[part 11 of 23: package /Cluster]
AUTOSAR XML (schema 4-3-0)
package /Cluster  (continued)
  7 x lin cluster, all with baudrate=19200, protocol-name=LIN, protocol-version=2.0:  (continued)
    Klima_LIN3
      lin physical channel CHNL: comm-connectors=CN_Klima_LIN3
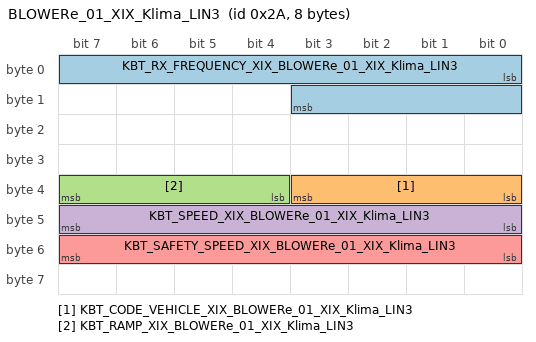
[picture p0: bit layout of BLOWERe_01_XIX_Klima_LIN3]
        frame BLOWERe_01_XIX_Klima_LIN3: id 0x2A, from Klima, frame-length=8, lin-checksum=ENHANCED
          pdu BLOWERe_01_XIX_Klima_LIN3: length=8, unused-bit-pattern=0
            signal KBT_RX_FREQUENCY_XIX_BLOWERe_01_XIX_Klima_LIN3: start 0, 12 bit, little-endian, data-type-policy=OVERRIDE, i-signal-type=PRIMITIVE, base-type=BT_KBT_RX_FREQUENCY, compu {phys=raw+150 for raw 0..1896, 4095=Cxfff_ungueltig (CM_KBT_RX_FREQUENCY_Cxfff_ungueltig); unit Unit_KiloHertz}, range phys 150..2046 Unit_KiloHertz, raw 0..4095, unit=Unit_KiloHertz, transfer-property=PENDING  # Radio Empfangsfrequenz bei AM_Empfang
            signal KBT_CODE_VEHICLE_XIX_BLOWERe_01_XIX_Klima_LIN3: start 32, 4 bit, little-endian, data-type-policy=OVERRIDE, i-signal-type=PRIMITIVE, init-value=0, base-type=BT_KBT_CODE_VEHICLE, compu {0=Cx0_Init (CM_KBT_CODE_VEHICLE_Cx0_Init), 1=Cx1_Q7_NF (CM_KBT_CODE_VEHICLE_Cx1_Q7_NF), 2=Cx2_B9 (CM_KBT_CODE_VEHICLE_Cx2_B9), 3=Cx3_D5 (CM_KBT_CODE_VEHICLE_Cx3_D5), 4=Cx4_C8 (CM_KBT_CODE_VEHICLE_Cx4_C8), 5=Cx5_Q5_NF (CM_KBT_CODE_VEHICLE_Cx5_Q5_NF), 6=Cx6_MSS (CM_KBT_CODE_VEHICLE_Cx6_MSS), 7=Cx7_Konzern_Fahrzeug (CM_KBT_CODE_VEHICLE_Cx7_Konzern_Fahrzeug)}, range raw 0..7, transfer-property=PENDING  # Vorgabe des Betriebszustandes für das Frischluftgebläse BLDC
            signal KBT_RAMP_XIX_BLOWERe_01_XIX_Klima_LIN3: start 36, 4 bit, little-endian, data-type-policy=OVERRIDE, i-signal-type=PRIMITIVE, base-type=BT_KBT_RAMP, compu {phys=raw*100+100 for raw 0..15; unit Unit_MinutInver}, range phys 100..1600 Unit_MinutInver, raw 0..15, unit=Unit_MinutInver, transfer-property=PENDING  # Vorgabe Rampenzeitkonstante für das Frischluftgebläse BLDC
            signal KBT_SPEED_XIX_BLOWERe_01_XIX_Klima_LIN3: start 40, 8 bit, little-endian, data-type-policy=OVERRIDE, i-signal-type=PRIMITIVE, init-value=1, base-type=BT_KBT_SPEED, invalid-value=Invalid_KBT_SPEED_XIX_BLOWERe_01_XIX_Klima_LIN3:255, compu {0=Cx0_Sofort_Abschaltung_ohne_Rampe (CM_KBT_SPEED_Cx0_Sofort_Abschaltung_ohne_Rampe), 1=Cx1_Abschaltung_mit_Rampe (CM_KBT_SPEED_Cx1_Abschaltung_mit_Rampe), phys=raw*20 for raw 20..253, 254=Cxfe_reserviert (CM_KBT_SPEED_Cxfe_reserviert), 255=Cxff_Fehler (CM_KBT_SPEED_Cxff_Fehler); unit Unit_MinutInver}, range phys 400..5060 Unit_MinutInver, raw 0..255, unit=Unit_MinutInver, transfer-property=PENDING  # Vorgabe Sollwert Motordrehzahl für das Frischluftgebläse BLDC
            signal KBT_SAFETY_SPEED_XIX_BLOWERe_01_XIX_Klima_LIN3: start 48, 8 bit, little-endian, data-type-policy=OVERRIDE, i-signal-type=PRIMITIVE, init-value=200, base-type=BT_KBT_SAFETY_SPEED, invalid-value=Invalid_KBT_SAFETY_SPEED_XIX_BLOWERe_01_XIX_Klima_LIN3:255, compu {phys=raw*20 for raw 0..253, 254=Cxfe_reserviert (CM_KBT_SAFETY_SPEED_Cxfe_reserviert), 255=Cxff_Fehler (CM_KBT_SAFETY_SPEED_Cxff_Fehler); unit Unit_MinutInver}, range phys 0..5060 Unit_MinutInver, raw 0..255, unit=Unit_MinutInver, transfer-property=PENDING  # Vorgabe Sollwert Notlaufmotordrehzahl für das Frischluftgebläse BLDC
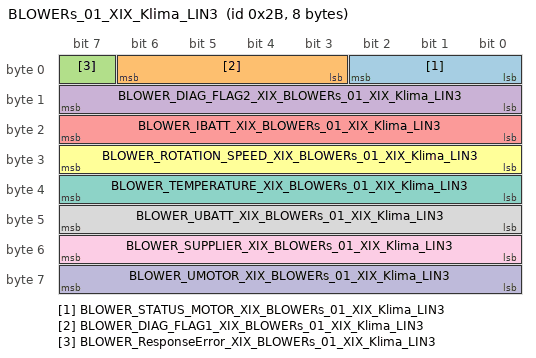
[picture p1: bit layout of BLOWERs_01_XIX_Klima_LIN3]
        frame BLOWERs_01_XIX_Klima_LIN3: id 0x2B, to Klima, frame-length=8, lin-checksum=ENHANCED
          pdu BLOWERs_01_XIX_Klima_LIN3: length=8, unused-bit-pattern=0
            signal BLOWER_STATUS_MOTOR_XIX_BLOWERs_01_XIX_Klima_LIN3: start 0, 3 bit, little-endian, data-type-policy=OVERRIDE, i-signal-type=PRIMITIVE, init-value=0, base-type=BT_BLOWER_STATUS_MOTOR, compu {0=Cx0_Init (CM_BLOWER_STATUS_MOTOR_Cx0_Init), 1=Cx1_Strombegrenzung_aktiv (CM_BLOWER_STATUS_MOTOR_Cx1_Strombegrenzung_aktiv), 2=Cx2_Sollwert_erreicht (CM_BLOWER_STATUS_MOTOR_Cx2_Sollwert_erreicht), 4=Cx4_Notlauf_aktiviert (CM_BLOWER_STATUS_MOTOR_Cx4_Notlauf_aktiviert)}, range raw 0..4, transfer-property=PENDING, to Klima(timeout 3.5 s)  # Status Motor des Frischlufgebläse BLDC
            signal BLOWER_DIAG_FLAG1_XIX_BLOWERs_01_XIX_Klima_LIN3: start 3, 4 bit, little-endian, data-type-policy=OVERRIDE, i-signal-type=PRIMITIVE, base-type=BT_BLOWER_DIAG_FLAG1, compu {0=Cx0_Init (CM_BLOWER_DIAG_FLAG1_Cx0_Init), 1=Cx1_Kurzschluss (CM_BLOWER_DIAG_FLAG1_Cx1_Kurzschluss), 2=Cx2_Fehler_Temperatur_Sensor (CM_BLOWER_DIAG_FLAG1_Cx2_Fehler_Temperatur_Sensor), 4=Cx4_Fehler_Brueckentreiber (CM_BLOWER_DIAG_FLAG1_Cx4_Fehler_Brueckentreiber), 8=Cx8_Brueckentreiber_Uebertemperatur (CM_BLOWER_DIAG_FLAG1_Cx8_Brueckentreiber_Uebertemperatur)}, range raw 0..8, transfer-property=PENDING, to Klima(timeout 3.5 s)  # Status Diagnose 1 des Frischluftgbläse BLDC
            signal BLOWER_ResponseError_XIX_BLOWERs_01_XIX_Klima_LIN3: start 7, 1 bit, little-endian, data-type-policy=OVERRIDE, i-signal-type=PRIMITIVE, init-value=0, base-type=BT_BLOWER_ResponseError, invalid-value=Invalid_BLOWER_ResponseError_XIX_BLOWERs_01_XIX_Klima_LIN3:1, compu {0=Cx0_kein_Fehler (CM_BLOWER_ResponseError_Cx0_kein_Fehler), 1=Cx1_Fehler (CM_BLOWER_ResponseError_Cx1_Fehler)}, range raw 0..1, transfer-property=PENDING, to Klima(timeout 3.5 s)  # siehe LIN2.0-Specification (Darf nicht über ein Fehlergueltigkeitsbit abgesichtert werden!)
            signal BLOWER_DIAG_FLAG2_XIX_BLOWERs_01_XIX_Klima_LIN3: start 8, 8 bit, little-endian, data-type-policy=OVERRIDE, i-signal-type=PRIMITIVE, base-type=BT_BLOWER_DIAG_FLAG2, compu {0=Cx0_Init (CM_BLOWER_DIAG_FLAG2_Cx0_Init), 1=Cx1_interner_Fehler_detektiert_Notabschaltung (CM_BLOWER_DIAG_FLAG2_Cx1_interner_Fehler_detektiert_Notabschaltung), 2=Cx2_Blockade_Motor (CM_BLOWER_DIAG_FLAG2_Cx2_Blockade_Motor), 4=Cx4_Uebertemperatur (CM_BLOWER_DIAG_FLAG2_Cx4_Uebertemperatur), 8=Cx8_Ueberstrom_Motor (CM_BLOWER_DIAG_FLAG2_Cx8_Ueberstrom_Motor), 16=Cx10_Ueberstrom_Batterie (CM_BLOWER_DIAG_FLAG2_Cx10_Ueberstrom_Batterie), 32=Cx20_Strom_Offset_Fehler (CM_BLOWER_DIAG_FLAG2_Cx20_Strom_Offset_Fehler), 64=Cx40_Ueberspannung_Abschaltung (CM_BLOWER_DIAG_FLAG2_Cx40_Ueberspannung_Abschaltung), 128=Cx80_Unterspannung_Abschaltung (CM_BLOWER_DIAG_FLAG2_Cx80_Unterspannung_Abschaltung)}, range raw 0..128, transfer-property=PENDING, to Klima(timeout 3.5 s)  # Status Diagnose 2 des Frischluftgbläse BLDC
            signal BLOWER_IBATT_XIX_BLOWERs_01_XIX_Klima_LIN3: start 16, 8 bit, little-endian, data-type-policy=OVERRIDE, i-signal-type=PRIMITIVE, base-type=BT_BLOWER_IBATT, compu {phys=raw*0.15 for raw 0..253, 254=Cxfe_kein_Messwert_verfuegbar (CM_BLOWER_IBATT_Cxfe_kein_Messwert_verfuegbar), 255=Cxff_Fehler_Strommesseinrichtung (CM_BLOWER_IBATT_Cxff_Fehler_Strommesseinrichtung); unit Unit_Amper}, range phys 0..37.95 Unit_Amper, raw 0..255, unit=Unit_Amper, transfer-property=PENDING, to Klima(timeout 3.5 s)  # Stromaufnahme des Frischluftgbläse BLDC
            signal BLOWER_ROTATION_SPEED_XIX_BLOWERs_01_XIX_Klima_LIN3: start 24, 8 bit, little-endian, data-type-policy=OVERRIDE, i-signal-type=PRIMITIVE, base-type=BT_BLOWER_ROTATION_SPEED, compu {phys=raw*20 for raw 0..253, 254=Cxfe_kein_Messwert_verfuegbar (CM_BLOWER_ROTATION_SPEED_Cxfe_kein_Messwert_verfuegbar), 255=Cxff_Fehler_Drehzahlmesseinrichtung (CM_BLOWER_ROTATION_SPEED_Cxff_Fehler_Drehzahlmesseinrichtung); unit Unit_MinutInver}, range phys 0..5060 Unit_MinutInver, raw 0..255, unit=Unit_MinutInver, transfer-property=PENDING, to Klima(timeout 3.5 s)  # Drehzahl des Frischluftgebläse BLDC
            signal BLOWER_TEMPERATURE_XIX_BLOWERs_01_XIX_Klima_LIN3: start 32, 8 bit, little-endian, data-type-policy=OVERRIDE, i-signal-type=PRIMITIVE, init-value=0, base-type=BT_BLOWER_TEMPERATURE, invalid-value=Invalid_BLOWER_TEMPERATURE_XIX_BLOWERs_01_XIX_Klima_LIN3:255, compu {phys=raw-40 for raw 0..190, 254=Cxfe_kein_Messwert_verfuegbar (CM_BLOWER_TEMPERATURE_Cxfe_kein_Messwert_verfuegbar), 255=Cxff_Fehler (CM_BLOWER_TEMPERATURE_Cxff_Fehler); unit Unit_DegreCelsi}, range phys -40..150 Unit_DegreCelsi, raw 0..255, unit=Unit_DegreCelsi, transfer-property=PENDING, to Klima(timeout 3.5 s)  # Temperatur des Frischluftgebläse BLDC
            signal BLOWER_UBATT_XIX_BLOWERs_01_XIX_Klima_LIN3: start 40, 8 bit, little-endian, data-type-policy=OVERRIDE, i-signal-type=PRIMITIVE, base-type=BT_BLOWER_UBATT, compu {phys=raw*0.1 for raw 0..253, 254=Cxfe_kein_Messwert_verfuegbar (CM_BLOWER_UBATT_Cxfe_kein_Messwert_verfuegbar), 255=Cxff_Fehler_Spannungsmesseinrichtung (CM_BLOWER_UBATT_Cxff_Fehler_Spannungsmesseinrichtung); unit Unit_Volt}, range phys 0..25.3 Unit_Volt, raw 0..255, unit=Unit_Volt, transfer-property=PENDING, to Klima(timeout 3.5 s)  # Spannung am Frischluftgebläse BLDC Ubatt (Klemme)
            signal BLOWER_SUPPLIER_XIX_BLOWERs_01_XIX_Klima_LIN3: start 48, 8 bit, little-endian, data-type-policy=OVERRIDE, i-signal-type=PRIMITIVE, init-value=0, base-type=BT_BLOWER_SUPPLIER, compu {0=Cx0_Init (CM_BLOWER_SUPPLIER_Cx0_Init), 31=Cx1f_BROSE (CM_BLOWER_SUPPLIER_Cx1f_BROSE), 37=Cx25_ASMO (CM_BLOWER_SUPPLIER_Cx25_ASMO), 64=Cx40_BOSCH (CM_BLOWER_SUPPLIER_Cx40_BOSCH)}, range raw 0..64, transfer-property=PENDING, to Klima(timeout 3.5 s)  # Hersteller-Nummer des Frischluftgebläse BLDC
            signal BLOWER_UMOTOR_XIX_BLOWERs_01_XIX_Klima_LIN3: start 56, 8 bit, little-endian, data-type-policy=OVERRIDE, i-signal-type=PRIMITIVE, base-type=BT_BLOWER_UMOTOR, compu {phys=raw*0.1 for raw 0..253, 254=Cxfe_kein_Messwert_verfuegbar (CM_BLOWER_UMOTOR_Cxfe_kein_Messwert_verfuegbar), 255=Cxff_Fehler_Spannungsmesseinrichtung (CM_BLOWER_UMOTOR_Cxff_Fehler_Spannungsmesseinrichtung); unit Unit_Volt}, range phys 0..25.3 Unit_Volt, raw 0..255, unit=Unit_Volt, transfer-property=PENDING, to Klima(timeout 3.5 s)  # Phasenspannung Motor des Frischluftgebläse BLDC
        frame BLOWERs_02_XIX_Klima_LIN3: id 0x2E, to Klima, frame-length=8, lin-checksum=ENHANCED
          pdu BLOWERs_02_XIX_Klima_LIN3: length=8, unused-bit-pattern=0
            signal BLOWER_TORQUE_XIX_BLOWERs_02_XIX_Klima_LIN3: start 0, 10 bit, little-endian, data-type-policy=OVERRIDE, i-signal-type=PRIMITIVE, init-value=1022, base-type=BT_BLOWER_TORQUE, invalid-value=Invalid_BLOWER_TORQUE_XIX_BLOWERs_02_XIX_Klima_LIN3:1023, compu {phys=raw*0.001 for raw 0..1021, 1022=Cx3fe_Init (CM_BLOWER_TORQUE_Cx3fe_Init), 1023=Cx3ff_Fehler (CM_BLOWER_TORQUE_Cx3ff_Fehler); unit Unit_NewtoMeter}, range phys 0..1.021 Unit_NewtoMeter, raw 0..1023, unit=Unit_NewtoMeter, transfer-property=PENDING, to Klima(timeout 3.5 s)  # Drehmoment des Frischluftgebläse BLDC
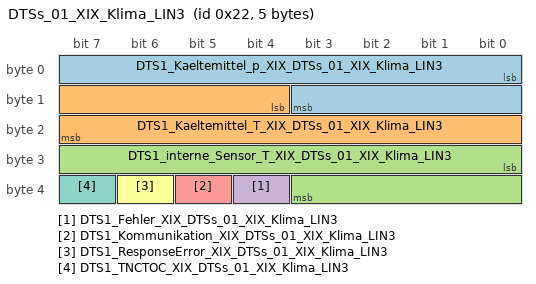
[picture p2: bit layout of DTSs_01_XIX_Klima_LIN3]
        frame DTSs_01_XIX_Klima_LIN3: id 0x22, to Klima, frame-length=5, lin-checksum=ENHANCED
          pdu DTSs_01_XIX_Klima_LIN3: length=5, unused-bit-pattern=0
            signal DTS1_Kaeltemittel_p_XIX_DTSs_01_XIX_Klima_LIN3: start 0, 12 bit, little-endian, data-type-policy=OVERRIDE, i-signal-type=PRIMITIVE, init-value=4094, base-type=BT_DTS1_Kaeltemittel_p, invalid-value=Invalid_DTS1_Kaeltemittel_p_XIX_DTSs_01_XIX_Klima_LIN3:4095, compu {phys=raw*0.0088 for raw 0..4093, 4094=Cxffe_Init (CM_DTS1_Kaeltemittel_p_Cxffe_Init), 4095=Cxfff_Fehler (CM_DTS1_Kaeltemittel_p_Cxfff_Fehler); unit Unit_Bar}, range phys 0..36.0184 Unit_Bar, raw 0..4095, unit=Unit_Bar, transfer-property=PENDING, to Klima(timeout 3.5 s)  # Kaetemitteldruck absolut
            signal DTS1_Kaeltemittel_T_XIX_DTSs_01_XIX_Klima_LIN3: start 12, 12 bit, little-endian, data-type-policy=OVERRIDE, i-signal-type=PRIMITIVE, init-value=4094, base-type=BT_DTS1_Kaeltemittel_T, invalid-value=Invalid_DTS1_Kaeltemittel_T_XIX_DTSs_01_XIX_Klima_LIN3:4095, compu {phys=raw*0.1-40 for raw 0..1900, 4094=Cxffe_Init (CM_DTS1_Kaeltemittel_T_Cxffe_Init), 4095=Cxfff_Fehler (CM_DTS1_Kaeltemittel_T_Cxfff_Fehler); unit Unit_DegreCelsi}, range phys -40..150 Unit_DegreCelsi, raw 0..4095, unit=Unit_DegreCelsi, transfer-property=PENDING, to Klima(timeout 3.5 s)  # Kältemitteltemperatur
            signal DTS1_interne_Sensor_T_XIX_DTSs_01_XIX_Klima_LIN3: start 24, 12 bit, little-endian, data-type-policy=OVERRIDE, i-signal-type=PRIMITIVE, init-value=4094, base-type=BT_DTS1_interne_Sensor_T, invalid-value=Invalid_DTS1_interne_Sensor_T_XIX_DTSs_01_XIX_Klima_LIN3:4095, compu {phys=raw*0.1-40 for raw 0..1800, 4094=Cxffe_Init (CM_DTS1_interne_Sensor_T_Cxffe_Init), 4095=Cxfff_Fehler (CM_DTS1_interne_Sensor_T_Cxfff_Fehler); unit Unit_DegreCelsi}, range phys -40..140 Unit_DegreCelsi, raw 0..4095, unit=Unit_DegreCelsi, transfer-property=PENDING, to Klima(timeout 3.5 s)  # interne Sensor-Temperatur
            signal DTS1_Fehler_XIX_DTSs_01_XIX_Klima_LIN3: start 36, 1 bit, little-endian, data-type-policy=OVERRIDE, i-signal-type=PRIMITIVE, init-value=0, base-type=BT_DTS1_Fehler, invalid-value=Invalid_DTS1_Fehler_XIX_DTSs_01_XIX_Klima_LIN3:1, compu {0=Cx0_kein_Fehler (CM_DTS1_Fehler_Cx0_kein_Fehler), 1=Cx1_Fehler (CM_DTS1_Fehler_Cx1_Fehler)}, range raw 0..1, transfer-property=PENDING, to Klima(timeout 3.5 s)  # Interner Sensorfehler
            signal DTS1_Kommunikation_XIX_DTSs_01_XIX_Klima_LIN3: start 37, 1 bit, little-endian, data-type-policy=OVERRIDE, i-signal-type=PRIMITIVE, init-value=0, base-type=BT_DTS1_Kommunikation, invalid-value=Invalid_DTS1_Kommunikation_XIX_DTSs_01_XIX_Klima_LIN3:1, compu {0=Cx0_kein_Fehler (CM_DTS1_Kommunikation_Cx0_kein_Fehler), 1=Cx1_Fehler (CM_DTS1_Kommunikation_Cx1_Fehler)}, range raw 0..1, transfer-property=PENDING, to Klima(timeout 3.5 s)  # Checksummenfehler
            signal DTS1_ResponseError_XIX_DTSs_01_XIX_Klima_LIN3: start 38, 1 bit, little-endian, data-type-policy=OVERRIDE, i-signal-type=PRIMITIVE, init-value=0, base-type=BT_DTS1_ResponseError, invalid-value=Invalid_DTS1_ResponseError_XIX_DTSs_01_XIX_Klima_LIN3:1, compu {0=Cx0_kein_Fehler (CM_DTS1_ResponseError_Cx0_kein_Fehler), 1=Cx1_Fehler (CM_DTS1_ResponseError_Cx1_Fehler)}, range raw 0..1, transfer-property=PENDING, to Klima(timeout 3.5 s)  # Response Error
            signal DTS1_TNCTOC_XIX_DTSs_01_XIX_Klima_LIN3: start 39, 1 bit, little-endian, data-type-policy=OVERRIDE, i-signal-type=PRIMITIVE, init-value=1, base-type=BT_DTS1_TNCTOC, compu {0=Cx0_DTC_test_completed_this_operation_cylce (CM_DTS1_TNCTOC_Cx0_DTC_test_completed_this_operation_cylce), 1=Cx1_DTC_test_not_completed_this_operation_cylce (CM_DTS1_TNCTOC_Cx1_DTC_test_not_completed_this_operation_cylce)}, range raw 0..1, transfer-property=PENDING, to Klima(timeout 3.5 s)  # testNotCompletedThisOperationCycle (TNCTOC)
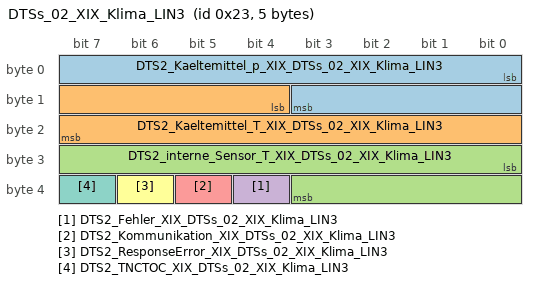
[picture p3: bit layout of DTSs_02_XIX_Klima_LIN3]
        frame DTSs_02_XIX_Klima_LIN3: id 0x23, to Klima, frame-length=5, lin-checksum=ENHANCED
          pdu DTSs_02_XIX_Klima_LIN3: length=5, unused-bit-pattern=0
            signal DTS2_Kaeltemittel_p_XIX_DTSs_02_XIX_Klima_LIN3: start 0, 12 bit, little-endian, data-type-policy=OVERRIDE, i-signal-type=PRIMITIVE, init-value=4094, base-type=BT_DTS2_Kaeltemittel_p, invalid-value=Invalid_DTS2_Kaeltemittel_p_XIX_DTSs_02_XIX_Klima_LIN3:4095, compu {phys=raw*0.0088 for raw 0..4093, 4094=Cxffe_Init (CM_DTS2_Kaeltemittel_p_Cxffe_Init), 4095=Cxfff_Fehler (CM_DTS2_Kaeltemittel_p_Cxfff_Fehler); unit Unit_Bar}, range phys 0..36.0184 Unit_Bar, raw 0..4095, unit=Unit_Bar, transfer-property=PENDING, to Klima(timeout 3.5 s)  # Kaetemitteldruck absolut
            signal DTS2_Kaeltemittel_T_XIX_DTSs_02_XIX_Klima_LIN3: start 12, 12 bit, little-endian, data-type-policy=OVERRIDE, i-signal-type=PRIMITIVE, init-value=4094, base-type=BT_DTS2_Kaeltemittel_T, invalid-value=Invalid_DTS2_Kaeltemittel_T_XIX_DTSs_02_XIX_Klima_LIN3:4095, compu {phys=raw*0.1-40 for raw 0..1900, 4094=Cxffe_Init (CM_DTS2_Kaeltemittel_T_Cxffe_Init), 4095=Cxfff_Fehler (CM_DTS2_Kaeltemittel_T_Cxfff_Fehler); unit Unit_DegreCelsi}, range phys -40..150 Unit_DegreCelsi, raw 0..4095, unit=Unit_DegreCelsi, transfer-property=PENDING, to Klima(timeout 3.5 s)  # Kältemitteltemperatur
            signal DTS2_interne_Sensor_T_XIX_DTSs_02_XIX_Klima_LIN3: start 24, 12 bit, little-endian, data-type-policy=OVERRIDE, i-signal-type=PRIMITIVE, init-value=4094, base-type=BT_DTS2_interne_Sensor_T, invalid-value=Invalid_DTS2_interne_Sensor_T_XIX_DTSs_02_XIX_Klima_LIN3:4095, compu {phys=raw*0.1-40 for raw 0..1800, 4094=Cxffe_Init (CM_DTS2_interne_Sensor_T_Cxffe_Init), 4095=Cxfff_Fehler (CM_DTS2_interne_Sensor_T_Cxfff_Fehler); unit Unit_DegreCelsi}, range phys -40..140 Unit_DegreCelsi, raw 0..4095, unit=Unit_DegreCelsi, transfer-property=PENDING, to Klima(timeout 3.5 s)  # interne Sensor-Temperatur
            signal DTS2_Fehler_XIX_DTSs_02_XIX_Klima_LIN3: start 36, 1 bit, little-endian, data-type-policy=OVERRIDE, i-signal-type=PRIMITIVE, init-value=0, base-type=BT_DTS2_Fehler, invalid-value=Invalid_DTS2_Fehler_XIX_DTSs_02_XIX_Klima_LIN3:1, compu {0=Cx0_kein_Fehler (CM_DTS2_Fehler_Cx0_kein_Fehler), 1=Cx1_Fehler (CM_DTS2_Fehler_Cx1_Fehler)}, range raw 0..1, transfer-property=PENDING, to Klima(timeout 3.5 s)  # Interner Sensorfehler
            signal DTS2_Kommunikation_XIX_DTSs_02_XIX_Klima_LIN3: start 37, 1 bit, little-endian, data-type-policy=OVERRIDE, i-signal-type=PRIMITIVE, init-value=0, base-type=BT_DTS2_Kommunikation, invalid-value=Invalid_DTS2_Kommunikation_XIX_DTSs_02_XIX_Klima_LIN3:1, compu {0=Cx0_kein_Fehler (CM_DTS2_Kommunikation_Cx0_kein_Fehler), 1=Cx1_Fehler (CM_DTS2_Kommunikation_Cx1_Fehler)}, range raw 0..1, transfer-property=PENDING, to Klima(timeout 3.5 s)  # Checksummenfehler
            signal DTS2_ResponseError_XIX_DTSs_02_XIX_Klima_LIN3: start 38, 1 bit, little-endian, data-type-policy=OVERRIDE, i-signal-type=PRIMITIVE, init-value=0, base-type=BT_DTS2_ResponseError, invalid-value=Invalid_DTS2_ResponseError_XIX_DTSs_02_XIX_Klima_LIN3:1, compu {0=Cx0_normal (CM_DTS2_ResponseError_Cx0_normal), 1=Cx1_Fehler (CM_DTS2_ResponseError_Cx1_Fehler)}, range raw 0..1, transfer-property=PENDING, to Klima(timeout 3.5 s)  # siehe LIN2.0-Specification (Darf nicht über ein Fehlergueltigkeitsbit abgesichtert werden!)
            signal DTS2_TNCTOC_XIX_DTSs_02_XIX_Klima_LIN3: start 39, 1 bit, little-endian, data-type-policy=OVERRIDE, i-signal-type=PRIMITIVE, init-value=1, base-type=BT_DTS2_TNCTOC, compu {0=Cx0_DTC_test_completed_this_operation_cylce (CM_DTS2_TNCTOC_Cx0_DTC_test_completed_this_operation_cylce), 1=Cx1_DTC_test_not_completed_this_operation_cylce (CM_DTS2_TNCTOC_Cx1_DTC_test_not_completed_this_operation_cylce)}, range raw 0..1, transfer-property=PENDING, to Klima(timeout 3.5 s)  # testNotCompletedThisOperationCycle (TNCTOC)
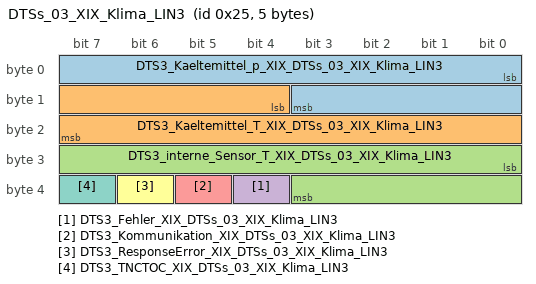
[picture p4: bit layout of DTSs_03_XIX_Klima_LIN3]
        frame DTSs_03_XIX_Klima_LIN3: id 0x25, to Klima, frame-length=5, lin-checksum=ENHANCED
          pdu DTSs_03_XIX_Klima_LIN3: length=5, unused-bit-pattern=0
            signal DTS3_Kaeltemittel_p_XIX_DTSs_03_XIX_Klima_LIN3: start 0, 12 bit, little-endian, data-type-policy=OVERRIDE, i-signal-type=PRIMITIVE, init-value=4094, base-type=BT_DTS3_Kaeltemittel_p, invalid-value=Invalid_DTS3_Kaeltemittel_p_XIX_DTSs_03_XIX_Klima_LIN3:4095, compu {phys=raw*0.0088 for raw 0..4093, 4094=Cxffe_Init (CM_DTS3_Kaeltemittel_p_Cxffe_Init), 4095=Cxfff_Fehler (CM_DTS3_Kaeltemittel_p_Cxfff_Fehler); unit Unit_Bar}, range phys 0..36.0184 Unit_Bar, raw 0..4095, unit=Unit_Bar, transfer-property=PENDING, to Klima(timeout 3.5 s)  # Kaetemitteldruck absolut
            signal DTS3_Kaeltemittel_T_XIX_DTSs_03_XIX_Klima_LIN3: start 12, 12 bit, little-endian, data-type-policy=OVERRIDE, i-signal-type=PRIMITIVE, init-value=4094, base-type=BT_DTS3_Kaeltemittel_T, invalid-value=Invalid_DTS3_Kaeltemittel_T_XIX_DTSs_03_XIX_Klima_LIN3:4095, compu {phys=raw*0.1-40 for raw 0..1900, 4094=Cxffe_Init (CM_DTS3_Kaeltemittel_T_Cxffe_Init), 4095=Cxfff_Fehler (CM_DTS3_Kaeltemittel_T_Cxfff_Fehler); unit Unit_DegreCelsi}, range phys -40..150 Unit_DegreCelsi, raw 0..4095, unit=Unit_DegreCelsi, transfer-property=PENDING, to Klima(timeout 3.5 s)  # Kältemitteltemperatur
            signal DTS3_interne_Sensor_T_XIX_DTSs_03_XIX_Klima_LIN3: start 24, 12 bit, little-endian, data-type-policy=OVERRIDE, i-signal-type=PRIMITIVE, init-value=4094, base-type=BT_DTS3_interne_Sensor_T, invalid-value=Invalid_DTS3_interne_Sensor_T_XIX_DTSs_03_XIX_Klima_LIN3:4095, compu {phys=raw*0.1-40 for raw 0..1800, 4094=Cxffe_Init (CM_DTS3_interne_Sensor_T_Cxffe_Init), 4095=Cxfff_Fehler (CM_DTS3_interne_Sensor_T_Cxfff_Fehler); unit Unit_DegreCelsi}, range phys -40..140 Unit_DegreCelsi, raw 0..4095, unit=Unit_DegreCelsi, transfer-property=PENDING, to Klima(timeout 3.5 s)  # interne Sensor-Temperatur
            signal DTS3_Fehler_XIX_DTSs_03_XIX_Klima_LIN3: start 36, 1 bit, little-endian, data-type-policy=OVERRIDE, i-signal-type=PRIMITIVE, init-value=0, base-type=BT_DTS3_Fehler, invalid-value=Invalid_DTS3_Fehler_XIX_DTSs_03_XIX_Klima_LIN3:1, compu {0=Cx0_kein_Fehler (CM_DTS3_Fehler_Cx0_kein_Fehler), 1=Cx1_Fehler (CM_DTS3_Fehler_Cx1_Fehler)}, range raw 0..1, transfer-property=PENDING, to Klima(timeout 3.5 s)  # Interner Sensorfehler
            signal DTS3_Kommunikation_XIX_DTSs_03_XIX_Klima_LIN3: start 37, 1 bit, little-endian, data-type-policy=OVERRIDE, i-signal-type=PRIMITIVE, init-value=0, base-type=BT_DTS3_Kommunikation, invalid-value=Invalid_DTS3_Kommunikation_XIX_DTSs_03_XIX_Klima_LIN3:1, compu {0=Cx0_kein_Fehler (CM_DTS3_Kommunikation_Cx0_kein_Fehler), 1=Cx1_Fehler (CM_DTS3_Kommunikation_Cx1_Fehler)}, range raw 0..1, transfer-property=PENDING, to Klima(timeout 3.5 s)  # Checksummenfehler
            signal DTS3_ResponseError_XIX_DTSs_03_XIX_Klima_LIN3: start 38, 1 bit, little-endian, data-type-policy=OVERRIDE, i-signal-type=PRIMITIVE, init-value=0, base-type=BT_DTS3_ResponseError, invalid-value=Invalid_DTS3_ResponseError_XIX_DTSs_03_XIX_Klima_LIN3:1, compu {0=Cx0_normal (CM_DTS3_ResponseError_Cx0_normal), 1=Cx1_Fehler (CM_DTS3_ResponseError_Cx1_Fehler)}, range raw 0..1, transfer-property=PENDING, to Klima(timeout 3.5 s)  # siehe LIN2.0-Specification (Darf nicht über ein Fehlergueltigkeitsbit abgesichtert werden!)
            signal DTS3_TNCTOC_XIX_DTSs_03_XIX_Klima_LIN3: start 39, 1 bit, little-endian, data-type-policy=OVERRIDE, i-signal-type=PRIMITIVE, init-value=1, base-type=BT_DTS3_TNCTOC, compu {0=Cx0_DTC_test_completed_this_operation_cylce (CM_DTS3_TNCTOC_Cx0_DTC_test_completed_this_operation_cylce), 1=Cx1_DTC_test_not_completed_this_operation_cylce (CM_DTS3_TNCTOC_Cx1_DTC_test_not_completed_this_operation_cylce)}, range raw 0..1, transfer-property=PENDING, to Klima(timeout 3.5 s)  # testNotCompletedThisOperationCycle (TNCTOC)
        frame EKK4s_01_XIX_Klima_LIN3: id 0xB, to Klima, frame-length=8, lin-checksum=ENHANCED
          pdu EKK4s_01_XIX_Klima_LIN3: length=8, unused-bit-pattern=0
            signal EKK4_MUX_Err_Ind_XIX_EKK4s_01_XIX_Klima_LIN3: start 0, 2 bit, little-endian, data-type-policy=OVERRIDE, i-signal-type=PRIMITIVE, init-value=0, base-type=BT_EKK4_MUX_Err_Ind, compu {0=Cx0_Kennnummer_1_7_von_Err_Ind_Err (CM_EKK4_MUX_Err_Ind_Cx0_Kennnummer_1_7_von_Err_Ind_Err), 1=Cx1_Kennnummer_8_14_von_Err_Ind_Err (CM_EKK4_MUX_Err_Ind_Cx1_Kennnummer_8_14_von_Err_Ind_Err), 2=Cx2_Kennnummer_15_21_von_Err_Ind_Err (CM_EKK4_MUX_Err_Ind_Cx2_Kennnummer_15_21_von_Err_Ind_Err), 3=Cx3_Kennnummer_22_28_von_Err_Ind_Err (CM_EKK4_MUX_Err_Ind_Cx3_Kennnummer_22_28_von_Err_Ind_Err)}, range raw 0..3, transfer-property=PENDING, to Klima(timeout 3.5 s)  # Das Signal MUX_Err_Ind ist der Multiplexer für die gemultiplexten Signale Err_Ind_Nr_n_n+7_n+14_n+21.
            signal EKK4_Err_Ind_Nr_1_8_15_22_XIX_EKK4s_01_XIX_Klima_LIN3: start 2, 2 bit, little-endian, data-type-policy=OVERRIDE, i-signal-type=PRIMITIVE, init-value=0, base-type=BT_EKK4_Err_Ind_Nr_1_8_15_22, compu {0=Cx0_TNCTOC (CM_EKK4_Err_Ind_Nr_1_8_15_22_Cx0_TNCTOC), 1=Cx1_TP_TC (CM_EKK4_Err_Ind_Nr_1_8_15_22_Cx1_TP_TC), 2=Cx2_not_supported (CM_EKK4_Err_Ind_Nr_1_8_15_22_Cx2_not_supported), 3=Cx3_TF_TC (CM_EKK4_Err_Ind_Nr_1_8_15_22_Cx3_TF_TC)}, range raw 0..3, transfer-property=PENDING, to Klima(timeout 3.5 s)  # Über die gemultiplexten Signale Err_Ind_Nr_n_n+7_n+14_n+21 werden die Fehlerzustände der einzelnen Fehlerorte ausgegeben. Das zugehörige Multiplexsignal lautet MUX_Err_Ind.
            signal EKK4_Err_Ind_Nr_2_9_16_23_XIX_EKK4s_01_XIX_Klima_LIN3: start 4, 2 bit, little-endian, data-type-policy=OVERRIDE, i-signal-type=PRIMITIVE, init-value=0, base-type=BT_EKK4_Err_Ind_Nr_2_9_16_23, compu {0=Cx0_TNCTOC (CM_EKK4_Err_Ind_Nr_2_9_16_23_Cx0_TNCTOC), 1=Cx1_TP_TC (CM_EKK4_Err_Ind_Nr_2_9_16_23_Cx1_TP_TC), 2=Cx2_not_supported (CM_EKK4_Err_Ind_Nr_2_9_16_23_Cx2_not_supported), 3=Cx3_TF_TC (CM_EKK4_Err_Ind_Nr_2_9_16_23_Cx3_TF_TC)}, range raw 0..3, transfer-property=PENDING, to Klima(timeout 3.5 s)  # Über die gemultiplexten Signale Err_Ind_Nr_n_n+7_n+14_n+21 werden die Fehlerzustände der einzelnen Fehlerorte ausgegeben. Das zugehörige Multiplexsignal lautet MUX_Err_Ind.
            signal EKK4_Err_Ind_Nr_3_10_17_24_XIX_EKK4s_01_XIX_Klima_LIN3: start 6, 2 bit, little-endian, data-type-policy=OVERRIDE, i-signal-type=PRIMITIVE, init-value=0, base-type=BT_EKK4_Err_Ind_Nr_3_10_17_24, compu {0=Cx0_TNCTOC (CM_EKK4_Err_Ind_Nr_3_10_17_24_Cx0_TNCTOC), 1=Cx1_TP_TC (CM_EKK4_Err_Ind_Nr_3_10_17_24_Cx1_TP_TC), 2=Cx2_not_supported (CM_EKK4_Err_Ind_Nr_3_10_17_24_Cx2_not_supported), 3=Cx3_TF_TC (CM_EKK4_Err_Ind_Nr_3_10_17_24_Cx3_TF_TC)}, range raw 0..3, transfer-property=PENDING, to Klima(timeout 3.5 s)  # Über die gemultiplexten Signale Err_Ind_Nr_n_n+7_n+14_n+21 werden die Fehlerzustände der einzelnen Fehlerorte ausgegeben. Das zugehörige Multiplexsignal lautet MUX_Err_Ind.
            signal EKK4_Err_Ind_Nr_4_11_18_25_XIX_EKK4s_01_XIX_Klima_LIN3: start 8, 2 bit, little-endian, data-type-policy=OVERRIDE, i-signal-type=PRIMITIVE, init-value=0, base-type=BT_EKK4_Err_Ind_Nr_4_11_18_25, compu {0=Cx0_TNCTOC (CM_EKK4_Err_Ind_Nr_4_11_18_25_Cx0_TNCTOC), 1=Cx1_TP_TC (CM_EKK4_Err_Ind_Nr_4_11_18_25_Cx1_TP_TC), 2=Cx2_not_supported (CM_EKK4_Err_Ind_Nr_4_11_18_25_Cx2_not_supported), 3=Cx3_TF_TC (CM_EKK4_Err_Ind_Nr_4_11_18_25_Cx3_TF_TC)}, range raw 0..3, transfer-property=PENDING, to Klima(timeout 3.5 s)  # Über die gemultiplexten Signale Err_Ind_Nr_n_n+7_n+14_n+21 werden die Fehlerzustände der einzelnen Fehlerorte ausgegeben. Das zugehörige Multiplexsignal lautet MUX_Err_Ind.
            signal EKK4_Err_Ind_Nr_5_12_19_26_XIX_EKK4s_01_XIX_Klima_LIN3: start 10, 2 bit, little-endian, data-type-policy=OVERRIDE, i-signal-type=PRIMITIVE, init-value=0, base-type=BT_EKK4_Err_Ind_Nr_5_12_19_26, compu {0=Cx0_TNCTOC (CM_EKK4_Err_Ind_Nr_5_12_19_26_Cx0_TNCTOC), 1=Cx1_TP_TC (CM_EKK4_Err_Ind_Nr_5_12_19_26_Cx1_TP_TC), 2=Cx2_not_supported (CM_EKK4_Err_Ind_Nr_5_12_19_26_Cx2_not_supported), 3=Cx3_TF_TC (CM_EKK4_Err_Ind_Nr_5_12_19_26_Cx3_TF_TC)}, range raw 0..3, transfer-property=PENDING, to Klima(timeout 3.5 s)  # Über die gemultiplexten Signale Err_Ind_Nr_n_n+7_n+14_n+21 werden die Fehlerzustände der einzelnen Fehlerorte ausgegeben. Das zugehörige Multiplexsignal lautet MUX_Err_Ind.
            signal EKK4_Err_Ind_Nr_6_13_20_27_XIX_EKK4s_01_XIX_Klima_LIN3: start 12, 2 bit, little-endian, data-type-policy=OVERRIDE, i-signal-type=PRIMITIVE, init-value=0, base-type=BT_EKK4_Err_Ind_Nr_6_13_20_27, compu {0=Cx0_TNCTOC (CM_EKK4_Err_Ind_Nr_6_13_20_27_Cx0_TNCTOC), 1=Cx1_TP_TC (CM_EKK4_Err_Ind_Nr_6_13_20_27_Cx1_TP_TC), 2=Cx2_not_supported (CM_EKK4_Err_Ind_Nr_6_13_20_27_Cx2_not_supported), 3=Cx3_TF_TC (CM_EKK4_Err_Ind_Nr_6_13_20_27_Cx3_TF_TC)}, range raw 0..3, transfer-property=PENDING, to Klima(timeout 3.5 s)  # Über die gemultiplexten Signale Err_Ind_Nr_n_n+7_n+14_n+21 werden die Fehlerzustände der einzelnen Fehlerorte ausgegeben. Das zugehörige Multiplexsignal lautet MUX_Err_Ind.
            signal EKK4_Err_Ind_Nr_7_14_21_28_XIX_EKK4s_01_XIX_Klima_LIN3: start 14, 2 bit, little-endian, data-type-policy=OVERRIDE, i-signal-type=PRIMITIVE, init-value=0, base-type=BT_EKK4_Err_Ind_Nr_7_14_21_28, compu {0=Cx0_TNCTOC (CM_EKK4_Err_Ind_Nr_7_14_21_28_Cx0_TNCTOC), 1=Cx1_TP_TC (CM_EKK4_Err_Ind_Nr_7_14_21_28_Cx1_TP_TC), 2=Cx2_not_supported (CM_EKK4_Err_Ind_Nr_7_14_21_28_Cx2_not_supported), 3=Cx3_TF_TC (CM_EKK4_Err_Ind_Nr_7_14_21_28_Cx3_TF_TC)}, range raw 0..3, transfer-property=PENDING, to Klima(timeout 3.5 s)  # Über die gemultiplexten Signale Err_Ind_Nr_n_n+7_n+14_n+21 werden die Fehlerzustände der einzelnen Fehlerorte ausgegeben. Das zugehörige Multiplexsignal lautet MUX_Err_Ind.
            signal EKK4_INV_TEMP_XIX_EKK4s_01_XIX_Klima_LIN3: start 16, 8 bit, little-endian, data-type-policy=OVERRIDE, i-signal-type=PRIMITIVE, init-value=254, base-type=BT_EKK4_INV_TEMP, invalid-value=Invalid_EKK4_INV_TEMP_XIX_EKK4s_01_XIX_Klima_LIN3:255, compu {phys=raw-60 for raw 0..253, 254=Cxfe_Init (CM_EKK4_INV_TEMP_Cxfe_Init), 255=Cxff_Fehler (CM_EKK4_INV_TEMP_Cxff_Fehler); unit Unit_DegreCelsi}, range phys -60..193 Unit_DegreCelsi, raw 0..255, unit=Unit_DegreCelsi, transfer-property=PENDING, to Klima(timeout 3.5 s)  # Inverter temperature. The range of inverter temperature which can be guaranteed is -126 to 127 degrees
            signal EKK4_INPUT_CURRENT_XIX_EKK4s_01_XIX_Klima_LIN3: start 24, 8 bit, little-endian, data-type-policy=OVERRIDE, i-signal-type=PRIMITIVE, init-value=254, base-type=BT_EKK4_INPUT_CURRENT, invalid-value=Invalid_EKK4_INPUT_CURRENT_XIX_EKK4s_01_XIX_Klima_LIN3:255, compu {phys=raw*0.25 for raw 0..253, 254=Cxfe_Init (CM_EKK4_INPUT_CURRENT_Cxfe_Init), 255=Cxff_Fehler (CM_EKK4_INPUT_CURRENT_Cxff_Fehler); unit Unit_Amper}, range phys 0..63.25 Unit_Amper, raw 0..255, unit=Unit_Amper, transfer-property=PENDING, to Klima(timeout 3.5 s)  # Compressor input current
            signal EKK4_HIGH_VOLTAGE_XIX_EKK4s_01_XIX_Klima_LIN3: start 32, 9 bit, little-endian, data-type-policy=OVERRIDE, i-signal-type=PRIMITIVE, init-value=510, base-type=BT_EKK4_HIGH_VOLTAGE, invalid-value=Invalid_EKK4_HIGH_VOLTAGE_XIX_EKK4s_01_XIX_Klima_LIN3:511, compu {phys=raw*2 for raw 0..509, 510=Cx1fe_Init (CM_EKK4_HIGH_VOLTAGE_Cx1fe_Init), 511=Cx1ff_Fehler (CM_EKK4_HIGH_VOLTAGE_Cx1ff_Fehler); unit Unit_Volt}, range phys 0..1018 Unit_Volt, raw 0..511, unit=Unit_Volt, transfer-property=PENDING, to Klima(timeout 3.5 s)  # Supplied High Voltage
            signal EKK4_Q_High_Voltage_XIX_EKK4s_01_XIX_Klima_LIN3: start 41, 1 bit, little-endian, data-type-policy=OVERRIDE, i-signal-type=PRIMITIVE, init-value=0, base-type=BT_EKK4_Q_High_Voltage, compu {0=Cx0_invalid (CM_EKK4_Q_High_Voltage_Cx0_invalid), 1=Cx1_valid (CM_EKK4_Q_High_Voltage_Cx1_valid)}, range raw 0..1, transfer-property=PENDING, to Klima(timeout 3.5 s)  # Kennzeichung einer durch eine abgeschlossene Diagnose der HV-Spannungssensoren verifizierten Wertigkeit des Signals <EKK4s_01>High_Voltage
            signal EKK4_Fehler_AE_XIX_EKK4s_01_XIX_Klima_LIN3: start 42, 2 bit, little-endian, data-type-policy=OVERRIDE, i-signal-type=PRIMITIVE, init-value=2, base-type=BT_EKK4_Fehler_AE, compu {0=Cx0_kein_Fehler_AE (CM_EKK4_Fehler_AE_Cx0_kein_Fehler_AE), 1=Cx1_Fehler_AE (CM_EKK4_Fehler_AE_Cx1_Fehler_AE), 2=Cx2_Init (CM_EKK4_Fehler_AE_Cx2_Init), 3=Cx3_keine_AE_angefordert (CM_EKK4_Fehler_AE_Cx3_keine_AE_angefordert)}, range raw 0..3, transfer-property=PENDING, to Klima(timeout 3.5 s)  # Fehlerstatus der aktiven Entladung des Klimakompressors
            signal EKK4_Match_XIX_EKK4s_01_XIX_Klima_LIN3: start 44, 2 bit, little-endian, data-type-policy=OVERRIDE, i-signal-type=PRIMITIVE, init-value=3, base-type=BT_EKK4_Match, compu {0=Cx0_reserved (CM_EKK4_Match_Cx0_reserved), 1=Cx1_match (CM_EKK4_Match_Cx1_match), 2=Cx2_mismatch (CM_EKK4_Match_Cx2_mismatch), 3=Cx3_Init (CM_EKK4_Match_Cx3_Init)}, range raw 0..3, transfer-property=PENDING, to Klima(timeout 3.5 s)  # Über das Signal Match wird die Kompatibilität der vom Master-SG gesendeten Error_Mask_Nr quittiert.
            signal EKK4_TF_Change_XIX_EKK4s_01_XIX_Klima_LIN3: start 46, 1 bit, little-endian, data-type-policy=OVERRIDE, i-signal-type=PRIMITIVE, init-value=0, base-type=BT_EKK4_TF_Change, compu {phys=raw for raw 0..1}, range phys 0..1, raw 0..1, transfer-property=PENDING, to Klima(timeout 3.5 s)  # Über das Statusbit TF_Change wird die Änderung einer bestehenden globalen Fehlerindikation eines Fehlerortes zur Anzeige gebracht. Das Master-SG vergleicht dabei den aktellen Signalwert mit dem zuletzt empfangenen Wert und reagiert jeweils bei Änderung.
            signal EKK4_ResponseError_XIX_EKK4s_01_XIX_Klima_LIN3: start 47, 1 bit, little-endian, data-type-policy=OVERRIDE, i-signal-type=PRIMITIVE, init-value=0, base-type=BT_EKK4_ResponseError, invalid-value=Invalid_EKK4_ResponseError_XIX_EKK4s_01_XIX_Klima_LIN3:1, compu {0=Cx0_normal (CM_EKK4_ResponseError_Cx0_normal), 1=Cx1_Fehler (CM_EKK4_ResponseError_Cx1_Fehler)}, range raw 0..1, transfer-property=PENDING, to Klima(timeout 3.5 s)  # siehe LIN2.0-Specification (Darf nicht über ein Fehlergueltigkeitsbit abgesichtert werden!)
            signal EKK4_COMP_SPEED_XIX_EKK4s_01_XIX_Klima_LIN3: start 48, 10 bit, little-endian, data-type-policy=OVERRIDE, i-signal-type=PRIMITIVE, init-value=0, base-type=BT_EKK4_COMP_SPEED, invalid-value=Invalid_EKK4_COMP_SPEED_XIX_EKK4s_01_XIX_Klima_LIN3:1023, compu {phys=raw*15 for raw 0..1022, 1023=Cx3ff_Fehler (CM_EKK4_COMP_SPEED_Cx3ff_Fehler); unit Unit_MinutInver}, range phys 0..15330 Unit_MinutInver, raw 0..1023, unit=Unit_MinutInver, transfer-property=PENDING, to Klima(timeout 3.5 s)  # Drehzahlrange : 0 - 15330 Auflösung: 15rpm Init = 0 error = 1023
            signal EKK4_ErrMem_State_XIX_EKK4s_01_XIX_Klima_LIN3: start 58, 2 bit, little-endian, data-type-policy=OVERRIDE, i-signal-type=PRIMITIVE, init-value=2, base-type=BT_EKK4_ErrMem_State, compu {0=Cx0_NA_reserved (CM_EKK4_ErrMem_State_Cx0_NA_reserved), 1=Cx1_ErrMem_Active (CM_EKK4_ErrMem_State_Cx1_ErrMem_Active), 2=Cx2_ErrMem_Init_Progress (CM_EKK4_ErrMem_State_Cx2_ErrMem_Init_Progress), 3=Cx3_ErrMem_Init_Done (CM_EKK4_ErrMem_State_Cx3_ErrMem_Init_Done)}, range raw 0..3, transfer-property=PENDING, to Klima(timeout 3.5 s)  # Die SecondaryOBDECU/SecondaryOBDComponent muss eine Statusinformation Err-Mem_State für die Gültigkeit, der auf der Bus-Schnittstelle übertragenen Diagnoseinformati-onen, zur Verfügung stellen.
            signal EKK4_ParameterChange_XIX_EKK4s_01_XIX_Klima_LIN3: start 60, 1 bit, little-endian, data-type-policy=OVERRIDE, i-signal-type=PRIMITIVE, init-value=0, base-type=BT_EKK4_ParameterChange, compu {0=Cx0_no_parameter_change (CM_EKK4_ParameterChange_Cx0_no_parameter_change), 1=Cx1_parameter_change (CM_EKK4_ParameterChange_Cx1_parameter_change)}, range raw 0..1, transfer-property=PENDING, to Klima(timeout 3.5 s)  # Parameter-Änderungen (ParameterChange), die zur Änderung der CALID/CVN führen, sind bei Änderung über ein Applikationsbit anzuzeigen.
            signal EKK4_COMP_ST_XIX_EKK4s_01_XIX_Klima_LIN3: start 61, 3 bit, little-endian, data-type-policy=OVERRIDE, i-signal-type=PRIMITIVE, init-value=7, base-type=BT_EKK4_COMP_ST, compu {0=Cx0_Comp_Stop (CM_EKK4_COMP_ST_Cx0_Comp_Stop), 1=Cx1_Comp_ON (CM_EKK4_COMP_ST_Cx1_Comp_ON), 2=Cx2_Comp_Speed_Limited_Operation (CM_EKK4_COMP_ST_Cx2_Comp_Speed_Limited_Operation), 3=Cx3_Comp_Stop_For_Protection_TF (CM_EKK4_COMP_ST_Cx3_Comp_Stop_For_Protection_TF), 4=Cx4_Comp_Stop_For_Self_Protection (CM_EKK4_COMP_ST_Cx4_Comp_Stop_For_Self_Protection), 5=Cx5_Comp_Stop_For_INV_Heating (CM_EKK4_COMP_ST_Cx5_Comp_Stop_For_INV_Heating), 6=Cx6_NC (CM_EKK4_COMP_ST_Cx6_NC), 7=Cx7_Init (CM_EKK4_COMP_ST_Cx7_Init)}, range raw 0..7, transfer-property=PENDING, to Klima(timeout 3.5 s)  # Compressor operation status
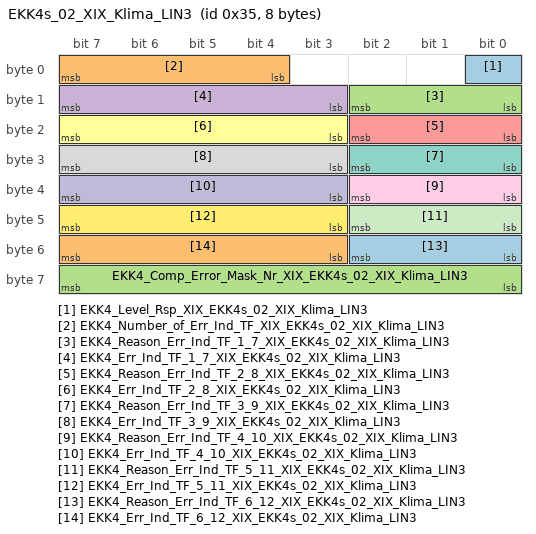
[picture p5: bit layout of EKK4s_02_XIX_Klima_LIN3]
        frame EKK4s_02_XIX_Klima_LIN3: id 0x35, to Klima, frame-length=8, lin-checksum=ENHANCED
          pdu EKK4s_02_XIX_Klima_LIN3: length=8, unused-bit-pattern=0
            signal EKK4_Level_Rsp_XIX_EKK4s_02_XIX_Klima_LIN3: start 0, 1 bit, little-endian, data-type-policy=OVERRIDE, i-signal-type=PRIMITIVE, base-type=BT_EKK4_Level_Rsp, compu {0=Cx0_Ausgabe_Ebene_0 (CM_EKK4_Level_Rsp_Cx0_Ausgabe_Ebene_0), 1=Cx1_Ausgabe_Ebene_1 (CM_EKK4_Level_Rsp_Cx1_Ausgabe_Ebene_1)}, range raw 0..1, transfer-property=PENDING, to Klima(timeout 3.5 s)  # Mit diesem Signal wird dem Master-SG dargestellt, welche Ausgabe-Ebene aktuell angezeigt wird.
            signal EKK4_Number_of_Err_Ind_TF_XIX_EKK4s_02_XIX_Klima_LIN3: start 4, 4 bit, little-endian, data-type-policy=OVERRIDE, i-signal-type=PRIMITIVE, base-type=BT_EKK4_Number_of_Err_Ind_TF, compu {0=Cx0_keine_Fehlerindikation (CM_EKK4_Number_of_Err_Ind_TF_Cx0_keine_Fehlerindikation), phys=raw for raw 1..12, 13=Cxd_reserved (CM_EKK4_Number_of_Err_Ind_TF_Cxd_reserved), 14=Cxe_reserved (CM_EKK4_Number_of_Err_Ind_TF_Cxe_reserved), 15=Cxf_reserved (CM_EKK4_Number_of_Err_Ind_TF_Cxf_reserved)}, range phys 1..12, raw 0..15, transfer-property=PENDING, to Klima(timeout 3.5 s)  # Über das Signal Number_of_Err_Ind_TF wird dem Master-SG die Anzahl der globalen Fehlerindikationen, für welche aktuell das Ergebnis (TF_TC) im Kompressor vorliegt angezeigt. 0 = keine Fehlerindikation 1-12 = Anzahl gleichzeitig vorliegender Fehlerindikationen 13-15 = reserved [darf nicht gesendet werden]
            signal EKK4_Reason_Err_Ind_TF_1_7_XIX_EKK4s_02_XIX_Klima_LIN3: start 8, 3 bit, little-endian, data-type-policy=OVERRIDE, i-signal-type=PRIMITIVE, base-type=BT_EKK4_Reason_Err_Ind_TF_1_7, compu {0=Cx0_kein_Fehlersymptom (CM_EKK4_Reason_Err_Ind_TF_1_7_Cx0_kein_Fehlersymptom), phys=raw for raw 1..7}, range phys 1..7, raw 0..7, transfer-property=PENDING, to Klima(timeout 3.5 s)  # In diesen Signalen werden für übermittelte Kennnummern mit anliegender Fehlerindikation die spezifischen Fehlersymptome ausgegeben. 0 = Platzhalter (keine Fehlersymptom) 1-7 = Fehlersymptom
            signal EKK4_Err_Ind_TF_1_7_XIX_EKK4s_02_XIX_Klima_LIN3: start 11, 5 bit, little-endian, data-type-policy=OVERRIDE, i-signal-type=PRIMITIVE, base-type=BT_EKK4_Err_Ind_TF_1_7, compu {0=Cx0_keine_Fehlerindikation (CM_EKK4_Err_Ind_TF_1_7_Cx0_keine_Fehlerindikation), phys=raw for raw 1..28, 29=Cx1d_reserved (CM_EKK4_Err_Ind_TF_1_7_Cx1d_reserved), 30=Cx1e_reserved (CM_EKK4_Err_Ind_TF_1_7_Cx1e_reserved), 31=Cx1f_reserved (CM_EKK4_Err_Ind_TF_1_7_Cx1f_reserved)}, range phys 1..28, raw 0..31, transfer-property=PENDING, to Klima(timeout 3.5 s)  # In den Signalen Err_Ind_TF_n_n+6 werden Kennnummern projiziert, für welche aktuell eine globale Fehlerindikation des Kompressors vorliegt. 0 = keine Fehlerindikation 1-28 =Kennnummer 29-31 = reserved
            signal EKK4_Reason_Err_Ind_TF_2_8_XIX_EKK4s_02_XIX_Klima_LIN3: start 16, 3 bit, little-endian, data-type-policy=OVERRIDE, i-signal-type=PRIMITIVE, base-type=BT_EKK4_Reason_Err_Ind_TF_2_8, compu {0=Cx0_kein_Fehlersymptom (CM_EKK4_Reason_Err_Ind_TF_2_8_Cx0_kein_Fehlersymptom), phys=raw for raw 1..7}, range phys 1..7, raw 0..7, transfer-property=PENDING, to Klima(timeout 3.5 s)  # In diesen Signalen werden für übermittelte Kennnummern mit anliegender Fehlerindikation die spezifischen Fehlersymptome ausgegeben. 0 = Platzhalter (keine Fehlersymptom) 1-7 = Fehlersymptom
            signal EKK4_Err_Ind_TF_2_8_XIX_EKK4s_02_XIX_Klima_LIN3: start 19, 5 bit, little-endian, data-type-policy=OVERRIDE, i-signal-type=PRIMITIVE, base-type=BT_EKK4_Err_Ind_TF_2_8, compu {0=Cx0_keine_Fehlerindikation (CM_EKK4_Err_Ind_TF_2_8_Cx0_keine_Fehlerindikation), phys=raw for raw 1..28, 29=Cx1d_reserved (CM_EKK4_Err_Ind_TF_2_8_Cx1d_reserved), 30=Cx1e_reserved (CM_EKK4_Err_Ind_TF_2_8_Cx1e_reserved), 31=Cx1f_reserved (CM_EKK4_Err_Ind_TF_2_8_Cx1f_reserved)}, range phys 1..28, raw 0..31, transfer-property=PENDING, to Klima(timeout 3.5 s)  # In den Signalen Err_Ind_TF_n_n+6 werden Kennnummern projiziert, für welche aktuell eine globale Fehlerindikation des Kompressors vorliegt. 0 = keine Fehlerindikation 1-28 =Kennnummer 29-31 = reserved
            signal EKK4_Reason_Err_Ind_TF_3_9_XIX_EKK4s_02_XIX_Klima_LIN3: start 24, 3 bit, little-endian, data-type-policy=OVERRIDE, i-signal-type=PRIMITIVE, base-type=BT_EKK4_Reason_Err_Ind_TF_3_9, compu {0=Cx0_kein_Fehlersymptom (CM_EKK4_Reason_Err_Ind_TF_3_9_Cx0_kein_Fehlersymptom), phys=raw for raw 1..7}, range phys 1..7, raw 0..7, transfer-property=PENDING, to Klima(timeout 3.5 s)  # In diesen Signalen werden für übermittelte Kennnummern mit anliegender Fehlerindikation die spezifischen Fehlersymptome ausgegeben. 0 = Platzhalter (keine Fehlersymptom) 1-7 = Fehlersymptom
            signal EKK4_Err_Ind_TF_3_9_XIX_EKK4s_02_XIX_Klima_LIN3: start 27, 5 bit, little-endian, data-type-policy=OVERRIDE, i-signal-type=PRIMITIVE, base-type=BT_EKK4_Err_Ind_TF_3_9, compu {0=Cx0_keine_Fehlerindikation (CM_EKK4_Err_Ind_TF_3_9_Cx0_keine_Fehlerindikation), phys=raw for raw 1..28, 29=Cx1d_reserved (CM_EKK4_Err_Ind_TF_3_9_Cx1d_reserved), 30=Cx1e_reserved (CM_EKK4_Err_Ind_TF_3_9_Cx1e_reserved), 31=Cx1f_reserved (CM_EKK4_Err_Ind_TF_3_9_Cx1f_reserved)}, range phys 1..28, raw 0..31, transfer-property=PENDING, to Klima(timeout 3.5 s)  # In den Signalen Err_Ind_TF_n_n+6 werden Kennnummern projiziert, für welche aktuell eine globale Fehlerindikation des Kompressors vorliegt. 0 = keine Fehlerindikation 1-28 =Kennnummer 29-31 = reserved
            signal EKK4_Reason_Err_Ind_TF_4_10_XIX_EKK4s_02_XIX_Klima_LIN3: start 32, 3 bit, little-endian, data-type-policy=OVERRIDE, i-signal-type=PRIMITIVE, base-type=BT_EKK4_Reason_Err_Ind_TF_4_10, compu {0=Cx0_kein_Fehlersymptom (CM_EKK4_Reason_Err_Ind_TF_4_10_Cx0_kein_Fehlersymptom), phys=raw for raw 1..7}, range phys 1..7, raw 0..7, transfer-property=PENDING, to Klima(timeout 3.5 s)  # In diesen Signalen werden für übermittelte Kennnummern mit anliegender Fehlerindikation die spezifischen Fehlersymptome ausgegeben. 0 = Platzhalter (keine Fehlersymptom) 1-7 = Fehlersymptom
            signal EKK4_Err_Ind_TF_4_10_XIX_EKK4s_02_XIX_Klima_LIN3: start 35, 5 bit, little-endian, data-type-policy=OVERRIDE, i-signal-type=PRIMITIVE, base-type=BT_EKK4_Err_Ind_TF_4_10, compu {0=Cx0_keine_Fehlerindikation (CM_EKK4_Err_Ind_TF_4_10_Cx0_keine_Fehlerindikation), phys=raw for raw 1..28, 29=Cx1d_reserved (CM_EKK4_Err_Ind_TF_4_10_Cx1d_reserved), 30=Cx1e_reserved (CM_EKK4_Err_Ind_TF_4_10_Cx1e_reserved), 31=Cx1f_reserved (CM_EKK4_Err_Ind_TF_4_10_Cx1f_reserved)}, range phys 1..28, raw 0..31, transfer-property=PENDING, to Klima(timeout 3.5 s)  # In den Signalen Err_Ind_TF_n_n+6 werden Kennnummern projiziert, für welche aktuell eine globale Fehlerindikation des Kompressors vorliegt. 0 = keine Fehlerindikation 1-28 =Kennnummer 29-31 = reserved
            signal EKK4_Reason_Err_Ind_TF_5_11_XIX_EKK4s_02_XIX_Klima_LIN3: start 40, 3 bit, little-endian, data-type-policy=OVERRIDE, i-signal-type=PRIMITIVE, base-type=BT_EKK4_Reason_Err_Ind_TF_5_11, compu {0=Cx0_kein_Fehlersymptom (CM_EKK4_Reason_Err_Ind_TF_5_11_Cx0_kein_Fehlersymptom), phys=raw for raw 1..7}, range phys 1..7, raw 0..7, transfer-property=PENDING, to Klima(timeout 3.5 s)  # In diesen Signalen werden für übermittelte Kennnummern mit anliegender Fehlerindikation die spezifischen Fehlersymptome ausgegeben. 0 = Platzhalter (keine Fehlersymptom) 1-7 = Fehlersymptom
            signal EKK4_Err_Ind_TF_5_11_XIX_EKK4s_02_XIX_Klima_LIN3: start 43, 5 bit, little-endian, data-type-policy=OVERRIDE, i-signal-type=PRIMITIVE, base-type=BT_EKK4_Err_Ind_TF_5_11, compu {0=Cx0_keine_Fehlerindikation (CM_EKK4_Err_Ind_TF_5_11_Cx0_keine_Fehlerindikation), phys=raw for raw 1..28, 29=Cx1d_reserved (CM_EKK4_Err_Ind_TF_5_11_Cx1d_reserved), 30=Cx1e_reserved (CM_EKK4_Err_Ind_TF_5_11_Cx1e_reserved), 31=Cx1f_reserved (CM_EKK4_Err_Ind_TF_5_11_Cx1f_reserved)}, range phys 1..28, raw 0..31, transfer-property=PENDING, to Klima(timeout 3.5 s)  # In den Signalen Err_Ind_TF_n_n+6 werden Kennnummern projiziert, für welche aktuell eine globale Fehlerindikation des Kompressors vorliegt. 0 = keine Fehlerindikation 1-28 =Kennnummer 29-31 = reserved
            signal EKK4_Reason_Err_Ind_TF_6_12_XIX_EKK4s_02_XIX_Klima_LIN3: start 48, 3 bit, little-endian, data-type-policy=OVERRIDE, i-signal-type=PRIMITIVE, base-type=BT_EKK4_Reason_Err_Ind_TF_6_12, compu {0=Cx0_kein_Fehlersymptom (CM_EKK4_Reason_Err_Ind_TF_6_12_Cx0_kein_Fehlersymptom), phys=raw for raw 1..7}, range phys 1..7, raw 0..7, transfer-property=PENDING, to Klima(timeout 3.5 s)  # In diesen Signalen werden für übermittelte Kennnummern mit anliegender Fehlerindikation die spezifischen Fehlersymptome ausgegeben. 0 = Platzhalter (keine Fehlersymptom) 1-7 = Fehlersymptom
            signal EKK4_Err_Ind_TF_6_12_XIX_EKK4s_02_XIX_Klima_LIN3: start 51, 5 bit, little-endian, data-type-policy=OVERRIDE, i-signal-type=PRIMITIVE, base-type=BT_EKK4_Err_Ind_TF_6_12, compu {0=Cx0_keine_Fehlerindikation (CM_EKK4_Err_Ind_TF_6_12_Cx0_keine_Fehlerindikation), phys=raw for raw 1..28, 29=Cx1d_reserved (CM_EKK4_Err_Ind_TF_6_12_Cx1d_reserved), 30=Cx1e_reserved (CM_EKK4_Err_Ind_TF_6_12_Cx1e_reserved), 31=Cx1f_reserved (CM_EKK4_Err_Ind_TF_6_12_Cx1f_reserved)}, range phys 1..28, raw 0..31, transfer-property=PENDING, to Klima(timeout 3.5 s)  # In den Signalen Err_Ind_TF_n_n+6 werden Kennnummern projiziert, für welche aktuell eine globale Fehlerindikation des Kompressors vorliegt. 0 = keine Fehlerindikation 1-28 =Kennnummer 29-31 = reserved
            signal EKK4_Comp_Error_Mask_Nr_XIX_EKK4s_02_XIX_Klima_LIN3: start 56, 8 bit, little-endian, data-type-policy=OVERRIDE, i-signal-type=PRIMITIVE, base-type=BT_EKK4_Comp_Error_Mask_Nr, compu {0=Cx0_reserved (CM_EKK4_Comp_Error_Mask_Nr_Cx0_reserved), phys=raw for raw 1..254, 255=Cxff_reserved (CM_EKK4_Comp_Error_Mask_Nr_Cxff_reserved)}, range phys 1..254, raw 0..255, transfer-property=PENDING, to Klima(timeout 3.5 s)  # Im Signal Comp_Error_Mask_Nr wird vom EKK seine implementierte Error_Mask_Nr ausgegeben. 0 = reserved 1-254 = Error_Mask_Nr des EKK 255 = reserved
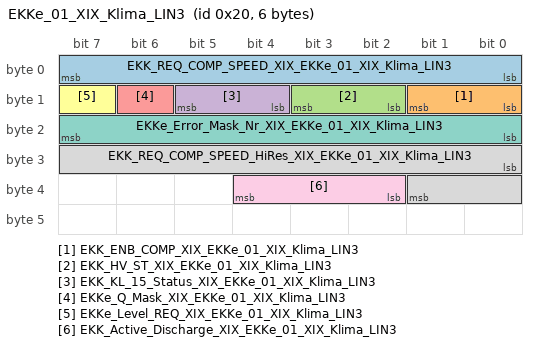
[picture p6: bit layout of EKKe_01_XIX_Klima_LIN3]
        frame EKKe_01_XIX_Klima_LIN3: id 0x20, from Klima, frame-length=6, lin-checksum=ENHANCED
          pdu EKKe_01_XIX_Klima_LIN3: length=6, unused-bit-pattern=0
            signal EKK_REQ_COMP_SPEED_XIX_EKKe_01_XIX_Klima_LIN3: start 0, 8 bit, little-endian, data-type-policy=OVERRIDE, i-signal-type=PRIMITIVE, init-value=0, base-type=BT_EKK_REQ_COMP_SPEED, invalid-value=Invalid_EKK_REQ_COMP_SPEED_XIX_EKKe_01_XIX_Klima_LIN3:255, compu {phys=raw*50 for raw 0..254, 255=Cxff_Fehler (CM_EKK_REQ_COMP_SPEED_Cxff_Fehler); unit Unit_MinutInver}, range phys 0..12700 Unit_MinutInver, raw 0..255, unit=Unit_MinutInver, transfer-property=PENDING  # Requested compressor speed: 0....9000 rpm
            signal EKK_ENB_COMP_XIX_EKKe_01_XIX_Klima_LIN3: start 8, 2 bit, little-endian, data-type-policy=OVERRIDE, i-signal-type=PRIMITIVE, init-value=0, base-type=BT_EKK_ENB_COMP, compu {0=Cx0_Comp_OFF (CM_EKK_ENB_COMP_Cx0_Comp_OFF), 1=Cx1_Comp_ON (CM_EKK_ENB_COMP_Cx1_Comp_ON), 2=Cx2_Reserved (CM_EKK_ENB_COMP_Cx2_Reserved), 3=Cx3_Signal_invalid (CM_EKK_ENB_COMP_Cx3_Signal_invalid)}, range raw 0..3, transfer-property=PENDING  # Enable to start for compressor
            signal EKK_HV_ST_XIX_EKKe_01_XIX_Klima_LIN3: start 10, 2 bit, little-endian, data-type-policy=OVERRIDE, i-signal-type=PRIMITIVE, init-value=0, base-type=BT_EKK_HV_ST, compu {0=Cx0_HV_OFF_not_supplied (CM_EKK_HV_ST_Cx0_HV_OFF_not_supplied), 1=Cx1_HV_ON_supplied (CM_EKK_HV_ST_Cx1_HV_ON_supplied), 2=Cx2_Reserved (CM_EKK_HV_ST_Cx2_Reserved), 3=Cx3_Signal_invalid (CM_EKK_HV_ST_Cx3_Signal_invalid)}, range raw 0..3, transfer-property=PENDING  # Compressor High-Voltage Status
            signal EKK_KL_15_Status_XIX_EKKe_01_XIX_Klima_LIN3: start 12, 2 bit, little-endian, data-type-policy=OVERRIDE, i-signal-type=PRIMITIVE, init-value=0, base-type=BT_EKK_KL_15_Status, compu {0=Cx0_KL_15_Aus (CM_EKK_KL_15_Status_Cx0_KL_15_Aus), 1=Cx1_KL_15_Ein (CM_EKK_KL_15_Status_Cx1_KL_15_Ein), 2=Cx2_N_A (CM_EKK_KL_15_Status_Cx2_N_A), 3=Cx3_Invalid (CM_EKK_KL_15_Status_Cx3_Invalid)}, range raw 0..3, transfer-property=PENDING  # Über dieses Signal wird dem EKK der Status der KL 15 mitgeteilt. Dieses ist für die OBD Diagnosen nötig.
            signal EKKe_Q_Mask_XIX_EKKe_01_XIX_Klima_LIN3: start 14, 1 bit, little-endian, data-type-policy=OVERRIDE, i-signal-type=PRIMITIVE, base-type=BT_EKKe_Q_Mask, compu {0=Cx0_nicht_qualifiziert (CM_EKKe_Q_Mask_Cx0_nicht_qualifiziert), 1=Cx1_qualifiziert (CM_EKKe_Q_Mask_Cx1_qualifiziert)}, range raw 0..1, transfer-property=PENDING  # Über das Qualifizierungsbit Q_Mask wird die Freigabeinformation für das Signal Error_Mask_Nr erteilt.
            signal EKKe_Level_REQ_XIX_EKKe_01_XIX_Klima_LIN3: start 15, 1 bit, little-endian, data-type-policy=OVERRIDE, i-signal-type=PRIMITIVE, init-value=0, base-type=BT_EKKe_Level_REQ, compu {0=Cx0_Ausgabe_Ebene_0 (CM_EKKe_Level_REQ_Cx0_Ausgabe_Ebene_0), 1=Cx1_Ausgabe_Ebene_1 (CM_EKKe_Level_REQ_Cx1_Ausgabe_Ebene_1)}, range raw 0..1, transfer-property=PENDING  # Das Signal EKKe_LEVEL_REQ signalisiert dem EKK, welche Ebene (Level) bei Aufruf des Subscribed Frame EKK4s_02 ausgegeben werden soll.
            signal EKKe_Error_Mask_Nr_XIX_EKKe_01_XIX_Klima_LIN3: start 16, 8 bit, little-endian, data-type-policy=OVERRIDE, i-signal-type=PRIMITIVE, base-type=BT_EKKe_Error_Mask_Nr, invalid-value=Invalid_EKKe_Error_Mask_Nr_XIX_EKKe_01_XIX_Klima_LIN3:255, compu {phys=raw for raw 0..254, 255=Cxff_Fehler (CM_EKKe_Error_Mask_Nr_Cxff_Fehler)}, range phys 0..254, raw 0..255, transfer-property=PENDING  # Über das Signal Error_Mask_Nr wird die aktuell im Master-SG aktivierte Error_Mask an den EKK übermittelt. Wertebereich: 0 = busy (nur während Anlernroutine) , 1-254 = Masken-Nr (dez.), 255 = Error
            signal EKK_REQ_COMP_SPEED_HiRes_XIX_EKKe_01_XIX_Klima_LIN3: start 24, 10 bit, little-endian, data-type-policy=OVERRIDE, i-signal-type=PRIMITIVE, init-value=0, base-type=BT_EKK_REQ_COMP_SPEED_HiRes, invalid-value=Invalid_EKK_REQ_COMP_SPEED_HiRes_XIX_EKKe_01_XIX_Klima_LIN3:1023, compu {phys=raw*15 for raw 0..1022, 1023=Cx3ff_Fehler (CM_EKK_REQ_COMP_SPEED_HiRes_Cx3ff_Fehler); unit Unit_MinutInver}, range phys 0..15330 Unit_MinutInver, raw 0..1023, unit=Unit_MinutInver, transfer-property=PENDING  # Requested compressor speed: Drehzahlrange : 0 - 15330 Auflösung: 15rpm Init = 0 error = 1023
            signal EKK_Active_Discharge_XIX_EKKe_01_XIX_Klima_LIN3: start 34, 3 bit, little-endian, data-type-policy=OVERRIDE, i-signal-type=PRIMITIVE, init-value=0, base-type=BT_EKK_Active_Discharge, invalid-value=Invalid_EKK_Active_Discharge_XIX_EKKe_01_XIX_Klima_LIN3:7, compu {0=Cx0_keine_Deaktivierung (CM_EKK_Active_Discharge_Cx0_keine_Deaktivierung), 1=Cx1_Deaktivierung_1 (CM_EKK_Active_Discharge_Cx1_Deaktivierung_1), 2=Cx2_Deaktivierung_2 (CM_EKK_Active_Discharge_Cx2_Deaktivierung_2), 3=Cx3_Deaktivierung_3 (CM_EKK_Active_Discharge_Cx3_Deaktivierung_3), 4=Cx4_Deaktivierung_4 (CM_EKK_Active_Discharge_Cx4_Deaktivierung_4), 5=Cx5_Deaktivierung_5 (CM_EKK_Active_Discharge_Cx5_Deaktivierung_5), 6=Cx6_Deaktivierung_6 (CM_EKK_Active_Discharge_Cx6_Deaktivierung_6), 7=Cx7_Fehler (CM_EKK_Active_Discharge_Cx7_Fehler)}, range raw 0..7, transfer-property=PENDING  # Deaktivierung HV Klimakompressor
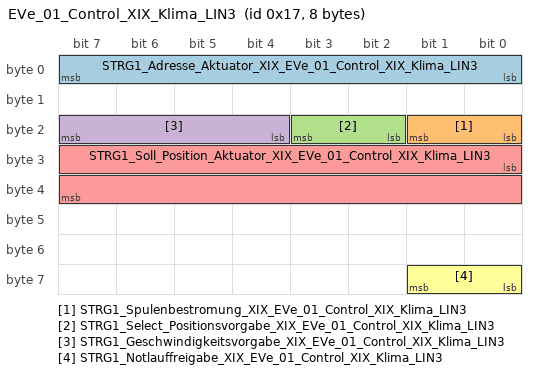
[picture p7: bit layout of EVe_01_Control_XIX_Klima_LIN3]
        frame EVe_01_Control_XIX_Klima_LIN3: id 0x17, from Klima, frame-length=8, lin-checksum=ENHANCED
          pdu EVe_01_Control_XIX_Klima_LIN3: length=8, unused-bit-pattern=0
            signal STRG1_Adresse_Aktuator_XIX_EVe_01_Control_XIX_Klima_LIN3: start 0, 8 bit, little-endian, data-type-policy=OVERRIDE, i-signal-type=PRIMITIVE, base-type=BT_STRG1_Adresse_Aktuator, invalid-value=Invalid_STRG1_Adresse_Aktuator_XIX_EVe_01_Control_XIX_Klima_LIN3:255, compu {phys=raw for raw 0..254, 127=Cx7f_Broadcast (CM_STRG1_Adresse_Aktuator_Cx7f_Broadcast), 255=Cxff_Fehler (CM_STRG1_Adresse_Aktuator_Cxff_Fehler); unit Unit_None}, range phys 0..254 Unit_None, raw 0..255, unit=Unit_None, transfer-property=PENDING  # Zielempfängerauswahl, Steuerungsbotschaft für Aktuatoren
            signal STRG1_Spulenbestromung_XIX_EVe_01_Control_XIX_Klima_LIN3: start 16, 2 bit, little-endian, data-type-policy=OVERRIDE, i-signal-type=PRIMITIVE, base-type=BT_STRG1_Spulenbestromung, invalid-value=Invalid_STRG1_Spulenbestromung_XIX_EVe_01_Control_XIX_Klima_LIN3:3, compu {0=Cx0_Motorspulen_unbestromt (CM_STRG1_Spulenbestromung_Cx0_Motorspulen_unbestromt), 1=Cx1_Motorspulen_bestromt (CM_STRG1_Spulenbestromung_Cx1_Motorspulen_bestromt), 2=Cx2_reserviert (CM_STRG1_Spulenbestromung_Cx2_reserviert), 3=Cx3_Fehler (CM_STRG1_Spulenbestromung_Cx3_Fehler)}, range raw 0..3, transfer-property=PENDING  # Spulenbestromungszustandsvorgabe, Steuerungsbotschaft für Aktuatoren
            signal STRG1_Select_Positionsvorgabe_XIX_EVe_01_Control_XIX_Klima_LIN3: start 18, 2 bit, little-endian, data-type-policy=OVERRIDE, i-signal-type=PRIMITIVE, init-value=2, base-type=BT_STRG1_Select_Positionsvorgabe, invalid-value=Invalid_STRG1_Select_Positionsvorgabe_XIX_EVe_01_Control_XIX_Klima_LIN3:3, compu {0=Cx0_Soll_Position_gueltig (CM_STRG1_Select_Positionsvorgabe_Cx0_Soll_Position_gueltig), 1=Cx1_Start_Position_gueltig (CM_STRG1_Select_Positionsvorgabe_Cx1_Start_Position_gueltig), 2=Cx2_keine_Positionsvorgabe_gueltig (CM_STRG1_Select_Positionsvorgabe_Cx2_keine_Positionsvorgabe_gueltig), 3=Cx3_Fehler (CM_STRG1_Select_Positionsvorgabe_Cx3_Fehler)}, range raw 0..3, transfer-property=PENDING  # Vorgabe der Gültigkeit der Positionsvorgaben, Steuerungsbotschaft für Aktuatoren
            signal STRG1_Geschwindigkeitsvorgabe_XIX_EVe_01_Control_XIX_Klima_LIN3: start 20, 4 bit, little-endian, data-type-policy=OVERRIDE, i-signal-type=PRIMITIVE, base-type=BT_STRG1_Geschwindigkeitsvorgabe, invalid-value=Invalid_STRG1_Geschwindigkeitsvorgabe_XIX_EVe_01_Control_XIX_Klima_LIN3:15, compu {0=Cx0_reserviert (CM_STRG1_Geschwindigkeitsvorgabe_Cx0_reserviert), 1=Cx1_Geschwindigkeitsstufe_1 (CM_STRG1_Geschwindigkeitsvorgabe_Cx1_Geschwindigkeitsstufe_1), 2=Cx2_Geschwindigkeitsstufe_2 (CM_STRG1_Geschwindigkeitsvorgabe_Cx2_Geschwindigkeitsstufe_2), 3=Cx3_Geschwindigkeitsstufe_3 (CM_STRG1_Geschwindigkeitsvorgabe_Cx3_Geschwindigkeitsstufe_3), 4=Cx4_Geschwindigkeitsstufe_4 (CM_STRG1_Geschwindigkeitsvorgabe_Cx4_Geschwindigkeitsstufe_4), 5=Cx5_Autospeed (CM_STRG1_Geschwindigkeitsvorgabe_Cx5_Autospeed), 15=Cxf_Fehler (CM_STRG1_Geschwindigkeitsvorgabe_Cxf_Fehler)}, range raw 0..15, transfer-property=PENDING  # Vorgabe der Geschwindigkeit, Steuerungsbotschaft für Aktuatoren
            signal STRG1_Soll_Position_Aktuator_XIX_EVe_01_Control_XIX_Klima_LIN3: start 24, 16 bit, little-endian, data-type-policy=OVERRIDE, i-signal-type=PRIMITIVE, base-type=BT_STRG1_Soll_Position_Aktuator, invalid-value=Invalid_STRG1_Soll_Position_Aktuator_XIX_EVe_01_Control_XIX_Klima_LIN3:65535, compu {phys=raw for raw 0..65534, 65535=Cxffff_Fehler (CM_STRG1_Soll_Position_Aktuator_Cxffff_Fehler); unit Unit_None}, range phys 0..65534 Unit_None, raw 0..65535, unit=Unit_None, transfer-property=PENDING  # Vorgabe der Sollposition, Steuerungsbotschaft für die Aktuatoren
            signal STRG1_Notlauffreigabe_XIX_EVe_01_Control_XIX_Klima_LIN3: start 56, 2 bit, little-endian, data-type-policy=OVERRIDE, i-signal-type=PRIMITIVE, base-type=BT_STRG1_Notlauffreigabe, invalid-value=Invalid_STRG1_Notlauffreigabe_XIX_EVe_01_Control_XIX_Klima_LIN3:3, compu {0=Cx0_Notlauf_aus (CM_STRG1_Notlauffreigabe_Cx0_Notlauf_aus), 1=Cx1_Notlauf_ein (CM_STRG1_Notlauffreigabe_Cx1_Notlauf_ein), 2=Cx2_reserviert (CM_STRG1_Notlauffreigabe_Cx2_reserviert), 3=Cx3_Fehler (CM_STRG1_Notlauffreigabe_Cx3_Fehler)}, range raw 0..3, transfer-property=PENDING  # Freigabe der Notlaufeigenschaft, Steuerungsbotschaft für Aktuatoren
        frame EXV1s_01_XIX_Klima_LIN3: id 0x18, to Klima, frame-length=8, lin-checksum=ENHANCED
          pdu EXV1s_01_XIX_Klima_LIN3: length=8, unused-bit-pattern=0
            signal EXV1_Ist_Position_Aktuator_XIX_EXV1s_01_XIX_Klima_LIN3: start 0, 16 bit, little-endian, data-type-policy=OVERRIDE, i-signal-type=PRIMITIVE, init-value=65534, base-type=BT_EXV1_Ist_Position_Aktuator, invalid-value=Invalid_EXV1_Ist_Position_Aktuator_XIX_EXV1s_01_XIX_Klima_LIN3:65535, compu {phys=raw for raw 0..65533, 65534=Cxfffe_Init (CM_EXV1_Ist_Position_Aktuator_Cxfffe_Init), 65535=Cxffff_Fehler (CM_EXV1_Ist_Position_Aktuator_Cxffff_Fehler); unit Unit_None}, range phys 0..65533 Unit_None, raw 0..65535, unit=Unit_None, transfer-property=PENDING, to Klima(timeout 3.5 s)  # Statusbotschaft für die elektrischen Kältemittelexpansionsventile
            signal EXV1_Geschwindigkeitsstatus_XIX_EXV1s_01_XIX_Klima_LIN3: start 16, 4 bit, little-endian, data-type-policy=OVERRIDE, i-signal-type=PRIMITIVE, base-type=BT_EXV1_Geschwindigkeitsstatus, invalid-value=Invalid_EXV1_Geschwindigkeitsstatus_XIX_EXV1s_01_XIX_Klima_LIN3:15, compu {0=Cx0_Motor_steht (CM_EXV1_Geschwindigkeitsstatus_Cx0_Motor_steht), 1=Cx1_Geschwindigkeitsstufe_1 (CM_EXV1_Geschwindigkeitsstatus_Cx1_Geschwindigkeitsstufe_1), 2=Cx2_Geschwindigkeitsstufe_2 (CM_EXV1_Geschwindigkeitsstatus_Cx2_Geschwindigkeitsstufe_2), 3=Cx3_Geschwindigkeitsstufe_3 (CM_EXV1_Geschwindigkeitsstatus_Cx3_Geschwindigkeitsstufe_3), 4=Cx4_Geschwindigkeitsstufe_4 (CM_EXV1_Geschwindigkeitsstatus_Cx4_Geschwindigkeitsstufe_4), 5=Cx5_Autospeed (CM_EXV1_Geschwindigkeitsstatus_Cx5_Autospeed), 15=Cxf_Fehler (CM_EXV1_Geschwindigkeitsstatus_Cxf_Fehler)}, range raw 0..15, transfer-property=PENDING, to Klima(timeout 3.5 s)  # Statusbotschaft für die elektrischen Kältemittelexpansionsventile
            signal EXV1_Temp_Warning_XIX_EXV1s_01_XIX_Klima_LIN3: start 20, 1 bit, little-endian, data-type-policy=OVERRIDE, i-signal-type=PRIMITIVE, base-type=BT_EXV1_Temp_Warning, compu {0=Cx0_keine_Warnschwelle (CM_EXV1_Temp_Warning_Cx0_keine_Warnschwelle), 1=Cx1_Warnschwelle_erreicht (CM_EXV1_Temp_Warning_Cx1_Warnschwelle_erreicht)}, range raw 0..1, transfer-property=PENDING, to Klima(timeout 3.5 s)  # Statusbotschaft für die elektrischen Kältemittelexpansionsventile
            signal EXV1_Temp_XIX_EXV1s_01_XIX_Klima_LIN3: start 24, 8 bit, little-endian, data-type-policy=OVERRIDE, i-signal-type=PRIMITIVE, init-value=254, base-type=BT_EXV1_Temp, invalid-value=Invalid_EXV1_Temp_XIX_EXV1s_01_XIX_Klima_LIN3:255, compu {phys=raw-50 for raw 0..253, 254=Cxfe_Init (CM_EXV1_Temp_Cxfe_Init), 255=Cxff_Fehler (CM_EXV1_Temp_Cxff_Fehler); unit Unit_DegreCelsi}, range phys -50..203 Unit_DegreCelsi, raw 0..255, unit=Unit_DegreCelsi, transfer-property=PENDING, to Klima(timeout 3.5 s)  # Platinentemperatur, Statusbotschaft für die elektrischen Kältemittelexpansionsventile
            signal EXV1_Spulenbestromung_XIX_EXV1s_01_XIX_Klima_LIN3: start 32, 2 bit, little-endian, data-type-policy=OVERRIDE, i-signal-type=PRIMITIVE, base-type=BT_EXV1_Spulenbestromung, invalid-value=Invalid_EXV1_Spulenbestromung_XIX_EXV1s_01_XIX_Klima_LIN3:3, compu {0=Cx0_Motorspulen_unbestromt (CM_EXV1_Spulenbestromung_Cx0_Motorspulen_unbestromt), 1=Cx1_Motorspulen_bestromt (CM_EXV1_Spulenbestromung_Cx1_Motorspulen_bestromt), 2=Cx2_reserviert (CM_EXV1_Spulenbestromung_Cx2_reserviert), 3=Cx3_Fehler (CM_EXV1_Spulenbestromung_Cx3_Fehler)}, range raw 0..3, transfer-property=PENDING, to Klima(timeout 3.5 s)  # Statusbotschaft für die elektrischen Kältemittelexpansionsventile
            signal EXV1_ErrMem_State_XIX_EXV1s_01_XIX_Klima_LIN3: start 38, 2 bit, little-endian, data-type-policy=OVERRIDE, i-signal-type=PRIMITIVE, init-value=2, base-type=BT_EXV1_ErrMem_State, compu {0=Cx0_Init_Default (CM_EXV1_ErrMem_State_Cx0_Init_Default), 1=Cx1_ErrMem_Active_State (CM_EXV1_ErrMem_State_Cx1_ErrMem_Active_State), 2=Cx2_ErrMem_InitProgress (CM_EXV1_ErrMem_State_Cx2_ErrMem_InitProgress), 3=Cx3_ErrMem_Init_done (CM_EXV1_ErrMem_State_Cx3_ErrMem_Init_done)}, range raw 0..3, transfer-property=PENDING, to Klima(timeout 3.5 s)  # OBD Signal, Statusbotschaft für die elektrischen Kältemittelexpansionsventile
            signal EXV1_ResponseError_XIX_EXV1s_01_XIX_Klima_LIN3: start 40, 1 bit, little-endian, data-type-policy=OVERRIDE, i-signal-type=PRIMITIVE, init-value=0, base-type=BT_EXV1_ResponseError, invalid-value=Invalid_EXV1_ResponseError_XIX_EXV1s_01_XIX_Klima_LIN3:1, compu {0=Cx0_normal (CM_EXV1_ResponseError_Cx0_normal), 1=Cx1_Fehler (CM_EXV1_ResponseError_Cx1_Fehler)}, range raw 0..1, transfer-property=PENDING, to Klima(timeout 3.5 s)  # siehe LIN2.0-Specification (Darf nicht über ein Fehlergueltigkeitsbit abgesichtert werden!)
            signal EXV1_ResponseError_TNCTOC_XIX_EXV1s_01_XIX_Klima_LIN3: start 41, 1 bit, little-endian, data-type-policy=OVERRIDE, i-signal-type=PRIMITIVE, init-value=1, base-type=BT_EXV1_ResponseError_TNCTOC, compu {0=Cx0_DTC_test_completed_this_operation_cylce (CM_EXV1_ResponseError_TNCTOC_Cx0_DTC_test_completed_this_operation_cylce), 1=Cx1_DTC_test_not_completed_this_operation_cylce (CM_EXV1_ResponseError_TNCTOC_Cx1_DTC_test_not_completed_this_operation_cylce)}, range raw 0..1, transfer-property=PENDING, to Klima(timeout 3.5 s)  # OBD TestFailed Flag, Statusbotschaft für die elektrischen Kältemittelexpansionsventile
            signal EXV1_Err_EDefekt_MoKomp_TF_XIX_EXV1s_01_XIX_Klima_LIN3: start 42, 1 bit, little-endian, data-type-policy=OVERRIDE, i-signal-type=PRIMITIVE, base-type=BT_EXV1_Err_EDefekt_MoKomp_TF, compu {0=Cx0_passive (CM_EXV1_Err_EDefekt_MoKomp_TF_Cx0_passive), 1=Cx1_active (CM_EXV1_Err_EDefekt_MoKomp_TF_Cx1_active)}, range raw 0..1, transfer-property=PENDING, to Klima(timeout 3.5 s)  # OBD TestFailed Flag, Statusbotschaft für die elektrischen Kältemittelexpansionsventile
            signal EXV1_Err_EDefekt_MoKomp_TNCTOC_XIX_EXV1s_01_XIX_Klima_LIN3: start 43, 1 bit, little-endian, data-type-policy=OVERRIDE, i-signal-type=PRIMITIVE, init-value=1, base-type=BT_EXV1_Err_EDefekt_MoKomp_TNCTOC, compu {0=Cx0_DTC_test_completed_this_operation_cylce (CM_EXV1_Err_EDefekt_MoKomp_TNCTOC_Cx0_DTC_test_completed_this_operation_cylce), 1=Cx1_DTC_test_not_completed_this_operation_cylce (CM_EXV1_Err_EDefekt_MoKomp_TNCTOC_Cx1_DTC_test_not_completed_this_operation_cylce)}, range raw 0..1, transfer-property=PENDING, to Klima(timeout 3.5 s)  # OBD TestFailed Flag, Statusbotschaft für die elektrischen Kältemittelexpansionsventile
            signal EXV1_Err_EDefekt_TSens_TF_XIX_EXV1s_01_XIX_Klima_LIN3: start 44, 1 bit, little-endian, data-type-policy=OVERRIDE, i-signal-type=PRIMITIVE, base-type=BT_EXV1_Err_EDefekt_TSens_TF, compu {0=Cx0_passive (CM_EXV1_Err_EDefekt_TSens_TF_Cx0_passive), 1=Cx1_active (CM_EXV1_Err_EDefekt_TSens_TF_Cx1_active)}, range raw 0..1, transfer-property=PENDING, to Klima(timeout 3.5 s)  # OBD TestFailed Flag, Statusbotschaft für die elektrischen Kältemittelexpansionsventile Fehlermeldung für Temperatursensor
            signal EXV1_Err_EDefekt_TSens_TNCTOC_XIX_EXV1s_01_XIX_Klima_LIN3: start 45, 1 bit, little-endian, data-type-policy=OVERRIDE, i-signal-type=PRIMITIVE, init-value=1, base-type=BT_EXV1_Err_EDefekt_TSens_TNCTOC, compu {0=Cx0_DTC_test_completed_this_operation_cylce (CM_EXV1_Err_EDefekt_TSens_TNCTOC_Cx0_DTC_test_completed_this_operation_cylce), 1=Cx1_DTC_test_not_completed_this_operation_cylce (CM_EXV1_Err_EDefekt_TSens_TNCTOC_Cx1_DTC_test_not_completed_this_operation_cylce)}, range raw 0..1, transfer-property=PENDING, to Klima(timeout 3.5 s)  # OBD TestFailed Flag, Statusbotschaft für die elektrischen Kältemittelexpansionsventile
            signal EXV1_Err_Uebertemperatur_TF_XIX_EXV1s_01_XIX_Klima_LIN3: start 46, 1 bit, little-endian, data-type-policy=OVERRIDE, i-signal-type=PRIMITIVE, base-type=BT_EXV1_Err_Uebertemperatur_TF, compu {0=Cx0_passive (CM_EXV1_Err_Uebertemperatur_TF_Cx0_passive), 1=Cx1_active (CM_EXV1_Err_Uebertemperatur_TF_Cx1_active)}, range raw 0..1, transfer-property=PENDING, to Klima(timeout 3.5 s)  # OBD TestFailed Flag, Statusbotschaft für die elektrischen Kältemittelexpansionsventile
            signal EXV1_Err_Uebertemperatur_TNCTOC_XIX_EXV1s_01_XIX_Klima_LIN3: start 47, 1 bit, little-endian, data-type-policy=OVERRIDE, i-signal-type=PRIMITIVE, init-value=1, base-type=BT_EXV1_Err_Uebertemperatur_TNCTOC, compu {0=Cx0_DTC_test_completed_this_operation_cylce (CM_EXV1_Err_Uebertemperatur_TNCTOC_Cx0_DTC_test_completed_this_operation_cylce), 1=Cx1_DTC_test_not_completed_this_operation_cylce (CM_EXV1_Err_Uebertemperatur_TNCTOC_Cx1_DTC_test_not_completed_this_operation_cylce)}, range raw 0..1, transfer-property=PENDING, to Klima(timeout 3.5 s)  # OBD TestFailed Flag, Statusbotschaft für die elektrischen Kältemittelexpansionsventile
            signal EXV1_Err_Ueberspannung_TF_XIX_EXV1s_01_XIX_Klima_LIN3: start 48, 1 bit, little-endian, data-type-policy=OVERRIDE, i-signal-type=PRIMITIVE, base-type=BT_EXV1_Err_Ueberspannung_TF, compu {0=Cx0_passive (CM_EXV1_Err_Ueberspannung_TF_Cx0_passive), 1=Cx1_active (CM_EXV1_Err_Ueberspannung_TF_Cx1_active)}, range raw 0..1, transfer-property=PENDING, to Klima(timeout 3.5 s)  # OBD TestFailed Flag, Statusbotschaft für die elektrischen Kältemittelexpansionsventile Fehlermeldung für Ueberspannung
            signal EXV1_Err_Ueberspannung_TNCTOC_XIX_EXV1s_01_XIX_Klima_LIN3: start 49, 1 bit, little-endian, data-type-policy=OVERRIDE, i-signal-type=PRIMITIVE, init-value=1, base-type=BT_EXV1_Err_Ueberspannung_TNCTOC, compu {0=Cx0_DTC_test_completed_this_operation_cylce (CM_EXV1_Err_Ueberspannung_TNCTOC_Cx0_DTC_test_completed_this_operation_cylce), 1=Cx1_DTC_test_not_completed_this_operation_cylce (CM_EXV1_Err_Ueberspannung_TNCTOC_Cx1_DTC_test_not_completed_this_operation_cylce)}, range raw 0..1, transfer-property=PENDING, to Klima(timeout 3.5 s)  # OBD TestFailed Flag, Statusbotschaft für die elektrischen Kältemittelexpansionsventile
            signal EXV1_Err_Unterspannung_TF_XIX_EXV1s_01_XIX_Klima_LIN3: start 50, 1 bit, little-endian, data-type-policy=OVERRIDE, i-signal-type=PRIMITIVE, base-type=BT_EXV1_Err_Unterspannung_TF, compu {0=Cx0_passive (CM_EXV1_Err_Unterspannung_TF_Cx0_passive), 1=Cx1_active (CM_EXV1_Err_Unterspannung_TF_Cx1_active)}, range raw 0..1, transfer-property=PENDING, to Klima(timeout 3.5 s)  # OBD TestFailed Flag, Statusbotschaft für die elektrischen Kältemittelexpansionsventile Fehlermeldung für Unterspannung
            signal EXV1_Err_Unterspannung_TNCTOC_XIX_EXV1s_01_XIX_Klima_LIN3: start 51, 1 bit, little-endian, data-type-policy=OVERRIDE, i-signal-type=PRIMITIVE, init-value=1, base-type=BT_EXV1_Err_Unterspannung_TNCTOC, compu {0=Cx0_DTC_test_completed_this_operation_cylce (CM_EXV1_Err_Unterspannung_TNCTOC_Cx0_DTC_test_completed_this_operation_cylce), 1=Cx1_DTC_test_not_completed_this_operation_cylce (CM_EXV1_Err_Unterspannung_TNCTOC_Cx1_DTC_test_not_completed_this_operation_cylce)}, range raw 0..1, transfer-property=PENDING, to Klima(timeout 3.5 s)  # OBD TestFailed Flag, Statusbotschaft für die elektrischen Kältemittelexpansionsventile
            signal EXV1_Err_Blockierung_TF_XIX_EXV1s_01_XIX_Klima_LIN3: start 52, 1 bit, little-endian, data-type-policy=OVERRIDE, i-signal-type=PRIMITIVE, base-type=BT_EXV1_Err_Blockierung_TF, compu {0=Cx0_passive (CM_EXV1_Err_Blockierung_TF_Cx0_passive), 1=Cx1_active (CM_EXV1_Err_Blockierung_TF_Cx1_active)}, range raw 0..1, transfer-property=PENDING, to Klima(timeout 3.5 s)  # OBD TestFailed Flag, Statusbotschaft für die elektrischen Kältemittelexpansionsventile
            signal EXV1_Err_Blockierung_TNCTOC_XIX_EXV1s_01_XIX_Klima_LIN3: start 53, 1 bit, little-endian, data-type-policy=OVERRIDE, i-signal-type=PRIMITIVE, init-value=1, base-type=BT_EXV1_Err_Blockierung_TNCTOC, compu {0=Cx0_DTC_test_completed_this_operation_cylce (CM_EXV1_Err_Blockierung_TNCTOC_Cx0_DTC_test_completed_this_operation_cylce), 1=Cx1_DTC_test_not_completed_this_operation_cylce (CM_EXV1_Err_Blockierung_TNCTOC_Cx1_DTC_test_not_completed_this_operation_cylce)}, range raw 0..1, transfer-property=PENDING, to Klima(timeout 3.5 s)  # OBD TestFailed Flag, Statusbotschaft für die elektrischen Kältemittelexpansionsventile
            signal EXV1_Err_RAMROMNADChange_TF_XIX_EXV1s_01_XIX_Klima_LIN3: start 54, 1 bit, little-endian, data-type-policy=OVERRIDE, i-signal-type=PRIMITIVE, base-type=BT_EXV1_Err_RAMROMNADChange_TF, compu {0=Cx0_passive (CM_EXV1_Err_RAMROMNADChange_TF_Cx0_passive), 1=Cx1_active (CM_EXV1_Err_RAMROMNADChange_TF_Cx1_active)}, range raw 0..1, transfer-property=PENDING, to Klima(timeout 3.5 s)  # OBD TestFailed Flag, Statusbotschaft für die elektrischen Kältemittelexpansionsventile
            signal EXV1_Err_RAMROMNADChange_TNCTOC_XIX_EXV1s_01_XIX_Klima_LIN3: start 55, 1 bit, little-endian, data-type-policy=OVERRIDE, i-signal-type=PRIMITIVE, init-value=1, base-type=BT_EXV1_Err_RAMROMNADChange_TNCTOC, compu {0=Cx0_DTC_test_completed_this_operation_cylce (CM_EXV1_Err_RAMROMNADChange_TNCTOC_Cx0_DTC_test_completed_this_operation_cylce), 1=Cx1_DTC_test_not_completed_this_operation_cylce (CM_EXV1_Err_RAMROMNADChange_TNCTOC_Cx1_DTC_test_not_completed_this_operation_cylce)}, range raw 0..1, transfer-property=PENDING, to Klima(timeout 3.5 s)  # OBD TestFailed Flag, Statusbotschaft für die elektrischen Kältemittelexpansionsventile
            signal EXV1_Err_Notlaufpos_TF_XIX_EXV1s_01_XIX_Klima_LIN3: start 56, 1 bit, little-endian, data-type-policy=OVERRIDE, i-signal-type=PRIMITIVE, base-type=BT_EXV1_Err_Notlaufpos_TF, compu {0=Cx0_passive (CM_EXV1_Err_Notlaufpos_TF_Cx0_passive), 1=Cx1_active (CM_EXV1_Err_Notlaufpos_TF_Cx1_active)}, range raw 0..1, transfer-property=PENDING, to Klima(timeout 3.5 s)  # OBD TestFailed Flag, Statusbotschaft für die elektrischen Kältemittelexpansionsventile
            signal EXV1_Err_Notlaufpos_TNCTOC_XIX_EXV1s_01_XIX_Klima_LIN3: start 57, 1 bit, little-endian, data-type-policy=OVERRIDE, i-signal-type=PRIMITIVE, init-value=1, base-type=BT_EXV1_Err_Notlaufpos_TNCTOC, compu {0=Cx0_DTC_test_completed_this_operation_cylce (CM_EXV1_Err_Notlaufpos_TNCTOC_Cx0_DTC_test_completed_this_operation_cylce), 1=Cx1_DTC_test_not_completed_this_operation_cylce (CM_EXV1_Err_Notlaufpos_TNCTOC_Cx1_DTC_test_not_completed_this_operation_cylce)}, range raw 0..1, transfer-property=PENDING, to Klima(timeout 3.5 s)  # OBD TestFailed Flag, Statusbotschaft für die elektrischen Kältemittelexpansionsventile
        frame HV_H2s_01_XIX_Klima_LIN3: id 0xF, to Klima, frame-length=8, lin-checksum=ENHANCED
          pdu HV_H2s_01_XIX_Klima_LIN3: length=8, unused-bit-pattern=0
            signal HVH2_I_ist_XIX_HV_H2s_01_XIX_Klima_LIN3: start 0, 8 bit, little-endian, data-type-policy=OVERRIDE, i-signal-type=PRIMITIVE, init-value=254, base-type=BT_HVH2_I_ist, invalid-value=Invalid_HVH2_I_ist_XIX_HV_H2s_01_XIX_Klima_LIN3:255, compu {phys=raw*0.25 for raw 0..253, 254=Cxfe_Init (CM_HVH2_I_ist_Cxfe_Init), 255=Cxff_Fehler (CM_HVH2_I_ist_Cxff_Fehler); unit Unit_Amper}, range phys 0..63.25 Unit_Amper, raw 0..255, unit=Unit_Amper, transfer-property=PENDING, to Klima(timeout 3.5 s)  # PTC Stromverbrauch (max. 63,25A)
            signal HVH2_High_Voltage_XIX_HV_H2s_01_XIX_Klima_LIN3: start 8, 8 bit, little-endian, data-type-policy=OVERRIDE, i-signal-type=PRIMITIVE, init-value=254, base-type=BT_HVH2_High_Voltage, invalid-value=Invalid_HVH2_High_Voltage_XIX_HV_H2s_01_XIX_Klima_LIN3:255, compu {phys=raw*2 for raw 0..253, 254=Cxfe_Init (CM_HVH2_High_Voltage_Cxfe_Init), 255=Cxff_Fehler (CM_HVH2_High_Voltage_Cxff_Fehler); unit Unit_Volt}, range phys 0..506 Unit_Volt, raw 0..255, unit=Unit_Volt, transfer-property=PENDING, to Klima(timeout 3.5 s)  # Supplied High Voltage
            signal HVH2_Status_HVH_XIX_HV_H2s_01_XIX_Klima_LIN3: start 16, 3 bit, little-endian, data-type-policy=OVERRIDE, i-signal-type=PRIMITIVE, init-value=7, base-type=BT_HVH2_Status_HVH, compu {0=Cx0_PTC_OK (CM_HVH2_Status_HVH_Cx0_PTC_OK), 1=Cx1_PTC_defekt (CM_HVH2_Status_HVH_Cx1_PTC_defekt), 2=Cx2_PTC_error (CM_HVH2_Status_HVH_Cx2_PTC_error), 3=Cx3_PTC_degraded_by_HW (CM_HVH2_Status_HVH_Cx3_PTC_degraded_by_HW), 4=Cx4_PTC_degraded_by_SW (CM_HVH2_Status_HVH_Cx4_PTC_degraded_by_SW), 5=Cx5_PTC_overheat_protection (CM_HVH2_Status_HVH_Cx5_PTC_overheat_protection), 6=Cx6_not_defined (CM_HVH2_Status_HVH_Cx6_not_defined), 7=Cx7_Init (CM_HVH2_Status_HVH_Cx7_Init)}, range raw 0..7, transfer-property=PENDING, to Klima(timeout 3.5 s)  # Status der HV-PTC Heizeinheit
            signal HVH2_Status_UBatt_XIX_HV_H2s_01_XIX_Klima_LIN3: start 19, 2 bit, little-endian, data-type-policy=OVERRIDE, i-signal-type=PRIMITIVE, init-value=3, base-type=BT_HVH2_Status_UBatt, compu {0=Cx0_Batterie_OK (CM_HVH2_Status_UBatt_Cx0_Batterie_OK), 1=Cx1_Unterspannung (CM_HVH2_Status_UBatt_Cx1_Unterspannung), 2=Cx2_Ueberspannung (CM_HVH2_Status_UBatt_Cx2_Ueberspannung), 3=Cx3_Init (CM_HVH2_Status_UBatt_Cx3_Init)}, range raw 0..3, transfer-property=PENDING, to Klima(timeout 3.5 s)  # Status der Batteriespannung
            signal HVH2_ResponseError_XIX_HV_H2s_01_XIX_Klima_LIN3: start 21, 1 bit, little-endian, data-type-policy=OVERRIDE, i-signal-type=PRIMITIVE, init-value=0, base-type=BT_HVH2_ResponseError, invalid-value=Invalid_HVH2_ResponseError_XIX_HV_H2s_01_XIX_Klima_LIN3:1, compu {0=Cx0_normal (CM_HVH2_ResponseError_Cx0_normal), 1=Cx1_Fehler (CM_HVH2_ResponseError_Cx1_Fehler)}, range raw 0..1, transfer-property=PENDING, to Klima(timeout 3.5 s)  # siehe LIN2.0-Specification (Darf nicht über ein Fehlergueltigkeitsbit abgesichtert werden!)
            signal HVH2_HV_ERR_XIX_HV_H2s_01_XIX_Klima_LIN3: start 22, 2 bit, little-endian, data-type-policy=OVERRIDE, i-signal-type=PRIMITIVE, init-value=0, base-type=BT_HVH2_HV_ERR, compu {0=Cx0_No_Error (CM_HVH2_HV_ERR_Cx0_No_Error), 1=Cx1_High_Voltage_too_low (CM_HVH2_HV_ERR_Cx1_High_Voltage_too_low), 2=Cx2_High_Voltage_too_high (CM_HVH2_HV_ERR_Cx2_High_Voltage_too_high)}, range raw 0..2, transfer-property=PENDING, to Klima(timeout 3.5 s)  # Kurzschluss erkannt
            signal HVH2_Err_Heizkreis_1_XIX_HV_H2s_01_XIX_Klima_LIN3: start 24, 1 bit, little-endian, data-type-policy=OVERRIDE, i-signal-type=PRIMITIVE, init-value=0, base-type=BT_HVH2_Err_Heizkreis_1, invalid-value=Invalid_HVH2_Err_Heizkreis_1_XIX_HV_H2s_01_XIX_Klima_LIN3:1, compu {0=Cx0_normal (CM_HVH2_Err_Heizkreis_1_Cx0_normal), 1=Cx1_Fehler (CM_HVH2_Err_Heizkreis_1_Cx1_Fehler)}, range raw 0..1, transfer-property=PENDING, to Klima(timeout 3.5 s)  # Bit wird gesetzt wenn Fehler in Heizkreis 1
            signal HVH2_Err_Heizkreis_2_XIX_HV_H2s_01_XIX_Klima_LIN3: start 25, 1 bit, little-endian, data-type-policy=OVERRIDE, i-signal-type=PRIMITIVE, init-value=0, base-type=BT_HVH2_Err_Heizkreis_2, invalid-value=Invalid_HVH2_Err_Heizkreis_2_XIX_HV_H2s_01_XIX_Klima_LIN3:1, compu {0=Cx0_normal (CM_HVH2_Err_Heizkreis_2_Cx0_normal), 1=Cx1_Fehler (CM_HVH2_Err_Heizkreis_2_Cx1_Fehler)}, range raw 0..1, transfer-property=PENDING, to Klima(timeout 3.5 s)  # Bit wird gesetzt wenn Fehler in Heizkreis 2
            signal HVH2_Err_Heizkreis_3_XIX_HV_H2s_01_XIX_Klima_LIN3: start 26, 1 bit, little-endian, data-type-policy=OVERRIDE, i-signal-type=PRIMITIVE, init-value=0, base-type=BT_HVH2_Err_Heizkreis_3, invalid-value=Invalid_HVH2_Err_Heizkreis_3_XIX_HV_H2s_01_XIX_Klima_LIN3:1, compu {0=Cx0_normal (CM_HVH2_Err_Heizkreis_3_Cx0_normal), 1=Cx1_Fehler (CM_HVH2_Err_Heizkreis_3_Cx1_Fehler)}, range raw 0..1, transfer-property=PENDING, to Klima(timeout 3.5 s)  # Bit wird gesetzt wenn Fehler in Heizkreis 3
            signal HVH2_Err_Leckagestrom_XIX_HV_H2s_01_XIX_Klima_LIN3: start 27, 1 bit, little-endian, data-type-policy=OVERRIDE, i-signal-type=PRIMITIVE, init-value=0, base-type=BT_HVH2_Err_Leckagestrom, invalid-value=Invalid_HVH2_Err_Leckagestrom_XIX_HV_H2s_01_XIX_Klima_LIN3:1, compu {0=Cx0_normal (CM_HVH2_Err_Leckagestrom_Cx0_normal), 1=Cx1_Fehler (CM_HVH2_Err_Leckagestrom_Cx1_Fehler)}, range raw 0..1, transfer-property=PENDING, to Klima(timeout 3.5 s)  # Bit wird gesetzt, wenn Strom fließt obwohl kein Heizkreis angesteuert wird ( IGBT Fehler)
            signal HVH2_Err_Ueberstromabschaltung_XIX_HV_H2s_01_XIX_Klima_LIN3: start 28, 1 bit, little-endian, data-type-policy=OVERRIDE, i-signal-type=PRIMITIVE, init-value=0, base-type=BT_HVH2_Err_Ueberstromabschaltung, compu {0=Cx0_inaktiv (CM_HVH2_Err_Ueberstromabschaltung_Cx0_inaktiv), 1=Cx1_aktiv (CM_HVH2_Err_Ueberstromabschaltung_Cx1_aktiv)}, range raw 0..1, transfer-property=PENDING, to Klima(timeout 3.5 s)  # Bit wird gesetzt, wenn über längeren Zeitraum ein zu hoher Gesamtstrom fließt (I Heizkreise > definierte Gesamtstromaufnahme)
            signal HVH2_Err_Temperaturschutz_XIX_HV_H2s_01_XIX_Klima_LIN3: start 29, 1 bit, little-endian, data-type-policy=OVERRIDE, i-signal-type=PRIMITIVE, init-value=0, base-type=BT_HVH2_Err_Temperaturschutz, compu {0=Cx0_inaktiv (CM_HVH2_Err_Temperaturschutz_Cx0_inaktiv), 1=Cx1_aktiv (CM_HVH2_Err_Temperaturschutz_Cx1_aktiv)}, range raw 0..1, transfer-property=PENDING, to Klima(timeout 3.5 s)  # Bit wird gesetzt wenn die PlatinenTemperatur ihren Abschaltwert erreicht, Rücknahme bei erreichen der Einschalttemperaturschwelle
            signal HVH2_Err_intern_XIX_HV_H2s_01_XIX_Klima_LIN3: start 30, 1 bit, little-endian, data-type-policy=OVERRIDE, i-signal-type=PRIMITIVE, init-value=0, base-type=BT_HVH2_Err_intern, invalid-value=Invalid_HVH2_Err_intern_XIX_HV_H2s_01_XIX_Klima_LIN3:1, compu {0=Cx0_normal (CM_HVH2_Err_intern_Cx0_normal), 1=Cx1_Fehler (CM_HVH2_Err_intern_Cx1_Fehler)}, range raw 0..1, transfer-property=PENDING, to Klima(timeout 3.5 s)  # Biit soll gesetzt werden, bei allen anderen internen Fehlern, welche denkbar sind (z.B CPU- oder EEPROM Error; AD_Wandler defekt etc)
            signal HVH2_Timeout_Fehler_XIX_HV_H2s_01_XIX_Klima_LIN3: start 31, 1 bit, little-endian, data-type-policy=OVERRIDE, i-signal-type=PRIMITIVE, init-value=0, base-type=BT_HVH2_Timeout_Fehler, compu {0=Cx0_no_timeout (CM_HVH2_Timeout_Fehler_Cx0_no_timeout), 1=Cx1_timeout_detected (CM_HVH2_Timeout_Fehler_Cx1_timeout_detected)}, range raw 0..1, transfer-property=PENDING, to Klima(timeout 3.5 s)  # TPC hat zu lange keine Empfangsframes mehr erhalten (Dieser Fehler muss nicht über einen Fehlergueltigkeitsbit abgesichert werden).
            signal HVH2_UBatt_XIX_HV_H2s_01_XIX_Klima_LIN3: start 32, 8 bit, little-endian, data-type-policy=OVERRIDE, i-signal-type=PRIMITIVE, init-value=254, base-type=BT_HVH2_UBatt, invalid-value=Invalid_HVH2_UBatt_XIX_HV_H2s_01_XIX_Klima_LIN3:255, compu {phys=raw*0.1 for raw 0..253, 254=Cxfe_Init (CM_HVH2_UBatt_Cxfe_Init), 255=Cxff_Fehler (CM_HVH2_UBatt_Cxff_Fehler); unit Unit_Volt}, range phys 0..25.3 Unit_Volt, raw 0..255, unit=Unit_Volt, transfer-property=PENDING, to Klima(timeout 3.5 s)  # Gemessene Batteriespannung
            signal HVH2_Temp_PCB_XIX_HV_H2s_01_XIX_Klima_LIN3: start 40, 8 bit, little-endian, data-type-policy=OVERRIDE, i-signal-type=PRIMITIVE, init-value=254, base-type=BT_HVH2_Temp_PCB, invalid-value=Invalid_HVH2_Temp_PCB_XIX_HV_H2s_01_XIX_Klima_LIN3:255, compu {phys=raw-50 for raw 0..200, 254=Cxfe_Init (CM_HVH2_Temp_PCB_Cxfe_Init), 255=Cxff_Fehler (CM_HVH2_Temp_PCB_Cxff_Fehler); unit Unit_DegreCelsi}, range phys -50..150 Unit_DegreCelsi, raw 0..255, unit=Unit_DegreCelsi, transfer-property=PENDING, to Klima(timeout 3.5 s)  # Temperatur der PTC Ekektronik und der Platine (PCB)
            signal HVH2_Heizmedium_Sensor_1_XIX_HV_H2s_01_XIX_Klima_LIN3: start 48, 8 bit, little-endian, data-type-policy=OVERRIDE, i-signal-type=PRIMITIVE, init-value=254, base-type=BT_HVH2_Heizmedium_Sensor_1, invalid-value=Invalid_HVH2_Heizmedium_Sensor_1_XIX_HV_H2s_01_XIX_Klima_LIN3:255, compu {phys=raw-50 for raw 0..220, 254=Cxfe_Init (CM_HVH2_Heizmedium_Sensor_1_Cxfe_Init), 255=Cxff_Fehler (CM_HVH2_Heizmedium_Sensor_1_Cxff_Fehler); unit Unit_DegreCelsi}, range phys -50..170 Unit_DegreCelsi, raw 0..255, unit=Unit_DegreCelsi, transfer-property=PENDING, to Klima(timeout 3.5 s)  # Gemessene Wassereinlasstemperatur
            signal HVH2_Heizmedium_Sensor_2_XIX_HV_H2s_01_XIX_Klima_LIN3: start 56, 8 bit, little-endian, data-type-policy=OVERRIDE, i-signal-type=PRIMITIVE, init-value=254, base-type=BT_HVH2_Heizmedium_Sensor_2, invalid-value=Invalid_HVH2_Heizmedium_Sensor_2_XIX_HV_H2s_01_XIX_Klima_LIN3:255, compu {phys=raw-50 for raw 0..220, 254=Cxfe_Init (CM_HVH2_Heizmedium_Sensor_2_Cxfe_Init), 255=Cxff_Fehler (CM_HVH2_Heizmedium_Sensor_2_Cxff_Fehler); unit Unit_DegreCelsi}, range phys -50..170 Unit_DegreCelsi, raw 0..255, unit=Unit_DegreCelsi, transfer-property=PENDING, to Klima(timeout 3.5 s)  # Gemessene Wasserauslasstemperatur
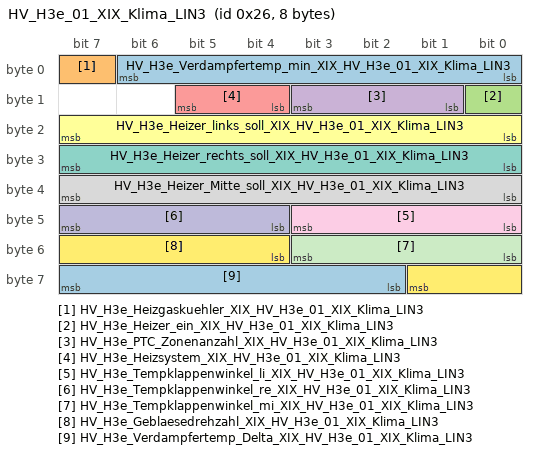
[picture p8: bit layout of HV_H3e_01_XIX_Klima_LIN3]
        frame HV_H3e_01_XIX_Klima_LIN3: id 0x26, from Klima, frame-length=8, lin-checksum=ENHANCED
          pdu HV_H3e_01_XIX_Klima_LIN3: length=8, unused-bit-pattern=0
            signal HV_H3e_Verdampfertemp_min_XIX_HV_H3e_01_XIX_Klima_LIN3: start 0, 7 bit, little-endian, data-type-policy=OVERRIDE, i-signal-type=PRIMITIVE, init-value=126, base-type=BT_HV_H3e_Verdampfertemp_min, invalid-value=Invalid_HV_H3e_Verdampfertemp_min_XIX_HV_H3e_01_XIX_Klima_LIN3:127, compu {phys=raw-30 for raw 0..120, 126=Cx7e_Init (CM_HV_H3e_Verdampfertemp_min_Cx7e_Init), 127=Cx7f_Fehler (CM_HV_H3e_Verdampfertemp_min_Cx7f_Fehler); unit Unit_DegreCelsi}, range phys -30..90 Unit_DegreCelsi, raw 0..127, unit=Unit_DegreCelsi, transfer-property=PENDING  # Minimale Verdampfertemperatur Heizklimagerät
            signal HV_H3e_Heizgaskuehler_XIX_HV_H3e_01_XIX_Klima_LIN3: start 7, 1 bit, little-endian, data-type-policy=OVERRIDE, i-signal-type=PRIMITIVE, init-value=0, base-type=BT_HV_H3e_Heizgaskuehler, compu {0=Cx0_Aus (CM_HV_H3e_Heizgaskuehler_Cx0_Aus), 1=Cx1_Ein (CM_HV_H3e_Heizgaskuehler_Cx1_Ein)}, range raw 0..1, transfer-property=PENDING  # Status Heizgaskühler aus der Wärmepumpe (aus/ein)
            signal HV_H3e_Heizer_ein_XIX_HV_H3e_01_XIX_Klima_LIN3: start 8, 1 bit, little-endian, data-type-policy=OVERRIDE, i-signal-type=PRIMITIVE, init-value=0, base-type=BT_HV_H3e_Heizer_ein, compu {0=Cx0_Aus (CM_HV_H3e_Heizer_ein_Cx0_Aus), 1=Cx1_Ein (CM_HV_H3e_Heizer_ein_Cx1_Ein)}, range raw 0..1, transfer-property=PENDING  # Heizer Aus/Ein
            signal HV_H3e_PTC_Zonenanzahl_XIX_HV_H3e_01_XIX_Klima_LIN3: start 9, 3 bit, little-endian, data-type-policy=OVERRIDE, i-signal-type=PRIMITIVE, init-value=0, base-type=BT_HV_H3e_PTC_Zonenanzahl, compu {0=Cx0_Init (CM_HV_H3e_PTC_Zonenanzahl_Cx0_Init), 1=Cx1_Eine_Zone (CM_HV_H3e_PTC_Zonenanzahl_Cx1_Eine_Zone), 2=Cx2_Zwei_Zonen (CM_HV_H3e_PTC_Zonenanzahl_Cx2_Zwei_Zonen), 3=Cx3_Drei_Zonen (CM_HV_H3e_PTC_Zonenanzahl_Cx3_Drei_Zonen), 4=Cx4_reserviert (CM_HV_H3e_PTC_Zonenanzahl_Cx4_reserviert), 5=Cx5_reserviert (CM_HV_H3e_PTC_Zonenanzahl_Cx5_reserviert), 6=Cx6_reserviert (CM_HV_H3e_PTC_Zonenanzahl_Cx6_reserviert), 7=Cx7_reserviert (CM_HV_H3e_PTC_Zonenanzahl_Cx7_reserviert)}, range raw 0..7, transfer-property=PENDING  # Anzahl Heizzonen
            signal HV_H3e_Heizsystem_XIX_HV_H3e_01_XIX_Klima_LIN3: start 12, 2 bit, little-endian, data-type-policy=OVERRIDE, i-signal-type=PRIMITIVE, base-type=BT_HV_H3e_Heizsystem, compu {0=Cx0_Basis_System (CM_HV_H3e_Heizsystem_Cx0_Basis_System), 1=Cx1_WP (CM_HV_H3e_Heizsystem_Cx1_WP), 2=Cx2_WP_nur_Heizer (CM_HV_H3e_Heizsystem_Cx2_WP_nur_Heizer), 3=Cx3_reserviert (CM_HV_H3e_Heizsystem_Cx3_reserviert)}, range raw 0..3, transfer-property=PENDING  # Info über das verwendete Heizsystem
            signal HV_H3e_Heizer_links_soll_XIX_HV_H3e_01_XIX_Klima_LIN3: start 16, 8 bit, little-endian, data-type-policy=OVERRIDE, i-signal-type=PRIMITIVE, init-value=254, base-type=BT_HV_H3e_Heizer_links_soll, compu {phys=raw for raw 0..100, 254=Cxfe_Init (CM_HV_H3e_Heizer_links_soll_Cxfe_Init); unit Unit_PerCent}, range phys 0..100 Unit_PerCent, raw 0..254, unit=Unit_PerCent, transfer-property=PENDING  # Calculated maximum Heater Power left coming from Master ECU
            signal HV_H3e_Heizer_rechts_soll_XIX_HV_H3e_01_XIX_Klima_LIN3: start 24, 8 bit, little-endian, data-type-policy=OVERRIDE, i-signal-type=PRIMITIVE, init-value=254, base-type=BT_HV_H3e_Heizer_rechts_soll, compu {phys=raw for raw 0..100, 254=Cxfe_Init (CM_HV_H3e_Heizer_rechts_soll_Cxfe_Init); unit Unit_PerCent}, range phys 0..100 Unit_PerCent, raw 0..254, unit=Unit_PerCent, transfer-property=PENDING  # Calculated maximum Heater Power right coming from Master ECU
            signal HV_H3e_Heizer_Mitte_soll_XIX_HV_H3e_01_XIX_Klima_LIN3: start 32, 8 bit, little-endian, data-type-policy=OVERRIDE, i-signal-type=PRIMITIVE, init-value=254, base-type=BT_HV_H3e_Heizer_Mitte_soll, compu {phys=raw for raw 0..100, 254=Cxfe_Init (CM_HV_H3e_Heizer_Mitte_soll_Cxfe_Init); unit Unit_PerCent}, range phys 0..100 Unit_PerCent, raw 0..254, unit=Unit_PerCent, transfer-property=PENDING  # Calculated maximum Heater Power center coming from Master ECU
            signal HV_H3e_Tempklappenwinkel_li_XIX_HV_H3e_01_XIX_Klima_LIN3: start 40, 4 bit, little-endian, data-type-policy=OVERRIDE, i-signal-type=PRIMITIVE, init-value=14, base-type=BT_HV_H3e_Tempklappenwinkel_li, compu {phys=raw*10 for raw 0..10, 14=Cxe_Init (CM_HV_H3e_Tempklappenwinkel_li_Cxe_Init); unit Unit_PerCent}, range phys 0..100 Unit_PerCent, raw 0..14, unit=Unit_PerCent, transfer-property=PENDING  # Temperaturklappenwinkel der Temperaturklappe links
            signal HV_H3e_Tempklappenwinkel_re_XIX_HV_H3e_01_XIX_Klima_LIN3: start 44, 4 bit, little-endian, data-type-policy=OVERRIDE, i-signal-type=PRIMITIVE, init-value=14, base-type=BT_HV_H3e_Tempklappenwinkel_re, compu {phys=raw*10 for raw 0..10, 14=Cxe_Init (CM_HV_H3e_Tempklappenwinkel_re_Cxe_Init); unit Unit_PerCent}, range phys 0..100 Unit_PerCent, raw 0..14, unit=Unit_PerCent, transfer-property=PENDING  # Temperaturklappenwinkel der Temperaturklappe rechts
            signal HV_H3e_Tempklappenwinkel_mi_XIX_HV_H3e_01_XIX_Klima_LIN3: start 48, 4 bit, little-endian, data-type-policy=OVERRIDE, i-signal-type=PRIMITIVE, init-value=14, base-type=BT_HV_H3e_Tempklappenwinkel_mi, compu {phys=raw*10 for raw 0..10, 14=Cxe_Init (CM_HV_H3e_Tempklappenwinkel_mi_Cxe_Init); unit Unit_PerCent}, range phys 0..100 Unit_PerCent, raw 0..14, unit=Unit_PerCent, transfer-property=PENDING  # Temperaturklappenwinkel der Temperaturklappe mitte
            signal HV_H3e_Geblaesedrehzahl_XIX_HV_H3e_01_XIX_Klima_LIN3: start 52, 6 bit, little-endian, data-type-policy=OVERRIDE, i-signal-type=PRIMITIVE, init-value=62, base-type=BT_HV_H3e_Geblaesedrehzahl, invalid-value=Invalid_HV_H3e_Geblaesedrehzahl_XIX_HV_H3e_01_XIX_Klima_LIN3:63, compu {phys=raw*100 for raw 0..50, 62=Cx3e_Init (CM_HV_H3e_Geblaesedrehzahl_Cx3e_Init), 63=Cx3f_Fehler (CM_HV_H3e_Geblaesedrehzahl_Cx3f_Fehler); unit Unit_MinutInver}, range phys 0..5000 Unit_MinutInver, raw 0..63, unit=Unit_MinutInver, transfer-property=PENDING  # Gebläsedrehzahl Frontklimagerät
            signal HV_H3e_Verdampfertemp_Delta_XIX_HV_H3e_01_XIX_Klima_LIN3: start 58, 6 bit, little-endian, data-type-policy=OVERRIDE, i-signal-type=PRIMITIVE, init-value=62, base-type=BT_HV_H3e_Verdampfertemp_Delta, invalid-value=Invalid_HV_H3e_Verdampfertemp_Delta_XIX_HV_H3e_01_XIX_Klima_LIN3:63, compu {phys=raw for raw 0..60, 62=Cx3e_Init (CM_HV_H3e_Verdampfertemp_Delta_Cx3e_Init), 63=Cx3f_Fehler (CM_HV_H3e_Verdampfertemp_Delta_Cx3f_Fehler); unit Unit_DegreCelsi}, range phys 0..60 Unit_DegreCelsi, raw 0..63, unit=Unit_DegreCelsi, transfer-property=PENDING  # Temperaturdelta zu minimal Verdampfertemperatur Heizklimagerät
        frame HV_H3s_01_XIX_Klima_LIN3: id 0x13, to Klima, frame-length=8, lin-checksum=ENHANCED
          pdu HV_H3s_01_XIX_Klima_LIN3: length=8, unused-bit-pattern=0
            signal HV_H3_I_ist_XIX_HV_H3s_01_XIX_Klima_LIN3: start 0, 8 bit, little-endian, data-type-policy=OVERRIDE, i-signal-type=PRIMITIVE, init-value=254, base-type=BT_HV_H3_I_ist, invalid-value=Invalid_HV_H3_I_ist_XIX_HV_H3s_01_XIX_Klima_LIN3:255, compu {phys=raw*0.25 for raw 0..253, 254=Cxfe_Init (CM_HV_H3_I_ist_Cxfe_Init), 255=Cxff_Fehler (CM_HV_H3_I_ist_Cxff_Fehler); unit Unit_Amper}, range phys 0..63.25 Unit_Amper, raw 0..255, unit=Unit_Amper, transfer-property=PENDING, to Klima(timeout 3.5 s)  # HV_H Stromverbrauch (max. 63,25A)
            signal HV_H3_HIGH_VOLTAGE_XIX_HV_H3s_01_XIX_Klima_LIN3: start 8, 8 bit, little-endian, data-type-policy=OVERRIDE, i-signal-type=PRIMITIVE, init-value=254, base-type=BT_HV_H3_HIGH_VOLTAGE, invalid-value=Invalid_HV_H3_HIGH_VOLTAGE_XIX_HV_H3s_01_XIX_Klima_LIN3:255, compu {phys=raw*2 for raw 0..253, 254=Cxfe_Init (CM_HV_H3_HIGH_VOLTAGE_Cxfe_Init), 255=Cxff_Fehler (CM_HV_H3_HIGH_VOLTAGE_Cxff_Fehler); unit Unit_Volt}, range phys 0..506 Unit_Volt, raw 0..255, unit=Unit_Volt, transfer-property=PENDING, to Klima(timeout 3.5 s)  # Supplied High Voltage
            signal HV_H3_Status_Heizer_XIX_HV_H3s_01_XIX_Klima_LIN3: start 16, 3 bit, little-endian, data-type-policy=OVERRIDE, i-signal-type=PRIMITIVE, init-value=7, base-type=BT_HV_H3_Status_Heizer, compu {0=Cx0_Heizer_OK (CM_HV_H3_Status_Heizer_Cx0_Heizer_OK), 1=Cx1_Heizer_defekt (CM_HV_H3_Status_Heizer_Cx1_Heizer_defekt), 2=Cx2_Heizer_error (CM_HV_H3_Status_Heizer_Cx2_Heizer_error), 3=Cx3_Heizer_degraded_by_HW (CM_HV_H3_Status_Heizer_Cx3_Heizer_degraded_by_HW), 4=Cx4_Heizer_degraded_by_SW (CM_HV_H3_Status_Heizer_Cx4_Heizer_degraded_by_SW), 5=Cx5_Heizer_overheat_protection (CM_HV_H3_Status_Heizer_Cx5_Heizer_overheat_protection), 6=Cx6_not_defined (CM_HV_H3_Status_Heizer_Cx6_not_defined), 7=Cx7_Init (CM_HV_H3_Status_Heizer_Cx7_Init)}, range raw 0..7, transfer-property=PENDING, to Klima(timeout 3.5 s)  # Status der HV-Heizer Heizeinheit
            signal HV_H3_Status_UBatt_NV_XIX_HV_H3s_01_XIX_Klima_LIN3: start 19, 2 bit, little-endian, data-type-policy=OVERRIDE, i-signal-type=PRIMITIVE, init-value=3, base-type=BT_HV_H3_Status_UBatt_NV, compu {0=Cx0_Batterie_OK (CM_HV_H3_Status_UBatt_NV_Cx0_Batterie_OK), 1=Cx1_Unterspannung (CM_HV_H3_Status_UBatt_NV_Cx1_Unterspannung), 2=Cx2_Ueberspannung (CM_HV_H3_Status_UBatt_NV_Cx2_Ueberspannung), 3=Cx3_Init (CM_HV_H3_Status_UBatt_NV_Cx3_Init)}, range raw 0..3, transfer-property=PENDING, to Klima(timeout 3.5 s)  # Status der Batteriespannung
            signal HV_H3_ResponseError_XIX_HV_H3s_01_XIX_Klima_LIN3: start 21, 1 bit, little-endian, data-type-policy=OVERRIDE, i-signal-type=PRIMITIVE, init-value=0, base-type=BT_HV_H3_ResponseError, invalid-value=Invalid_HV_H3_ResponseError_XIX_HV_H3s_01_XIX_Klima_LIN3:1, compu {0=Cx0_normal (CM_HV_H3_ResponseError_Cx0_normal), 1=Cx1_Fehler (CM_HV_H3_ResponseError_Cx1_Fehler)}, range raw 0..1, transfer-property=PENDING, to Klima(timeout 3.5 s)  # siehe LIN2.0-Specification (Darf nicht über ein Fehlergueltigkeitsbit abgesichtert werden!)
            signal HV_H3_HIGH_VOLTAGE_ERR_XIX_HV_H3s_01_XIX_Klima_LIN3: start 22, 2 bit, little-endian, data-type-policy=OVERRIDE, i-signal-type=PRIMITIVE, init-value=0, base-type=BT_HV_H3_HIGH_VOLTAGE_ERR, compu {0=Cx0_No_Error (CM_HV_H3_HIGH_VOLTAGE_ERR_Cx0_No_Error), 1=Cx1_High_Voltage_too_low (CM_HV_H3_HIGH_VOLTAGE_ERR_Cx1_High_Voltage_too_low), 2=Cx2_High_Voltage_too_high (CM_HV_H3_HIGH_VOLTAGE_ERR_Cx2_High_Voltage_too_high)}, range raw 0..2, transfer-property=PENDING, to Klima(timeout 3.5 s)  # Fehlerstatus HV
            signal HV_H3_Err_Leckagestrom_XIX_HV_H3s_01_XIX_Klima_LIN3: start 27, 1 bit, little-endian, data-type-policy=OVERRIDE, i-signal-type=PRIMITIVE, init-value=0, base-type=BT_HV_H3_Err_Leckagestrom, invalid-value=Invalid_HV_H3_Err_Leckagestrom_XIX_HV_H3s_01_XIX_Klima_LIN3:1, compu {0=Cx0_normal (CM_HV_H3_Err_Leckagestrom_Cx0_normal), 1=Cx1_Fehler (CM_HV_H3_Err_Leckagestrom_Cx1_Fehler)}, range raw 0..1, transfer-property=PENDING, to Klima(timeout 3.5 s)  # Bit wird gesetzt, wenn Strom fließt obwohl kein Heizkreis angesteuert wird ( IGBT Fehler)
            signal HV_H3_Err_Ueberstromabschaltung_XIX_HV_H3s_01_XIX_Klima_LIN3: start 28, 1 bit, little-endian, data-type-policy=OVERRIDE, i-signal-type=PRIMITIVE, init-value=0, base-type=BT_HV_H3_Err_Ueberstromabschaltung, invalid-value=Invalid_HV_H3_Err_Ueberstromabschaltung_XIX_HV_H3s_01_XIX_Klima_LIN3:1, compu {0=Cx0_normal (CM_HV_H3_Err_Ueberstromabschaltung_Cx0_normal), 1=Cx1_Fehler (CM_HV_H3_Err_Ueberstromabschaltung_Cx1_Fehler)}, range raw 0..1, transfer-property=PENDING, to Klima(timeout 3.5 s)  # Bit wird gesetzt, wenn über längeren Zeitraum ein zu hoher Gesamtstrom fließt (I Heizkreise > definierte Gesamtstromaufnahme)
            signal HV_H3_Err_Temperaturschutz_XIX_HV_H3s_01_XIX_Klima_LIN3: start 29, 1 bit, little-endian, data-type-policy=OVERRIDE, i-signal-type=PRIMITIVE, init-value=0, base-type=BT_HV_H3_Err_Temperaturschutz, invalid-value=Invalid_HV_H3_Err_Temperaturschutz_XIX_HV_H3s_01_XIX_Klima_LIN3:1, compu {0=Cx0_normal (CM_HV_H3_Err_Temperaturschutz_Cx0_normal), 1=Cx1_Fehler (CM_HV_H3_Err_Temperaturschutz_Cx1_Fehler)}, range raw 0..1, transfer-property=PENDING, to Klima(timeout 3.5 s)  # Bit wird gesetzt wenn die PlatinenTemperatur ihren Abschaltwert erreicht, Rücknahme bei erreichen der Einschalttemperaturschwelle
            signal HV_H3_Err_intern_XIX_HV_H3s_01_XIX_Klima_LIN3: start 30, 1 bit, little-endian, data-type-policy=OVERRIDE, i-signal-type=PRIMITIVE, init-value=0, base-type=BT_HV_H3_Err_intern, invalid-value=Invalid_HV_H3_Err_intern_XIX_HV_H3s_01_XIX_Klima_LIN3:1, compu {0=Cx0_normal (CM_HV_H3_Err_intern_Cx0_normal), 1=Cx1_Fehler (CM_HV_H3_Err_intern_Cx1_Fehler)}, range raw 0..1, transfer-property=PENDING, to Klima(timeout 3.5 s)  # Biit soll gesetzt werden, bei allen anderen internen Fehlern, welche denkbar sind (z.B CPU- oder EEPROM Error; AD_Wandler defekt etc)
            signal HV_H3_TimeOut_Fehler_XIX_HV_H3s_01_XIX_Klima_LIN3: start 31, 1 bit, little-endian, data-type-policy=OVERRIDE, i-signal-type=PRIMITIVE, init-value=0, base-type=BT_HV_H3_TimeOut_Fehler, compu {0=Cx0_no_timeout (CM_HV_H3_TimeOut_Fehler_Cx0_no_timeout), 1=Cx1_timeout_detected (CM_HV_H3_TimeOut_Fehler_Cx1_timeout_detected)}, range raw 0..1, transfer-property=PENDING, to Klima(timeout 3.5 s)  # Heizer hat zu lange keine Empfangsframes mehr erhalten (Dieser Fehler muss nicht über einen Fehlergueltigkeitsbit abgesichert werden).
            signal HV_H3_UBatt_NV_XIX_HV_H3s_01_XIX_Klima_LIN3: start 32, 8 bit, little-endian, data-type-policy=OVERRIDE, i-signal-type=PRIMITIVE, init-value=254, base-type=BT_HV_H3_UBatt_NV, invalid-value=Invalid_HV_H3_UBatt_NV_XIX_HV_H3s_01_XIX_Klima_LIN3:255, compu {phys=raw*0.1 for raw 0..253, 254=Cxfe_Init (CM_HV_H3_UBatt_NV_Cxfe_Init), 255=Cxff_Fehler (CM_HV_H3_UBatt_NV_Cxff_Fehler); unit Unit_Volt}, range phys 0..25.3 Unit_Volt, raw 0..255, unit=Unit_Volt, transfer-property=PENDING, to Klima(timeout 3.5 s)  # Gemessene Batteriespannung
            signal HV_H3_Temp_PCB_XIX_HV_H3s_01_XIX_Klima_LIN3: start 40, 8 bit, little-endian, data-type-policy=OVERRIDE, i-signal-type=PRIMITIVE, init-value=254, base-type=BT_HV_H3_Temp_PCB, invalid-value=Invalid_HV_H3_Temp_PCB_XIX_HV_H3s_01_XIX_Klima_LIN3:255, compu {phys=raw-50 for raw 0..200, 254=Cxfe_Init (CM_HV_H3_Temp_PCB_Cxfe_Init), 255=Cxff_Fehler (CM_HV_H3_Temp_PCB_Cxff_Fehler); unit Unit_DegreCelsi}, range phys -50..150 Unit_DegreCelsi, raw 0..255, unit=Unit_DegreCelsi, transfer-property=PENDING, to Klima(timeout 3.5 s)  # Temperatur der Heizer Ekektronik und der Platine (PCB)
            signal HV_H3_Status_Heizkreis_1_XIX_HV_H3s_01_XIX_Klima_LIN3: start 48, 2 bit, little-endian, data-type-policy=OVERRIDE, i-signal-type=PRIMITIVE, init-value=0, base-type=BT_HV_H3_Status_Heizkreis_1, compu {0=Cx0_normal (CM_HV_H3_Status_Heizkreis_1_Cx0_normal), 1=Cx1_Degraded_by_Temp (CM_HV_H3_Status_Heizkreis_1_Cx1_Degraded_by_Temp), 2=Cx2_Switched_off_by_Temp (CM_HV_H3_Status_Heizkreis_1_Cx2_Switched_off_by_Temp), 3=Cx3_Fehler_HK (CM_HV_H3_Status_Heizkreis_1_Cx3_Fehler_HK)}, range raw 0..3, transfer-property=PENDING, to Klima(timeout 3.5 s)  # Status vom Heizkreis 1
            signal HV_H3_Status_Heizkreis_2_XIX_HV_H3s_01_XIX_Klima_LIN3: start 50, 2 bit, little-endian, data-type-policy=OVERRIDE, i-signal-type=PRIMITIVE, init-value=0, base-type=BT_HV_H3_Status_Heizkreis_2, compu {0=Cx0_normal (CM_HV_H3_Status_Heizkreis_2_Cx0_normal), 1=Cx1_Degraded_by_Temp (CM_HV_H3_Status_Heizkreis_2_Cx1_Degraded_by_Temp), 2=Cx2_Switched_off_by_Temp (CM_HV_H3_Status_Heizkreis_2_Cx2_Switched_off_by_Temp), 3=Cx3_Fehler_HK (CM_HV_H3_Status_Heizkreis_2_Cx3_Fehler_HK)}, range raw 0..3, transfer-property=PENDING, to Klima(timeout 3.5 s)  # Status vom Heizkreis 2
            signal HV_H3_Status_Heizkreis_3_XIX_HV_H3s_01_XIX_Klima_LIN3: start 52, 2 bit, little-endian, data-type-policy=OVERRIDE, i-signal-type=PRIMITIVE, init-value=0, base-type=BT_HV_H3_Status_Heizkreis_3, compu {0=Cx0_normal (CM_HV_H3_Status_Heizkreis_3_Cx0_normal), 1=Cx1_Degraded_by_Temp (CM_HV_H3_Status_Heizkreis_3_Cx1_Degraded_by_Temp), 2=Cx2_Switched_off_by_Temp (CM_HV_H3_Status_Heizkreis_3_Cx2_Switched_off_by_Temp), 3=Cx3_Fehler_HK (CM_HV_H3_Status_Heizkreis_3_Cx3_Fehler_HK)}, range raw 0..3, transfer-property=PENDING, to Klima(timeout 3.5 s)  # Status vom Heizkreis 3
            signal HV_H3_Status_Heizkreis_4_XIX_HV_H3s_01_XIX_Klima_LIN3: start 54, 2 bit, little-endian, data-type-policy=OVERRIDE, i-signal-type=PRIMITIVE, init-value=0, base-type=BT_HV_H3_Status_Heizkreis_4, compu {0=Cx0_normal (CM_HV_H3_Status_Heizkreis_4_Cx0_normal), 1=Cx1_Degraded_by_Temp (CM_HV_H3_Status_Heizkreis_4_Cx1_Degraded_by_Temp), 2=Cx2_Switched_off_by_Temp (CM_HV_H3_Status_Heizkreis_4_Cx2_Switched_off_by_Temp), 3=Cx3_Error_HK (CM_HV_H3_Status_Heizkreis_4_Cx3_Error_HK)}, range raw 0..3, transfer-property=PENDING, to Klima(timeout 3.5 s)  # Status vom Heizkreis 4
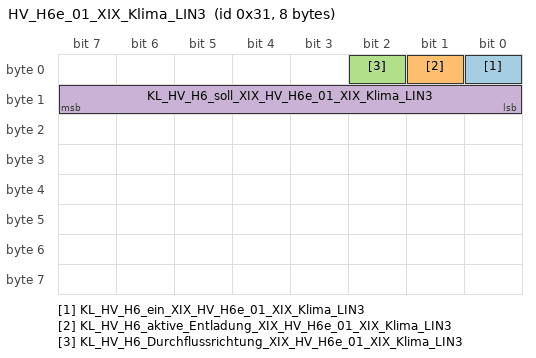
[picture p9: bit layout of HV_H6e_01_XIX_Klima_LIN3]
        frame HV_H6e_01_XIX_Klima_LIN3: id 0x31, from Klima, frame-length=8, lin-checksum=ENHANCED
          pdu HV_H6e_01_XIX_Klima_LIN3: length=8, unused-bit-pattern=0
            signal KL_HV_H6_ein_XIX_HV_H6e_01_XIX_Klima_LIN3: start 0, 1 bit, little-endian, data-type-policy=OVERRIDE, i-signal-type=PRIMITIVE, init-value=0, base-type=BT_KL_HV_H6_ein, compu {0=Cx0_Aus (CM_KL_HV_H6_ein_Cx0_Aus), 1=Cx1_Ein (CM_KL_HV_H6_ein_Cx1_Ein)}, range raw 0..1, transfer-property=PENDING  # PTC Aus/Ein Heizerdiagnose wird damit aktiv geschaltet Spannungsmessung immer aktiv
            signal KL_HV_H6_aktive_Entladung_XIX_HV_H6e_01_XIX_Klima_LIN3: start 1, 1 bit, little-endian, data-type-policy=OVERRIDE, i-signal-type=PRIMITIVE, init-value=0, base-type=BT_KL_HV_H6_aktive_Entladung, compu {0=Cx0_Keine_aktive_Entladung_Init (CM_KL_HV_H6_aktive_Entladung_Cx0_Keine_aktive_Entladung_Init), 1=Cx1_Aktive_Entladung (CM_KL_HV_H6_aktive_Entladung_Cx1_Aktive_Entladung)}, range raw 0..1, transfer-property=PENDING  # Auslösen der aktiven Entladung des HV-Heizers
            signal KL_HV_H6_Durchflussrichtung_XIX_HV_H6e_01_XIX_Klima_LIN3: start 2, 1 bit, little-endian, data-type-policy=OVERRIDE, i-signal-type=PRIMITIVE, base-type=BT_KL_HV_H6_Durchflussrichtung, compu {0=Cx0_normal (CM_KL_HV_H6_Durchflussrichtung_Cx0_normal), 1=Cx1_inverse (CM_KL_HV_H6_Durchflussrichtung_Cx1_inverse)}, range raw 0..1, transfer-property=PENDING  # Durchflussrichtung durch den HV-Heizer
            signal KL_HV_H6_soll_XIX_HV_H6e_01_XIX_Klima_LIN3: start 8, 8 bit, little-endian, data-type-policy=OVERRIDE, i-signal-type=PRIMITIVE, init-value=254, base-type=BT_KL_HV_H6_soll, invalid-value=Invalid_KL_HV_H6_soll_XIX_HV_H6e_01_XIX_Klima_LIN3:255, compu {phys=raw for raw 0..100, 254=Cxfe_Init (CM_KL_HV_H6_soll_Cxfe_Init), 255=Cxff_Fehler (CM_KL_HV_H6_soll_Cxff_Fehler); unit Unit_PerCent}, range phys 0..100 Unit_PerCent, raw 0..255, unit=Unit_PerCent, transfer-property=PENDING  # Ansteuerung des HV-Heizers in Prozent
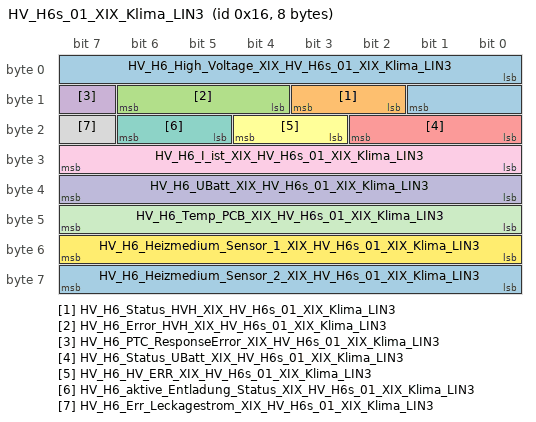
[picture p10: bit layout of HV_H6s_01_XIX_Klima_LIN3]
        frame HV_H6s_01_XIX_Klima_LIN3: id 0x16, to Klima, frame-length=8, lin-checksum=ENHANCED
          pdu HV_H6s_01_XIX_Klima_LIN3: length=8, unused-bit-pattern=0
            signal HV_H6_High_Voltage_XIX_HV_H6s_01_XIX_Klima_LIN3: start 0, 10 bit, little-endian, data-type-policy=OVERRIDE, i-signal-type=PRIMITIVE, init-value=1022, base-type=BT_HV_H6_High_Voltage, invalid-value=Invalid_HV_H6_High_Voltage_XIX_HV_H6s_01_XIX_Klima_LIN3:1023, compu {phys=raw for raw 0..1021, 1022=Cx3fe_Init (CM_HV_H6_High_Voltage_Cx3fe_Init), 1023=Cx3ff_Fehler (CM_HV_H6_High_Voltage_Cx3ff_Fehler); unit Unit_Volt}, range phys 0..1021 Unit_Volt, raw 0..1023, unit=Unit_Volt, transfer-property=PENDING, to Klima(timeout 3.5 s)  # Am HV-Heizer gemessene Hochvolt-Spannung.
            signal HV_H6_Status_HVH_XIX_HV_H6s_01_XIX_Klima_LIN3: start 10, 2 bit, little-endian, data-type-policy=OVERRIDE, i-signal-type=PRIMITIVE, init-value=3, base-type=BT_HV_H6_Status_HVH, compu {0=Cx0_Heizer_OK (CM_HV_H6_Status_HVH_Cx0_Heizer_OK), 1=Cx1_Heizer_degraded_by_HW (CM_HV_H6_Status_HVH_Cx1_Heizer_degraded_by_HW), 2=Cx2_Heizer_degraded_by_SW (CM_HV_H6_Status_HVH_Cx2_Heizer_degraded_by_SW), 3=Cx3_Init (CM_HV_H6_Status_HVH_Cx3_Init)}, range raw 0..3, transfer-property=PENDING, to Klima(timeout 3.5 s)  # Status der HV-Heizer Heizeinheit
            signal HV_H6_Error_HVH_XIX_HV_H6s_01_XIX_Klima_LIN3: start 12, 3 bit, little-endian, data-type-policy=OVERRIDE, i-signal-type=PRIMITIVE, init-value=7, base-type=BT_HV_H6_Error_HVH, compu {0=Cx0_Heizer_OK (CM_HV_H6_Error_HVH_Cx0_Heizer_OK), 1=Cx1_Heizer_defekt (CM_HV_H6_Error_HVH_Cx1_Heizer_defekt), 2=Cx2_Heizer_error (CM_HV_H6_Error_HVH_Cx2_Heizer_error), 3=Cx3_Heizer_overheat_protection (CM_HV_H6_Error_HVH_Cx3_Heizer_overheat_protection), 4=Cx4_not_defined (CM_HV_H6_Error_HVH_Cx4_not_defined), 5=Cx5_not_defined (CM_HV_H6_Error_HVH_Cx5_not_defined), 6=Cx6_not_defined (CM_HV_H6_Error_HVH_Cx6_not_defined), 7=Cx7_Init (CM_HV_H6_Error_HVH_Cx7_Init)}, range raw 0..7, transfer-property=PENDING, to Klima(timeout 3.5 s)  # Fehler der HV-Heizer Heizeinheit
            signal HV_H6_PTC_ResponseError_XIX_HV_H6s_01_XIX_Klima_LIN3: start 15, 1 bit, little-endian, data-type-policy=OVERRIDE, i-signal-type=PRIMITIVE, init-value=0, base-type=BT_HV_H6_PTC_ResponseError, compu {0=Cx0_normal (CM_HV_H6_PTC_ResponseError_Cx0_normal)}, range raw 0, transfer-property=PENDING, to Klima(timeout 3.5 s)  # PTC Response Error
            signal HV_H6_Status_UBatt_XIX_HV_H6s_01_XIX_Klima_LIN3: start 16, 3 bit, little-endian, data-type-policy=OVERRIDE, i-signal-type=PRIMITIVE, init-value=3, base-type=BT_HV_H6_Status_UBatt, compu {0=Cx0_Batterie_OK (CM_HV_H6_Status_UBatt_Cx0_Batterie_OK), 1=Cx1_Unterspannung (CM_HV_H6_Status_UBatt_Cx1_Unterspannung), 2=Cx2_Ueberspannung (CM_HV_H6_Status_UBatt_Cx2_Ueberspannung), 3=Cx3_Init (CM_HV_H6_Status_UBatt_Cx3_Init)}, range raw 0..3, transfer-property=PENDING, to Klima(timeout 3.5 s)  # Status der Batteriespannung
            signal HV_H6_HV_ERR_XIX_HV_H6s_01_XIX_Klima_LIN3: start 19, 2 bit, little-endian, data-type-policy=OVERRIDE, i-signal-type=PRIMITIVE, init-value=0, base-type=BT_HV_H6_HV_ERR, compu {0=Cx0_No_Error (CM_HV_H6_HV_ERR_Cx0_No_Error), 1=Cx1_High_Voltage_too_low (CM_HV_H6_HV_ERR_Cx1_High_Voltage_too_low), 2=Cx2_High_Voltage_too_high (CM_HV_H6_HV_ERR_Cx2_High_Voltage_too_high)}, range raw 0..2, transfer-property=PENDING, to Klima(timeout 3.5 s)  # Kurzschluss erkannt
            signal HV_H6_aktive_Entladung_Status_XIX_HV_H6s_01_XIX_Klima_LIN3: start 21, 2 bit, little-endian, data-type-policy=OVERRIDE, i-signal-type=PRIMITIVE, init-value=0, base-type=BT_HV_H6_aktive_Entladung_Status, compu {0=Cx0_Aus (CM_HV_H6_aktive_Entladung_Status_Cx0_Aus), 1=Cx1_Bereitschaft (CM_HV_H6_aktive_Entladung_Status_Cx1_Bereitschaft), 2=Cx2_aktiv (CM_HV_H6_aktive_Entladung_Status_Cx2_aktiv), 3=Cx3_Init (CM_HV_H6_aktive_Entladung_Status_Cx3_Init)}, range raw 0..3, transfer-property=PENDING, to Klima(timeout 3.5 s)  # Statusrückmeldung zum Zustand aktiven Entladung im HV-Heizer.
            signal HV_H6_Err_Leckagestrom_XIX_HV_H6s_01_XIX_Klima_LIN3: start 23, 1 bit, little-endian, data-type-policy=OVERRIDE, i-signal-type=PRIMITIVE, init-value=0, base-type=BT_HV_H6_Err_Leckagestrom, compu {0=Cx0_normal (CM_HV_H6_Err_Leckagestrom_Cx0_normal)}, range raw 0, transfer-property=PENDING, to Klima(timeout 3.5 s)  # Bit wird gesetzt, wenn Strom fließt obwohl kein Heizkreis angesteuert wird ( IGBT Fehler)
            signal HV_H6_I_ist_XIX_HV_H6s_01_XIX_Klima_LIN3: start 24, 8 bit, little-endian, data-type-policy=OVERRIDE, i-signal-type=PRIMITIVE, init-value=254, base-type=BT_HV_H6_I_ist, invalid-value=Invalid_HV_H6_I_ist_XIX_HV_H6s_01_XIX_Klima_LIN3:255, compu {phys=raw*0.25 for raw 0..253, 254=Cxfe_Init (CM_HV_H6_I_ist_Cxfe_Init), 255=Cxff_Fehler (CM_HV_H6_I_ist_Cxff_Fehler); unit Unit_Amper}, range phys 0..63.25 Unit_Amper, raw 0..255, unit=Unit_Amper, transfer-property=PENDING, to Klima(timeout 3.5 s)  # PTC Stromverbrauch (max. 63,25A)
            signal HV_H6_UBatt_XIX_HV_H6s_01_XIX_Klima_LIN3: start 32, 8 bit, little-endian, data-type-policy=OVERRIDE, i-signal-type=PRIMITIVE, init-value=254, base-type=BT_HV_H6_UBatt, invalid-value=Invalid_HV_H6_UBatt_XIX_HV_H6s_01_XIX_Klima_LIN3:255, compu {phys=raw*0.1 for raw 0..253, 254=Cxfe_Init (CM_HV_H6_UBatt_Cxfe_Init), 255=Cxff_Fehler (CM_HV_H6_UBatt_Cxff_Fehler); unit Unit_Volt}, range phys 0..25.3 Unit_Volt, raw 0..255, unit=Unit_Volt, transfer-property=PENDING, to Klima(timeout 3.5 s)  # Gemessene Batteriespannung
            signal HV_H6_Temp_PCB_XIX_HV_H6s_01_XIX_Klima_LIN3: start 40, 8 bit, little-endian, data-type-policy=OVERRIDE, i-signal-type=PRIMITIVE, init-value=254, base-type=BT_HV_H6_Temp_PCB, invalid-value=Invalid_HV_H6_Temp_PCB_XIX_HV_H6s_01_XIX_Klima_LIN3:255, compu {phys=raw-50 for raw 0..200, 254=Cxfe_Init (CM_HV_H6_Temp_PCB_Cxfe_Init), 255=Cxff_Fehler (CM_HV_H6_Temp_PCB_Cxff_Fehler); unit Unit_DegreCelsi}, range phys -50..150 Unit_DegreCelsi, raw 0..255, unit=Unit_DegreCelsi, transfer-property=PENDING, to Klima(timeout 3.5 s)  # Temperatur der PTC Ekektronik und der Platine (PCB)
            signal HV_H6_Heizmedium_Sensor_1_XIX_HV_H6s_01_XIX_Klima_LIN3: start 48, 8 bit, little-endian, data-type-policy=OVERRIDE, i-signal-type=PRIMITIVE, init-value=254, base-type=BT_HV_H6_Heizmedium_Sensor_1, invalid-value=Invalid_HV_H6_Heizmedium_Sensor_1_XIX_HV_H6s_01_XIX_Klima_LIN3:255, compu {phys=raw-50 for raw 0..220, 254=Cxfe_Init (CM_HV_H6_Heizmedium_Sensor_1_Cxfe_Init), 255=Cxff_Fehler (CM_HV_H6_Heizmedium_Sensor_1_Cxff_Fehler); unit Unit_DegreCelsi}, range phys -50..170 Unit_DegreCelsi, raw 0..255, unit=Unit_DegreCelsi, transfer-property=PENDING, to Klima(timeout 3.5 s)  # Gemessene Wassertemperatur Sensor 1
            signal HV_H6_Heizmedium_Sensor_2_XIX_HV_H6s_01_XIX_Klima_LIN3: start 56, 8 bit, little-endian, data-type-policy=OVERRIDE, i-signal-type=PRIMITIVE, init-value=254, base-type=BT_HV_H6_Heizmedium_Sensor_2, invalid-value=Invalid_HV_H6_Heizmedium_Sensor_2_XIX_HV_H6s_01_XIX_Klima_LIN3:255, compu {phys=raw-50 for raw 0..220, 254=Cxfe_Init (CM_HV_H6_Heizmedium_Sensor_2_Cxfe_Init), 255=Cxff_Fehler (CM_HV_H6_Heizmedium_Sensor_2_Cxff_Fehler); unit Unit_DegreCelsi}, range phys -50..170 Unit_DegreCelsi, raw 0..255, unit=Unit_DegreCelsi, transfer-property=PENDING, to Klima(timeout 3.5 s)  # Gemessene Wassertemperatur Sensor 2
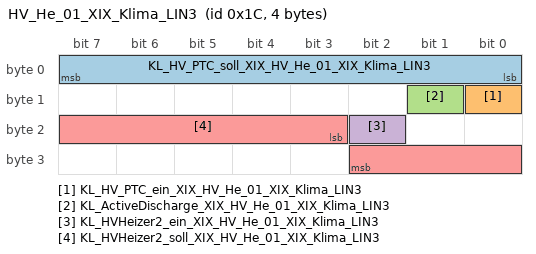
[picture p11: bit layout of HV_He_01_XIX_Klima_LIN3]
        frame HV_He_01_XIX_Klima_LIN3: id 0x1C, from Klima, frame-length=4, lin-checksum=ENHANCED
          pdu HV_He_01_XIX_Klima_LIN3: length=4, unused-bit-pattern=0
            signal KL_HV_PTC_soll_XIX_HV_He_01_XIX_Klima_LIN3: start 0, 8 bit, little-endian, data-type-policy=OVERRIDE, i-signal-type=PRIMITIVE, init-value=254, base-type=BT_KL_HV_PTC_soll, invalid-value=Invalid_KL_HV_PTC_soll_XIX_HV_He_01_XIX_Klima_LIN3:255, compu {phys=raw for raw 0..200, 254=Cxfe_Init (CM_KL_HV_PTC_soll_Cxfe_Init), 255=Cxff_Fehler (CM_KL_HV_PTC_soll_Cxff_Fehler); unit Unit_PerCent}, range phys 0..200 Unit_PerCent, raw 0..255, unit=Unit_PerCent, transfer-property=PENDING  # Calculated maximum HV-PTC Heater Power coming from Motor ECU (Stufige Ansteuerung des PTC im Wertebereich 100-200%)
            signal KL_HV_PTC_ein_XIX_HV_He_01_XIX_Klima_LIN3: start 8, 1 bit, little-endian, data-type-policy=OVERRIDE, i-signal-type=PRIMITIVE, init-value=0, base-type=BT_KL_HV_PTC_ein, compu {0=Cx0_Aus (CM_KL_HV_PTC_ein_Cx0_Aus), 1=Cx1_Ein (CM_KL_HV_PTC_ein_Cx1_Ein)}, range raw 0..1, transfer-property=PENDING  # HV-PTC Aus/Ein
            signal KL_ActiveDischarge_XIX_HV_He_01_XIX_Klima_LIN3: start 9, 1 bit, little-endian, data-type-policy=OVERRIDE, i-signal-type=PRIMITIVE, init-value=0, base-type=BT_KL_ActiveDischarge, compu {0=Cx0_Keine_aktive_Entladung_Init (CM_KL_ActiveDischarge_Cx0_Keine_aktive_Entladung_Init) (Keine_aktive_Entladung__Init), 1=Cx1_Aktive_Entladung (CM_KL_ActiveDischarge_Cx1_Aktive_Entladung)}, range raw 0..1, transfer-property=PENDING  # Anforderung aktive Entladung
            signal KL_HVHeizer2_ein_XIX_HV_He_01_XIX_Klima_LIN3: start 18, 1 bit, little-endian, data-type-policy=OVERRIDE, i-signal-type=PRIMITIVE, init-value=0, base-type=BT_KL_HVHeizer2_ein, compu {0=Cx0_Aus (CM_KL_HVHeizer2_ein_Cx0_Aus), 1=Cx1_Ein (CM_KL_HVHeizer2_ein_Cx1_Ein)}, range raw 0..1, transfer-property=PENDING  # PTC Aus/Ein
            signal KL_HVHeizer2_soll_XIX_HV_He_01_XIX_Klima_LIN3: start 19, 8 bit, little-endian, data-type-policy=OVERRIDE, i-signal-type=PRIMITIVE, init-value=254, base-type=BT_KL_HVHeizer2_soll, invalid-value=Invalid_KL_HVHeizer2_soll_XIX_HV_He_01_XIX_Klima_LIN3:255, compu {phys=raw for raw 0..100, 254=Cxfe_Init (CM_KL_HVHeizer2_soll_Cxfe_Init), 255=Cxff_Fehler (CM_KL_HVHeizer2_soll_Cxff_Fehler); unit Unit_PerCent}, range phys 0..100 Unit_PerCent, raw 0..255, unit=Unit_PerCent, transfer-property=PENDING  # Calculated maximum HV-PTC Heater Power coming from Motor ECU
        frame HV_Hs_01_XIX_Klima_LIN3: id 0x30, to Klima, frame-length=8, lin-checksum=ENHANCED  # HV-PTC
          pdu HV_Hs_01_XIX_Klima_LIN3: length=8, unused-bit-pattern=0  # HV-PTC
            signal PTC_HV_I_ist_XIX_HV_Hs_01_XIX_Klima_LIN3: start 0, 8 bit, little-endian, data-type-policy=OVERRIDE, i-signal-type=PRIMITIVE, init-value=254, base-type=BT_PTC_HV_I_ist, invalid-value=Invalid_PTC_HV_I_ist_XIX_HV_Hs_01_XIX_Klima_LIN3:255, compu {phys=raw*0.25 for raw 0..253, 254=Cxfe_Init (CM_PTC_HV_I_ist_Cxfe_Init), 255=Cxff_Fehler (CM_PTC_HV_I_ist_Cxff_Fehler); unit Unit_Amper}, range phys 0..63.25 Unit_Amper, raw 0..255, unit=Unit_Amper, transfer-property=PENDING, to Klima(timeout 3.5 s)  # PTC Stromverbrauch (max. 63,25A)
            signal PTC_HV_ERR_XIX_HV_Hs_01_XIX_Klima_LIN3: start 8, 2 bit, little-endian, data-type-policy=OVERRIDE, i-signal-type=PRIMITIVE, init-value=3, base-type=BT_PTC_HV_ERR, compu {0=Cx0_No_Error (CM_PTC_HV_ERR_Cx0_No_Error), 1=Cx1_High_Voltage_too_low (CM_PTC_HV_ERR_Cx1_High_Voltage_too_low), 2=Cx2_High_Voltage_too_high (CM_PTC_HV_ERR_Cx2_High_Voltage_too_high), 3=Cx3_Init (CM_PTC_HV_ERR_Cx3_Init)}, range raw 0..3, transfer-property=PENDING, to Klima(timeout 3.5 s)  # State of HV-Power-Supply
            signal PTC_HV_Status_PTC_XIX_HV_Hs_01_XIX_Klima_LIN3: start 16, 3 bit, little-endian, data-type-policy=OVERRIDE, i-signal-type=PRIMITIVE, init-value=7, base-type=BT_PTC_HV_Status_PTC, compu {0=Cx0_HVH_OK (CM_PTC_HV_Status_PTC_Cx0_HVH_OK), 1=Cx1_HVH_defekt (CM_PTC_HV_Status_PTC_Cx1_HVH_defekt), 2=Cx2_HVH_error (CM_PTC_HV_Status_PTC_Cx2_HVH_error), 3=Cx3_HVH_degraded_by_HW (CM_PTC_HV_Status_PTC_Cx3_HVH_degraded_by_HW), 4=Cx4_HVH_degraded_by_SW (CM_PTC_HV_Status_PTC_Cx4_HVH_degraded_by_SW), 5=Cx5_HVH_overheat_protection (CM_PTC_HV_Status_PTC_Cx5_HVH_overheat_protection), 6=Cx6_not_defined (CM_PTC_HV_Status_PTC_Cx6_not_defined), 7=Cx7_Init (CM_PTC_HV_Status_PTC_Cx7_Init)}, range raw 0..7, transfer-property=PENDING, to Klima(timeout 3.5 s)  # Status der HV-PTC Heizeinheit
            signal PTC_HV_Status_UBatt_XIX_HV_Hs_01_XIX_Klima_LIN3: start 19, 2 bit, little-endian, data-type-policy=OVERRIDE, i-signal-type=PRIMITIVE, init-value=3, base-type=BT_PTC_HV_Status_UBatt, compu {0=Cx0_Batterie_OK (CM_PTC_HV_Status_UBatt_Cx0_Batterie_OK), 1=Cx1_Unterspannung (CM_PTC_HV_Status_UBatt_Cx1_Unterspannung), 2=Cx2_Ueberspannung (CM_PTC_HV_Status_UBatt_Cx2_Ueberspannung), 3=Cx3_Init (CM_PTC_HV_Status_UBatt_Cx3_Init)}, range raw 0..3, transfer-property=PENDING, to Klima(timeout 3.5 s)  # Status der Batteriespannung
            signal PTC_HV_ResponseError_XIX_HV_Hs_01_XIX_Klima_LIN3: start 21, 1 bit, little-endian, data-type-policy=OVERRIDE, i-signal-type=PRIMITIVE, init-value=0, base-type=BT_PTC_HV_ResponseError, invalid-value=Invalid_PTC_HV_ResponseError_XIX_HV_Hs_01_XIX_Klima_LIN3:1, compu {0=Cx0_normal (CM_PTC_HV_ResponseError_Cx0_normal), 1=Cx1_Fehler (CM_PTC_HV_ResponseError_Cx1_Fehler)}, range raw 0..1, transfer-property=PENDING, to Klima(timeout 3.5 s)  # siehe LIN2.0-Specification (Darf nicht über ein Fehlergueltigkeitsbit abgesichtert werden!)
            signal PTC_HV_TimeOut_Fehler_XIX_HV_Hs_01_XIX_Klima_LIN3: start 22, 1 bit, little-endian, data-type-policy=OVERRIDE, i-signal-type=PRIMITIVE, init-value=0, base-type=BT_PTC_HV_TimeOut_Fehler, compu {0=Cx0_no_timeout (CM_PTC_HV_TimeOut_Fehler_Cx0_no_timeout), 1=Cx1_timeout_detected (CM_PTC_HV_TimeOut_Fehler_Cx1_timeout_detected)}, range raw 0..1, transfer-property=PENDING, to Klima(timeout 3.5 s)  # HV-PTC hat zu lange keine Empfangsframes mehr erhalten (Dieser Fehler muss nicht über einen Fehlergueltigkeitsbit abgesichert werden).
            signal PTC_HV_Err_Heizkreis_1_XIX_HV_Hs_01_XIX_Klima_LIN3: start 24, 1 bit, little-endian, data-type-policy=OVERRIDE, i-signal-type=PRIMITIVE, init-value=0, base-type=BT_PTC_HV_Err_Heizkreis_1, invalid-value=Invalid_PTC_HV_Err_Heizkreis_1_XIX_HV_Hs_01_XIX_Klima_LIN3:1, compu {0=Cx0_normal (CM_PTC_HV_Err_Heizkreis_1_Cx0_normal), 1=Cx1_Fehler (CM_PTC_HV_Err_Heizkreis_1_Cx1_Fehler)}, range raw 0..1, transfer-property=PENDING, to Klima(timeout 3.5 s)  # Bit wird gesetzt wenn Fehler in Heizkreis 1
            signal PTC_HV_Err_Heizkreis_2_XIX_HV_Hs_01_XIX_Klima_LIN3: start 25, 1 bit, little-endian, data-type-policy=OVERRIDE, i-signal-type=PRIMITIVE, init-value=0, base-type=BT_PTC_HV_Err_Heizkreis_2, invalid-value=Invalid_PTC_HV_Err_Heizkreis_2_XIX_HV_Hs_01_XIX_Klima_LIN3:1, compu {0=Cx0_normal (CM_PTC_HV_Err_Heizkreis_2_Cx0_normal), 1=Cx1_Fehler (CM_PTC_HV_Err_Heizkreis_2_Cx1_Fehler)}, range raw 0..1, transfer-property=PENDING, to Klima(timeout 3.5 s)  # Bit wird gesetzt wenn Fehler in Heizkreis 2
            signal PTC_HV_Err_Heizkreis_3_XIX_HV_Hs_01_XIX_Klima_LIN3: start 26, 1 bit, little-endian, data-type-policy=OVERRIDE, i-signal-type=PRIMITIVE, init-value=0, base-type=BT_PTC_HV_Err_Heizkreis_3, invalid-value=Invalid_PTC_HV_Err_Heizkreis_3_XIX_HV_Hs_01_XIX_Klima_LIN3:1, compu {0=Cx0_normal (CM_PTC_HV_Err_Heizkreis_3_Cx0_normal), 1=Cx1_Fehler (CM_PTC_HV_Err_Heizkreis_3_Cx1_Fehler)}, range raw 0..1, transfer-property=PENDING, to Klima(timeout 3.5 s)  # Bit wird gesetzt wenn Fehler in Heizkreis 3
            signal PTC_HV_Err_Leckagestrom_XIX_HV_Hs_01_XIX_Klima_LIN3: start 27, 1 bit, little-endian, data-type-policy=OVERRIDE, i-signal-type=PRIMITIVE, init-value=0, base-type=BT_PTC_HV_Err_Leckagestrom, invalid-value=Invalid_PTC_HV_Err_Leckagestrom_XIX_HV_Hs_01_XIX_Klima_LIN3:1, compu {0=Cx0_normal (CM_PTC_HV_Err_Leckagestrom_Cx0_normal), 1=Cx1_Fehler (CM_PTC_HV_Err_Leckagestrom_Cx1_Fehler)}, range raw 0..1, transfer-property=PENDING, to Klima(timeout 3.5 s)  # Bit wird gesetzt, wenn Strom fließt obwohl kein Heizkreis angesteuert wird ( IGBT Fehler)
            signal PTC_HV_Err_Ueberstromabschaltung_XIX_HV_Hs_01_XIX_Klima_LIN3: start 28, 1 bit, little-endian, data-type-policy=OVERRIDE, i-signal-type=PRIMITIVE, init-value=0, base-type=BT_PTC_HV_Err_Ueberstromabschaltung, compu {0=Cx0_inaktiv (CM_PTC_HV_Err_Ueberstromabschaltung_Cx0_inaktiv), 1=Cx1_aktiv (CM_PTC_HV_Err_Ueberstromabschaltung_Cx1_aktiv)}, range raw 0..1, transfer-property=PENDING, to Klima(timeout 3.5 s)  # Bit wird gesetzt, wenn über längeren Zeitraum ein zu hoher Gesamtstrom fließt (I Heizkreise > definierte Gesamtstromaufnahme)
            signal PTC_HV_Err_Temperaturschutz_XIX_HV_Hs_01_XIX_Klima_LIN3: start 29, 1 bit, little-endian, data-type-policy=OVERRIDE, i-signal-type=PRIMITIVE, init-value=0, base-type=BT_PTC_HV_Err_Temperaturschutz, compu {0=Cx0_inaktiv (CM_PTC_HV_Err_Temperaturschutz_Cx0_inaktiv), 1=Cx1_aktiv (CM_PTC_HV_Err_Temperaturschutz_Cx1_aktiv)}, range raw 0..1, transfer-property=PENDING, to Klima(timeout 3.5 s)  # Bit wird gesetzt wenn die PlatinenTemperatur ihren Abschaltwert erreicht, Rücknahme bei erreichen der Einschalttemperaturschwelle
            signal PTC_HV_Err_intern_XIX_HV_Hs_01_XIX_Klima_LIN3: start 30, 1 bit, little-endian, data-type-policy=OVERRIDE, i-signal-type=PRIMITIVE, init-value=0, base-type=BT_PTC_HV_Err_intern, invalid-value=Invalid_PTC_HV_Err_intern_XIX_HV_Hs_01_XIX_Klima_LIN3:1, compu {0=Cx0_normal (CM_PTC_HV_Err_intern_Cx0_normal), 1=Cx1_Fehler (CM_PTC_HV_Err_intern_Cx1_Fehler)}, range raw 0..1, transfer-property=PENDING, to Klima(timeout 3.5 s)  # Biit soll gesetzt werden, bei allen anderen internen Fehlern, welche denkbar sind (z.B CPU- oder EEPROM Error; AD_Wandler defekt etc)
            signal PTC_HV_UBatt_XIX_HV_Hs_01_XIX_Klima_LIN3: start 32, 8 bit, little-endian, data-type-policy=OVERRIDE, i-signal-type=PRIMITIVE, init-value=254, base-type=BT_PTC_HV_UBatt, invalid-value=Invalid_PTC_HV_UBatt_XIX_HV_Hs_01_XIX_Klima_LIN3:255, compu {phys=raw*0.1 for raw 0..253, 254=Cxfe_Init (CM_PTC_HV_UBatt_Cxfe_Init), 255=Cxff_Fehler (CM_PTC_HV_UBatt_Cxff_Fehler); unit Unit_Volt}, range phys 0..25.3 Unit_Volt, raw 0..255, unit=Unit_Volt, transfer-property=PENDING, to Klima(timeout 3.5 s)  # Gemessene Batteriespannung
            signal PTC_HV_Temp_PCB_XIX_HV_Hs_01_XIX_Klima_LIN3: start 40, 8 bit, little-endian, data-type-policy=OVERRIDE, i-signal-type=PRIMITIVE, init-value=254, base-type=BT_PTC_HV_Temp_PCB, invalid-value=Invalid_PTC_HV_Temp_PCB_XIX_HV_Hs_01_XIX_Klima_LIN3:255, compu {phys=raw-50 for raw 0..200, 254=Cxfe_Init (CM_PTC_HV_Temp_PCB_Cxfe_Init), 255=Cxff_Fehler (CM_PTC_HV_Temp_PCB_Cxff_Fehler); unit Unit_DegreCelsi}, range phys -50..150 Unit_DegreCelsi, raw 0..255, unit=Unit_DegreCelsi, transfer-property=PENDING, to Klima(timeout 3.5 s)  # Temperatur der PTC Ekektronik und der Platine (PCB)
            signal PTC_HV_Heizmedium_Sensor_1_XIX_HV_Hs_01_XIX_Klima_LIN3: start 48, 8 bit, little-endian, data-type-policy=OVERRIDE, i-signal-type=PRIMITIVE, init-value=254, base-type=BT_PTC_HV_Heizmedium_Sensor_1, invalid-value=Invalid_PTC_HV_Heizmedium_Sensor_1_XIX_HV_Hs_01_XIX_Klima_LIN3:255, compu {phys=raw-50 for raw 0..220, 254=Cxfe_Init (CM_PTC_HV_Heizmedium_Sensor_1_Cxfe_Init), 255=Cxff_Fehler (CM_PTC_HV_Heizmedium_Sensor_1_Cxff_Fehler); unit Unit_DegreCelsi}, range phys -50..170 Unit_DegreCelsi, raw 0..255, unit=Unit_DegreCelsi, transfer-property=PENDING, to Klima(timeout 3.5 s)  # Gemessene Wassereinlasstemperatur
            signal PTC_HV_Heizmedium_Sensor_2_XIX_HV_Hs_01_XIX_Klima_LIN3: start 56, 8 bit, little-endian, data-type-policy=OVERRIDE, i-signal-type=PRIMITIVE, init-value=254, base-type=BT_PTC_HV_Heizmedium_Sensor_2, invalid-value=Invalid_PTC_HV_Heizmedium_Sensor_2_XIX_HV_Hs_01_XIX_Klima_LIN3:255, compu {phys=raw-50 for raw 0..220, 254=Cxfe_Init (CM_PTC_HV_Heizmedium_Sensor_2_Cxfe_Init), 255=Cxff_Fehler (CM_PTC_HV_Heizmedium_Sensor_2_Cxff_Fehler); unit Unit_DegreCelsi}, range phys -50..170 Unit_DegreCelsi, raw 0..255, unit=Unit_DegreCelsi, transfer-property=PENDING, to Klima(timeout 3.5 s)  # Gemessene Wasserauslasstemperatur
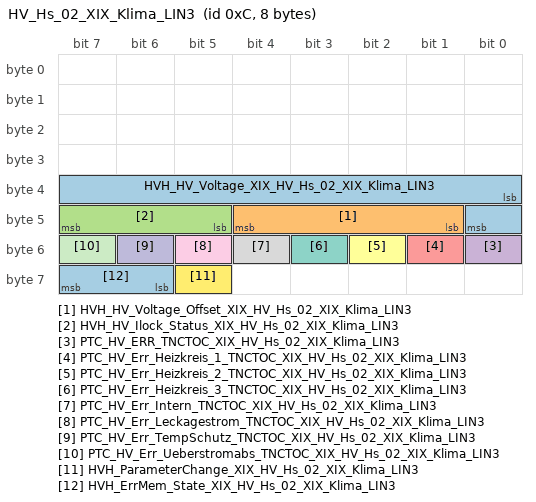
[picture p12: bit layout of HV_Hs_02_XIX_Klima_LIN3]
        frame HV_Hs_02_XIX_Klima_LIN3: id 0xC, to Klima, frame-length=8, lin-checksum=ENHANCED  # HV-PTC
          pdu HV_Hs_02_XIX_Klima_LIN3: length=8, unused-bit-pattern=0  # HV-PTC
            signal HVH_HV_Voltage_XIX_HV_Hs_02_XIX_Klima_LIN3: start 32, 9 bit, little-endian, data-type-policy=OVERRIDE, i-signal-type=PRIMITIVE, init-value=510, base-type=BT_HVH_HV_Voltage, invalid-value=Invalid_HVH_HV_Voltage_XIX_HV_Hs_02_XIX_Klima_LIN3:511, compu {phys=raw*4 for raw 0..509, 510=Cx1fe_Init (CM_HVH_HV_Voltage_Cx1fe_Init), 511=Cx1ff_Fehler (CM_HVH_HV_Voltage_Cx1ff_Fehler); unit Unit_Volt}, range phys 0..2036 Unit_Volt, raw 0..511, unit=Unit_Volt, transfer-property=PENDING, to Klima(timeout 3.5 s)  # Actual meassured High Voltage level of the HVH
            signal HVH_HV_Voltage_Offset_XIX_HV_Hs_02_XIX_Klima_LIN3: start 41, 4 bit, little-endian, data-type-policy=OVERRIDE, i-signal-type=PRIMITIVE, init-value=14, base-type=BT_HVH_HV_Voltage_Offset, invalid-value=Invalid_HVH_HV_Voltage_Offset_XIX_HV_Hs_02_XIX_Klima_LIN3:15, compu {phys=raw*0.5 for raw 0..8, 14=Cxe_Init (CM_HVH_HV_Voltage_Offset_Cxe_Init), 15=Cxf_Fehler (CM_HVH_HV_Voltage_Offset_Cxf_Fehler); unit Unit_Volt}, range phys 0..4 Unit_Volt, raw 0..15, unit=Unit_Volt, transfer-property=PENDING, to Klima(timeout 3.5 s)  # Feinauflösung der HV-Spannung des HV-Heizers
            signal HVH_HV_Ilock_Status_XIX_HV_Hs_02_XIX_Klima_LIN3: start 45, 3 bit, little-endian, data-type-policy=OVERRIDE, i-signal-type=PRIMITIVE, init-value=7, base-type=BT_HVH_HV_Ilock_Status, invalid-value=Invalid_HVH_HV_Ilock_Status_XIX_HV_Hs_02_XIX_Klima_LIN3:2, compu {0=Cx0_Connected (CM_HVH_HV_Ilock_Status_Cx0_Connected), 1=Cx1_Disconnected (CM_HVH_HV_Ilock_Status_Cx1_Disconnected), 2=Cx2_Fehler (CM_HVH_HV_Ilock_Status_Cx2_Fehler), 3=Cx3_unused (CM_HVH_HV_Ilock_Status_Cx3_unused), 4=Cx4_unused (CM_HVH_HV_Ilock_Status_Cx4_unused), 5=Cx5_unused (CM_HVH_HV_Ilock_Status_Cx5_unused), 6=Cx6_unused (CM_HVH_HV_Ilock_Status_Cx6_unused), 7=Cx7_Init (CM_HVH_HV_Ilock_Status_Cx7_Init)}, range raw 0..7, transfer-property=PENDING, to Klima(timeout 3.5 s)  # Status HV-Interlock
            signal PTC_HV_ERR_TNCTOC_XIX_HV_Hs_02_XIX_Klima_LIN3: start 48, 1 bit, little-endian, data-type-policy=OVERRIDE, i-signal-type=PRIMITIVE, init-value=1, base-type=BT_PTC_HV_ERR_TNCTOC, compu {0=Cx0_testcompletedthisoperationcycle (CM_PTC_HV_ERR_TNCTOC_Cx0_testcompletedthisoperationcycle), 1=Cx1_testnotcompleted (CM_PTC_HV_ERR_TNCTOC_Cx1_testnotcompleted)}, range raw 0..1, transfer-property=PENDING, to Klima(timeout 3.5 s)  # Vorhalt OBD-Signal zu PTC_HV_ERR
            signal PTC_HV_Err_Heizkreis_1_TNCTOC_XIX_HV_Hs_02_XIX_Klima_LIN3: start 49, 1 bit, little-endian, data-type-policy=OVERRIDE, i-signal-type=PRIMITIVE, init-value=1, base-type=BT_PTC_HV_Err_Heizkreis_1_TNCTOC, compu {0=Cx0_TestDurchlaufen (CM_PTC_HV_Err_Heizkreis_1_TNCTOC_Cx0_TestDurchlaufen), 1=Cx1_TestNichtDurchlaufen (CM_PTC_HV_Err_Heizkreis_1_TNCTOC_Cx1_TestNichtDurchlaufen)}, range raw 0..1, transfer-property=PENDING, to Klima(timeout 3.5 s)  # TNCTOC: test not completed this operation cycle
            signal PTC_HV_Err_Heizkreis_2_TNCTOC_XIX_HV_Hs_02_XIX_Klima_LIN3: start 50, 1 bit, little-endian, data-type-policy=OVERRIDE, i-signal-type=PRIMITIVE, init-value=1, base-type=BT_PTC_HV_Err_Heizkreis_2_TNCTOC, compu {0=Cx0_TestDurchlaufen (CM_PTC_HV_Err_Heizkreis_2_TNCTOC_Cx0_TestDurchlaufen), 1=Cx1_TestNichtDurchlaufen (CM_PTC_HV_Err_Heizkreis_2_TNCTOC_Cx1_TestNichtDurchlaufen)}, range raw 0..1, transfer-property=PENDING, to Klima(timeout 3.5 s)  # TNCTOC: test not completed this operation cycle
            signal PTC_HV_Err_Heizkreis_3_TNCTOC_XIX_HV_Hs_02_XIX_Klima_LIN3: start 51, 1 bit, little-endian, data-type-policy=OVERRIDE, i-signal-type=PRIMITIVE, init-value=1, base-type=BT_PTC_HV_Err_Heizkreis_3_TNCTOC, compu {0=Cx0_TestDurchlaufen (CM_PTC_HV_Err_Heizkreis_3_TNCTOC_Cx0_TestDurchlaufen), 1=Cx1_TestNichtDurchlaufen (CM_PTC_HV_Err_Heizkreis_3_TNCTOC_Cx1_TestNichtDurchlaufen)}, range raw 0..1, transfer-property=PENDING, to Klima(timeout 3.5 s)  # TNCTOC: test not completed this operation cycle
            signal PTC_HV_Err_Intern_TNCTOC_XIX_HV_Hs_02_XIX_Klima_LIN3: start 52, 1 bit, little-endian, data-type-policy=OVERRIDE, i-signal-type=PRIMITIVE, init-value=1, base-type=BT_PTC_HV_Err_Intern_TNCTOC, compu {0=Cx0_TestDurchlaufen (CM_PTC_HV_Err_Intern_TNCTOC_Cx0_TestDurchlaufen), 1=Cx1_TestNichtDurchlaufen (CM_PTC_HV_Err_Intern_TNCTOC_Cx1_TestNichtDurchlaufen)}, range raw 0..1, transfer-property=PENDING, to Klima(timeout 3.5 s)  # TNCTOC: test not completed this operation cycle
            signal PTC_HV_Err_Leckagestrom_TNCTOC_XIX_HV_Hs_02_XIX_Klima_LIN3: start 53, 1 bit, little-endian, data-type-policy=OVERRIDE, i-signal-type=PRIMITIVE, init-value=1, base-type=BT_PTC_HV_Err_Leckagestrom_TNCTOC, compu {0=Cx0_TestDurchlaufen (CM_PTC_HV_Err_Leckagestrom_TNCTOC_Cx0_TestDurchlaufen), 1=Cx1_TestNichtDurchlaufen (CM_PTC_HV_Err_Leckagestrom_TNCTOC_Cx1_TestNichtDurchlaufen)}, range raw 0..1, transfer-property=PENDING, to Klima(timeout 3.5 s)  # TNCTOC: test not completed this operation cycle
            signal PTC_HV_Err_TempSchutz_TNCTOC_XIX_HV_Hs_02_XIX_Klima_LIN3: start 54, 1 bit, little-endian, data-type-policy=OVERRIDE, i-signal-type=PRIMITIVE, init-value=1, base-type=BT_PTC_HV_Err_TempSchutz_TNCTOC, compu {0=Cx0_TestDurchlaufen (CM_PTC_HV_Err_TempSchutz_TNCTOC_Cx0_TestDurchlaufen), 1=Cx1_TestNichtDurchlaufen (CM_PTC_HV_Err_TempSchutz_TNCTOC_Cx1_TestNichtDurchlaufen)}, range raw 0..1, transfer-property=PENDING, to Klima(timeout 3.5 s)  # TNCTOC: test not completed this operation cycle
            signal PTC_HV_Err_Ueberstromabs_TNCTOC_XIX_HV_Hs_02_XIX_Klima_LIN3: start 55, 1 bit, little-endian, data-type-policy=OVERRIDE, i-signal-type=PRIMITIVE, init-value=1, base-type=BT_PTC_HV_Err_Ueberstromabs_TNCTOC, compu {0=Cx0_TestDurchlaufen (CM_PTC_HV_Err_Ueberstromabs_TNCTOC_Cx0_TestDurchlaufen), 1=Cx1_TestNichtDurchlaufen (CM_PTC_HV_Err_Ueberstromabs_TNCTOC_Cx1_TestNichtDurchlaufen)}, range raw 0..1, transfer-property=PENDING, to Klima(timeout 3.5 s)  # TNCTOC: test not completed this operation cycle
            signal HVH_ParameterChange_XIX_HV_Hs_02_XIX_Klima_LIN3: start 61, 1 bit, little-endian, data-type-policy=OVERRIDE, i-signal-type=PRIMITIVE, base-type=BT_HVH_ParameterChange, compu {0=Cx0_noParameterChange (CM_HVH_ParameterChange_Cx0_noParameterChange), 1=Cx1_ParameterChange (CM_HVH_ParameterChange_Cx1_ParameterChange)}, range raw 0..1, transfer-property=PENDING, to Klima(timeout 3.5 s)  # Im LIN Slave wurde ein Parameter geändert, der eine Neuberechnung der CALID/CVN nach sich zieht. Das Bit wird auf '0' gesetzt, wenn seitens des DK4 eine Abfrage der CALID/CVN angestoßen und das DK1/2-System diese vollständig versendet hat.
            signal HVH_ErrMem_State_XIX_HV_Hs_02_XIX_Klima_LIN3: start 62, 2 bit, little-endian, data-type-policy=OVERRIDE, i-signal-type=PRIMITIVE, init-value=0, base-type=BT_HVH_ErrMem_State, compu {0=Cx0_Init (CM_HVH_ErrMem_State_Cx0_Init), 1=Cx1_Normalbetrieb (CM_HVH_ErrMem_State_Cx1_Normalbetrieb), 2=Cx2_WertNachEmpfangMode04Request (CM_HVH_ErrMem_State_Cx2_WertNachEmpfangMode04Request), 3=Cx3_WertNachInitialisierung (CM_HVH_ErrMem_State_Cx3_WertNachInitialisierung)}, range raw 0..3, transfer-property=PENDING, to Klima(timeout 3.5 s)  # ErrMem_Init_done: Wird nach erfolgreichem löschen im LIN Slave für die Teit t_InitDone gesetzt und bedeutet, dass initialisiert wurde und ErrMem wieder aktiv ist. Nach Zeit t_InitDone wird der Wert 'ErrMem_Active_State' zurückgesetzt.
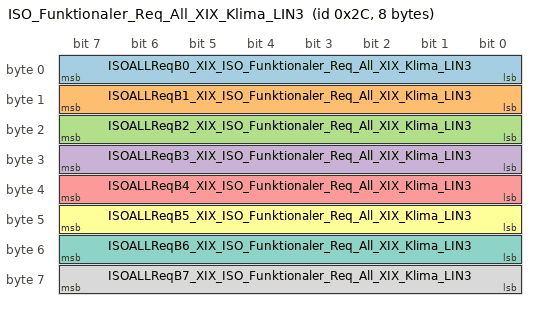
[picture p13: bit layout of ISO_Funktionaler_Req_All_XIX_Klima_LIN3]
        frame ISO_Funktionaler_Req_All_XIX_Klima_LIN3: id 0x2C, from Klima, frame-length=8, lin-checksum=ENHANCED
          pdu ISO_Funktionaler_Req_All_XIX_Klima_LIN3: length=8, unused-bit-pattern=0
            signal ISOALLReqB0_XIX_ISO_Funktionaler_Req_All_XIX_Klima_LIN3: start 0, 8 bit, little-endian, data-type-policy=OVERRIDE, i-signal-type=PRIMITIVE, base-type=BT_ISOALLReqB0, transfer-property=PENDING  # Für DK3-Funktion / DK1-2-OBD-Systeme auf LIN
            signal ISOALLReqB1_XIX_ISO_Funktionaler_Req_All_XIX_Klima_LIN3: start 8, 8 bit, little-endian, data-type-policy=OVERRIDE, i-signal-type=PRIMITIVE, base-type=BT_ISOALLReqB1, transfer-property=PENDING  # Für DK3-Funktion / DK1-2-OBD-Systeme auf LIN
            signal ISOALLReqB2_XIX_ISO_Funktionaler_Req_All_XIX_Klima_LIN3: start 16, 8 bit, little-endian, data-type-policy=OVERRIDE, i-signal-type=PRIMITIVE, base-type=BT_ISOALLReqB2, transfer-property=PENDING  # Für DK3-Funktion / DK1-2-OBD-Systeme auf LIN
            signal ISOALLReqB3_XIX_ISO_Funktionaler_Req_All_XIX_Klima_LIN3: start 24, 8 bit, little-endian, data-type-policy=OVERRIDE, i-signal-type=PRIMITIVE, base-type=BT_ISOALLReqB3, transfer-property=PENDING  # Für DK3-Funktion / DK1-2-OBD-Systeme auf LIN
            signal ISOALLReqB4_XIX_ISO_Funktionaler_Req_All_XIX_Klima_LIN3: start 32, 8 bit, little-endian, data-type-policy=OVERRIDE, i-signal-type=PRIMITIVE, base-type=BT_ISOALLReqB4, transfer-property=PENDING  # Für DK3-Funktion / DK1-2-OBD-Systeme auf LIN
            signal ISOALLReqB5_XIX_ISO_Funktionaler_Req_All_XIX_Klima_LIN3: start 40, 8 bit, little-endian, data-type-policy=OVERRIDE, i-signal-type=PRIMITIVE, base-type=BT_ISOALLReqB5, transfer-property=PENDING  # Für DK3-Funktion / DK1-2-OBD-Systeme auf LIN
            signal ISOALLReqB6_XIX_ISO_Funktionaler_Req_All_XIX_Klima_LIN3: start 48, 8 bit, little-endian, data-type-policy=OVERRIDE, i-signal-type=PRIMITIVE, base-type=BT_ISOALLReqB6, transfer-property=PENDING  # Für DK3-Funktion / DK1-2-OBD-Systeme auf LIN
            signal ISOALLReqB7_XIX_ISO_Funktionaler_Req_All_XIX_Klima_LIN3: start 56, 8 bit, little-endian, data-type-policy=OVERRIDE, i-signal-type=PRIMITIVE, base-type=BT_ISOALLReqB7, transfer-property=PENDING  # Für DK3-Funktion / DK1-2-OBD-Systeme auf LIN
        frame MasterReq_XIX_Klima_LIN3: id 0x3C, from Klima, frame-length=8, lin-checksum=CLASSIC
          n pdu MasterReq_XIX_Klima_LIN3: length=8
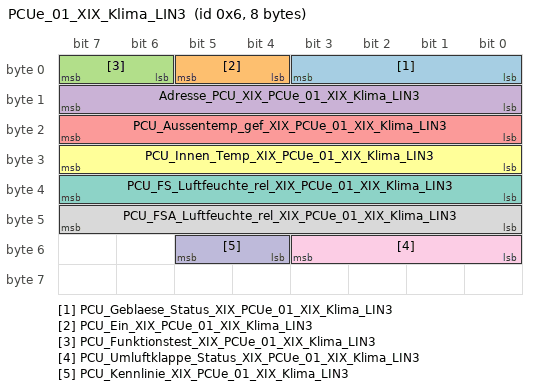
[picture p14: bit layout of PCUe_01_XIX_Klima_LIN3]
        frame PCUe_01_XIX_Klima_LIN3: id 0x6, from Klima, frame-length=8, lin-checksum=ENHANCED
          pdu PCUe_01_XIX_Klima_LIN3: length=8, unused-bit-pattern=0
            signal PCU_Geblaese_Status_XIX_PCUe_01_XIX_Klima_LIN3: start 0, 4 bit, little-endian, data-type-policy=OVERRIDE, i-signal-type=PRIMITIVE, init-value=14, base-type=BT_PCU_Geblaese_Status, invalid-value=Invalid_PCU_Geblaese_Status_XIX_PCUe_01_XIX_Klima_LIN3:15, compu {0=Cx0_Geblaese_aus (CM_PCU_Geblaese_Status_Cx0_Geblaese_aus), 1=Cx1_Geblaesestufe_10 (CM_PCU_Geblaese_Status_Cx1_Geblaesestufe_10), 2=Cx2_Geblaesestufe_20 (CM_PCU_Geblaese_Status_Cx2_Geblaesestufe_20), 3=Cx3_Geblaesestufe_30 (CM_PCU_Geblaese_Status_Cx3_Geblaesestufe_30), 4=Cx4_Geblaesestufe_40 (CM_PCU_Geblaese_Status_Cx4_Geblaesestufe_40), 5=Cx5_Geblaesestufe_50 (CM_PCU_Geblaese_Status_Cx5_Geblaesestufe_50), 6=Cx6_Geblaesestufe_60 (CM_PCU_Geblaese_Status_Cx6_Geblaesestufe_60), 7=Cx7_Geblaesestufe_70 (CM_PCU_Geblaese_Status_Cx7_Geblaesestufe_70), 8=Cx8_Geblaesestufe_80 (CM_PCU_Geblaese_Status_Cx8_Geblaesestufe_80), 9=Cx9_Geblaesestufe_90 (CM_PCU_Geblaese_Status_Cx9_Geblaesestufe_90), 10=Cxa_Geblaesestufe_100 (CM_PCU_Geblaese_Status_Cxa_Geblaesestufe_100), 14=Cxe_Init (CM_PCU_Geblaese_Status_Cxe_Init), 15=Cxf_Fehler (CM_PCU_Geblaese_Status_Cxf_Fehler)}, range raw 0..15, transfer-property=PENDING  # Status Geblaese
            signal PCU_Ein_XIX_PCUe_01_XIX_Klima_LIN3: start 4, 2 bit, little-endian, data-type-policy=OVERRIDE, i-signal-type=PRIMITIVE, init-value=3, base-type=BT_PCU_Ein, compu {0=Cx0_PCU_off (CM_PCU_Ein_Cx0_PCU_off), 1=Cx1_PCU_on (CM_PCU_Ein_Cx1_PCU_on), 2=Cx2_PCU_Auto (CM_PCU_Ein_Cx2_PCU_Auto), 3=Cx3_Init (CM_PCU_Ein_Cx3_Init)}, range raw 0..3, transfer-property=PENDING  # Dieses Signal bescreibt den Ein/Aus zusatnd der PCU
            signal PCU_Funktionstest_XIX_PCUe_01_XIX_Klima_LIN3: start 6, 2 bit, little-endian, data-type-policy=OVERRIDE, i-signal-type=PRIMITIVE, init-value=0, base-type=BT_PCU_Funktionstest, compu {0=Cx0_Inaktiv (CM_PCU_Funktionstest_Cx0_Inaktiv), 1=Cx1_Test_Leitungssatz (CM_PCU_Funktionstest_Cx1_Test_Leitungssatz), 2=Cx2_Steckerpruefung (CM_PCU_Funktionstest_Cx2_Steckerpruefung) (Steckerprüfung), 3=Cx3_Elektronikpruefung (CM_PCU_Funktionstest_Cx3_Elektronikpruefung) (Elektronikprüfung)}, range raw 0..3, transfer-property=PENDING  # Ansteuersignal PCU zur Prüfung ChargingUnit
            signal Adresse_PCU_XIX_PCUe_01_XIX_Klima_LIN3: start 8, 8 bit, little-endian, data-type-policy=OVERRIDE, i-signal-type=PRIMITIVE, init-value=0, base-type=BT_Adresse_PCU, compu {phys=raw for raw 0..255; unit Unit_None}, range phys 0..255 Unit_None, raw 0..255, unit=Unit_None, transfer-property=PENDING  # LIN Speicher lesen
            signal PCU_Aussentemp_gef_XIX_PCUe_01_XIX_Klima_LIN3: start 16, 8 bit, little-endian, data-type-policy=OVERRIDE, i-signal-type=PRIMITIVE, init-value=254, base-type=BT_PCU_Aussentemp_gef, invalid-value=Invalid_PCU_Aussentemp_gef_XIX_PCUe_01_XIX_Klima_LIN3:255, compu {phys=raw*0.5-40 for raw 0..250, 254=Cxfe_Init (CM_PCU_Aussentemp_gef_Cxfe_Init), 255=Cxff_Fehler (CM_PCU_Aussentemp_gef_Cxff_Fehler); unit Unit_DegreCelsi}, range phys -40..85 Unit_DegreCelsi, raw 0..255, unit=Unit_DegreCelsi, transfer-property=PENDING  # gefilterte Aussentemperatur
            signal PCU_Innen_Temp_XIX_PCUe_01_XIX_Klima_LIN3: start 24, 8 bit, little-endian, data-type-policy=OVERRIDE, i-signal-type=PRIMITIVE, init-value=254, base-type=BT_PCU_Innen_Temp, invalid-value=Invalid_PCU_Innen_Temp_XIX_PCUe_01_XIX_Klima_LIN3:255, compu {phys=raw*0.5-50 for raw 0..252, 253=Cxfd_nicht_verbaut (CM_PCU_Innen_Temp_Cxfd_nicht_verbaut), 254=Cxfe_nicht_verfuegbar (CM_PCU_Innen_Temp_Cxfe_nicht_verfuegbar), 255=Cxff_Fehler (CM_PCU_Innen_Temp_Cxff_Fehler); unit Unit_DegreCelsi}, range phys -50..76 Unit_DegreCelsi, raw 0..255, unit=Unit_DegreCelsi, transfer-property=PENDING  # Innentemperatur
            signal PCU_FS_Luftfeuchte_rel_XIX_PCUe_01_XIX_Klima_LIN3: start 32, 8 bit, little-endian, data-type-policy=OVERRIDE, i-signal-type=PRIMITIVE, init-value=0, base-type=BT_PCU_FS_Luftfeuchte_rel, invalid-value=Invalid_PCU_FS_Luftfeuchte_rel_XIX_PCUe_01_XIX_Klima_LIN3:255, compu {0=Cx0_nicht_verfuegbar (CM_PCU_FS_Luftfeuchte_rel_Cx0_nicht_verfuegbar), phys=raw*0.5-0.5 for raw 1..201, 255=Cxff_Fehler (CM_PCU_FS_Luftfeuchte_rel_Cxff_Fehler); unit Unit_PerCent}, range phys 0..100 Unit_PerCent, raw 0..255, unit=Unit_PerCent, transfer-property=PENDING  # Dieses Signal beschreibt die Luftfeuchte innen
            signal PCU_FSA_Luftfeuchte_rel_XIX_PCUe_01_XIX_Klima_LIN3: start 40, 8 bit, little-endian, data-type-policy=OVERRIDE, i-signal-type=PRIMITIVE, init-value=254, base-type=BT_PCU_FSA_Luftfeuchte_rel, invalid-value=Invalid_PCU_FSA_Luftfeuchte_rel_XIX_PCUe_01_XIX_Klima_LIN3:255, compu {phys=raw*0.5 for raw 0..252, 253=Cxfd_nicht_verbaut (CM_PCU_FSA_Luftfeuchte_rel_Cxfd_nicht_verbaut), 254=Cxfe_Init (CM_PCU_FSA_Luftfeuchte_rel_Cxfe_Init), 255=Cxff_Fehler (CM_PCU_FSA_Luftfeuchte_rel_Cxff_Fehler); unit Unit_PerCent}, range phys 0..126 Unit_PerCent, raw 0..255, unit=Unit_PerCent, transfer-property=PENDING  # Luftfeuchte außen
            signal PCU_Umluftklappe_Status_XIX_PCUe_01_XIX_Klima_LIN3: start 48, 4 bit, little-endian, data-type-policy=OVERRIDE, i-signal-type=PRIMITIVE, init-value=14, base-type=BT_PCU_Umluftklappe_Status, invalid-value=Invalid_PCU_Umluftklappe_Status_XIX_PCUe_01_XIX_Klima_LIN3:15, compu {0=Cx0_Frischluft (CM_PCU_Umluftklappe_Status_Cx0_Frischluft), 1=Cx1_Teilumluft_10 (CM_PCU_Umluftklappe_Status_Cx1_Teilumluft_10), 2=Cx2_Teilumluft_20 (CM_PCU_Umluftklappe_Status_Cx2_Teilumluft_20), 3=Cx3_Teilumluft_30 (CM_PCU_Umluftklappe_Status_Cx3_Teilumluft_30), 4=Cx4_Teilumluft_40 (CM_PCU_Umluftklappe_Status_Cx4_Teilumluft_40), 5=Cx5_Teilumluft_50 (CM_PCU_Umluftklappe_Status_Cx5_Teilumluft_50), 6=Cx6_Teilumluft_60 (CM_PCU_Umluftklappe_Status_Cx6_Teilumluft_60), 7=Cx7_Teilumluft_70 (CM_PCU_Umluftklappe_Status_Cx7_Teilumluft_70), 8=Cx8_Teilumluft_80 (CM_PCU_Umluftklappe_Status_Cx8_Teilumluft_80), 9=Cx9_Teilumluft_90 (CM_PCU_Umluftklappe_Status_Cx9_Teilumluft_90), 10=Cxa_Umluft (CM_PCU_Umluftklappe_Status_Cxa_Umluft), 14=Cxe_Init (CM_PCU_Umluftklappe_Status_Cxe_Init), 15=Cxf_Fehler (CM_PCU_Umluftklappe_Status_Cxf_Fehler)}, range raw 0..15, transfer-property=PENDING  # Status Umluftklappe
            signal PCU_Kennlinie_XIX_PCUe_01_XIX_Klima_LIN3: start 52, 2 bit, little-endian, data-type-policy=OVERRIDE, i-signal-type=PRIMITIVE, init-value=0, base-type=BT_PCU_Kennlinie, compu {0=Cx0_PCU_Kennlinie_0 (CM_PCU_Kennlinie_Cx0_PCU_Kennlinie_0), 1=Cx1_PCU_Kennlinie_1 (CM_PCU_Kennlinie_Cx1_PCU_Kennlinie_1), 2=Cx2_PCU_Kennlinie_2 (CM_PCU_Kennlinie_Cx2_PCU_Kennlinie_2), 3=Cx3_PCU_Kennlinie_3 (CM_PCU_Kennlinie_Cx3_PCU_Kennlinie_3)}, range raw 0..3, transfer-property=PENDING  # Kennlinienanpassung an unterschiedliche Emittereinheiten (Charging Unit)
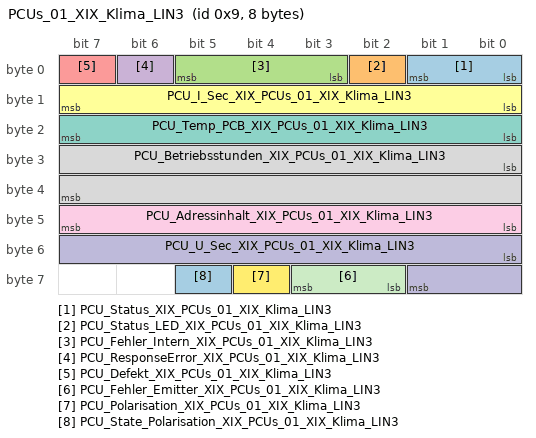
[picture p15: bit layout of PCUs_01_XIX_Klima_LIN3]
        frame PCUs_01_XIX_Klima_LIN3: id 0x9, to Klima, frame-length=8, lin-checksum=ENHANCED
          pdu PCUs_01_XIX_Klima_LIN3: length=8, unused-bit-pattern=0
            signal PCU_Status_XIX_PCUs_01_XIX_Klima_LIN3: start 0, 2 bit, little-endian, data-type-policy=OVERRIDE, i-signal-type=PRIMITIVE, init-value=2, base-type=BT_PCU_Status, compu {0=Cx0_Hochspannung_ausgeschaltet (CM_PCU_Status_Cx0_Hochspannung_ausgeschaltet), 1=Cx1_Hochspannung_eingeschaltet (CM_PCU_Status_Cx1_Hochspannung_eingeschaltet), 2=Cx2_Init (CM_PCU_Status_Cx2_Init)}, range raw 0..2, transfer-property=PENDING, to Klima(timeout 3.5 s)
            signal PCU_Status_LED_XIX_PCUs_01_XIX_Klima_LIN3: start 2, 1 bit, little-endian, data-type-policy=OVERRIDE, i-signal-type=PRIMITIVE, init-value=0, base-type=BT_PCU_Status_LED, compu {0=Cx0_Aus (CM_PCU_Status_LED_Cx0_Aus), 1=Cx1_Ein (CM_PCU_Status_LED_Cx1_Ein)}, range raw 0..1, transfer-property=PENDING, to Klima(timeout 3.5 s)  # Status Funktions LED
            signal PCU_Fehler_Intern_XIX_PCUs_01_XIX_Klima_LIN3: start 3, 3 bit, little-endian, data-type-policy=OVERRIDE, i-signal-type=PRIMITIVE, init-value=0, base-type=BT_PCU_Fehler_Intern, compu {0=Cx0_kein_Fehler (CM_PCU_Fehler_Intern_Cx0_kein_Fehler), 1=Cx1_RAM_ROM_Check_Fehler (CM_PCU_Fehler_Intern_Cx1_RAM_ROM_Check_Fehler) (RAM/ROM_Check_Fehler), 2=Cx2_Fehler_in_Hochspannungserzeugung (CM_PCU_Fehler_Intern_Cx2_Fehler_in_Hochspannungserzeugung), 3=Cx3_n_d (CM_PCU_Fehler_Intern_Cx3_n_d) (n.d.), 4=Cx4_Watchdog_Reset (CM_PCU_Fehler_Intern_Cx4_Watchdog_Reset), 5=Cx5_n_d (CM_PCU_Fehler_Intern_Cx5_n_d) (n.d.), 6=Cx6_n_d (CM_PCU_Fehler_Intern_Cx6_n_d) (n.d.), 7=Cx7_n_d (CM_PCU_Fehler_Intern_Cx7_n_d) (n.d.)}, range raw 0..7, transfer-property=PENDING, to Klima(timeout 3.5 s)  # Fehlerstatus ECU
            signal PCU_ResponseError_XIX_PCUs_01_XIX_Klima_LIN3: start 6, 1 bit, little-endian, data-type-policy=OVERRIDE, i-signal-type=PRIMITIVE, init-value=0, base-type=BT_PCU_ResponseError, invalid-value=Invalid_PCU_ResponseError_XIX_PCUs_01_XIX_Klima_LIN3:1, compu {0=Cx0_normal (CM_PCU_ResponseError_Cx0_normal), 1=Cx1_Fehler (CM_PCU_ResponseError_Cx1_Fehler)}, range raw 0..1, transfer-property=PENDING, to Klima(timeout 3.5 s)
            signal PCU_Defekt_XIX_PCUs_01_XIX_Klima_LIN3: start 7, 1 bit, little-endian, data-type-policy=OVERRIDE, i-signal-type=PRIMITIVE, init-value=0, base-type=BT_PCU_Defekt, compu {0=Cx0_ok (CM_PCU_Defekt_Cx0_ok), 1=Cx1_Defekt (CM_PCU_Defekt_Cx1_Defekt)}, range raw 0..1, transfer-property=PENDING, to Klima(timeout 3.5 s)
            signal PCU_I_Sec_XIX_PCUs_01_XIX_Klima_LIN3: start 8, 8 bit, little-endian, data-type-policy=OVERRIDE, i-signal-type=PRIMITIVE, init-value=254, base-type=BT_PCU_I_Sec, invalid-value=Invalid_PCU_I_Sec_XIX_PCUs_01_XIX_Klima_LIN3:255, compu {phys=raw*2e-07 for raw 0..250, 254=Cxfe_Init (CM_PCU_I_Sec_Cxfe_Init), 255=Cxff_Fehler (CM_PCU_I_Sec_Cxff_Fehler); unit Unit_Amper}, range phys 0..5e-05 Unit_Amper, raw 0..255, unit=Unit_Amper, transfer-property=PENDING, to Klima(timeout 3.5 s)  # Sekundärstrom PCU
            signal PCU_Temp_PCB_XIX_PCUs_01_XIX_Klima_LIN3: start 16, 8 bit, little-endian, data-type-policy=OVERRIDE, i-signal-type=PRIMITIVE, init-value=254, base-type=BT_PCU_Temp_PCB, invalid-value=Invalid_PCU_Temp_PCB_XIX_PCUs_01_XIX_Klima_LIN3:255, compu {phys=raw-40 for raw 0..200, 254=Cxfe_Init (CM_PCU_Temp_PCB_Cxfe_Init), 255=Cxff_Fehler (CM_PCU_Temp_PCB_Cxff_Fehler); unit Unit_DegreCelsi}, range phys -40..160 Unit_DegreCelsi, raw 0..255, unit=Unit_DegreCelsi, transfer-property=PENDING, to Klima(timeout 3.5 s)  # PCU PCB Temperatur
            signal PCU_Betriebsstunden_XIX_PCUs_01_XIX_Klima_LIN3: start 24, 16 bit, little-endian, data-type-policy=OVERRIDE, i-signal-type=PRIMITIVE, init-value=65534, base-type=BT_PCU_Betriebsstunden, invalid-value=Invalid_PCU_Betriebsstunden_XIX_PCUs_01_XIX_Klima_LIN3:65535, compu {phys=raw for raw 0..65533, 65534=Cxfffe_Init (CM_PCU_Betriebsstunden_Cxfffe_Init), 65535=Cxffff_Fehler (CM_PCU_Betriebsstunden_Cxffff_Fehler); unit Unit_Hours}, range phys 0..65533 Unit_Hours, raw 0..65535, unit=Unit_Hours, transfer-property=PENDING, to Klima(timeout 3.5 s)  # Betriebsstundenzaehler PCU
            signal PCU_Adressinhalt_XIX_PCUs_01_XIX_Klima_LIN3: start 40, 8 bit, little-endian, data-type-policy=OVERRIDE, i-signal-type=PRIMITIVE, init-value=0, base-type=BT_PCU_Adressinhalt, compu {phys=raw for raw 0..255; unit Unit_None}, range phys 0..255 Unit_None, raw 0..255, unit=Unit_None, transfer-property=PENDING, to Klima(timeout 3.5 s)
            signal PCU_U_Sec_XIX_PCUs_01_XIX_Klima_LIN3: start 48, 10 bit, little-endian, data-type-policy=OVERRIDE, i-signal-type=PRIMITIVE, init-value=1022, base-type=BT_PCU_U_Sec, invalid-value=Invalid_PCU_U_Sec_XIX_PCUs_01_XIX_Klima_LIN3:1023, compu {phys=raw*10 for raw 0..1000, 1022=Cx3fe_Init (CM_PCU_U_Sec_Cx3fe_Init), 1023=Cx3ff_Fehler (CM_PCU_U_Sec_Cx3ff_Fehler); unit Unit_Volt}, range phys 0..10000 Unit_Volt, raw 0..1023, unit=Unit_Volt, transfer-property=PENDING, to Klima(timeout 3.5 s)  # This isgnal describes the PCU_U_Sec
            signal PCU_Fehler_Emitter_XIX_PCUs_01_XIX_Klima_LIN3: start 58, 2 bit, little-endian, data-type-policy=OVERRIDE, i-signal-type=PRIMITIVE, init-value=0, base-type=BT_PCU_Fehler_Emitter, compu {0=Cx0_Init_kein_Fehler (CM_PCU_Fehler_Emitter_Cx0_Init_kein_Fehler), 1=Cx1_Unterbrechung (CM_PCU_Fehler_Emitter_Cx1_Unterbrechung), 2=Cx2_Kurzschluss (CM_PCU_Fehler_Emitter_Cx2_Kurzschluss), 3=Cx3_Stromfluss (CM_PCU_Fehler_Emitter_Cx3_Stromfluss)}, range raw 0..3, transfer-property=PENDING, to Klima(timeout 3.5 s)  # Fehlerstatus Charging Unit
            signal PCU_Polarisation_XIX_PCUs_01_XIX_Klima_LIN3: start 60, 1 bit, little-endian, data-type-policy=OVERRIDE, i-signal-type=PRIMITIVE, init-value=0, base-type=BT_PCU_Polarisation, invalid-value=Invalid_PCU_Polarisation_XIX_PCUs_01_XIX_Klima_LIN3:1, compu {0=Cx0_iO (CM_PCU_Polarisation_Cx0_iO), 1=Cx1_Fehler (CM_PCU_Polarisation_Cx1_Fehler)}, range raw 0..1, transfer-property=PENDING, to Klima(timeout 3.5 s)  # Fehlerstatus Polarisation
            signal PCU_State_Polarisation_XIX_PCUs_01_XIX_Klima_LIN3: start 61, 1 bit, little-endian, data-type-policy=OVERRIDE, i-signal-type=PRIMITIVE, init-value=0, base-type=BT_PCU_State_Polarisation, compu {0=Cx0_verbaut (CM_PCU_State_Polarisation_Cx0_verbaut), 1=Cx1_nicht_verbaut (CM_PCU_State_Polarisation_Cx1_nicht_verbaut)}, range raw 0..1, transfer-property=PENDING, to Klima(timeout 3.5 s)  # Betriebsstatus Polarisation
        frame SlaveResp_XIX_Klima_LIN3: id 0x3D, to Klima, frame-length=8, lin-checksum=CLASSIC
          n pdu SlaveResp_XIX_Klima_LIN3: length=8
        pdu triggering PT_Klima_LIN3_XIX_TPCHType_LIN_Diagnose_XIX_0x0_XIX_0x{14..16}_XIX_Physical: pdu=DCM_Klima_LIN3_XIX_TPCHType_LIN_Diagnose_XIX_0x0_XIX_0x{14..16}_XIX_Physical, from Klima
        pdu triggering PT_Klima_LIN3_XIX_TPCHType_LIN_Diagnose_XIX_0x0_XIX_0x20_XIX_Physical: pdu=DCM_Klima_LIN3_XIX_TPCHType_LIN_Diagnose_XIX_0x0_XIX_0x20_XIX_Physical, from Klima
        pdu triggering PT_Klima_LIN3_XIX_TPCHType_LIN_Diagnose_XIX_0x0_XIX_0x39_XIX_Physical: pdu=DCM_Klima_LIN3_XIX_TPCHType_LIN_Diagnose_XIX_0x0_XIX_0x39_XIX_Physical, from Klima
        pdu triggering PT_Klima_LIN3_XIX_TPCHType_LIN_Diagnose_XIX_0x0_XIX_0x5E_XIX_Physical: pdu=DCM_Klima_LIN3_XIX_TPCHType_LIN_Diagnose_XIX_0x0_XIX_0x5E_XIX_Physical, from Klima
        pdu triggering PT_Klima_LIN3_XIX_TPCHType_LIN_Diagnose_XIX_0x0_XIX_0x5F_XIX_Physical: pdu=DCM_Klima_LIN3_XIX_TPCHType_LIN_Diagnose_XIX_0x0_XIX_0x5F_XIX_Physical, from Klima
        pdu triggering PT_Klima_LIN3_XIX_TPCHType_LIN_Diagnose_XIX_0x0_XIX_0x61_XIX_Physical: pdu=DCM_Klima_LIN3_XIX_TPCHType_LIN_Diagnose_XIX_0x0_XIX_0x61_XIX_Physical, from Klima
        pdu triggering PT_Klima_LIN3_XIX_TPCHType_LIN_Diagnose_XIX_0x0_XIX_0x63_XIX_Physical: pdu=DCM_Klima_LIN3_XIX_TPCHType_LIN_Diagnose_XIX_0x0_XIX_0x63_XIX_Physical, from Klima
        pdu triggering PT_Klima_LIN3_XIX_TPCHType_LIN_Diagnose_XIX_0x{14..16}_XIX_0x0_XIX_Physical: pdu=DCM_Klima_LIN3_XIX_TPCHType_LIN_Diagnose_XIX_0x{14..16}_XIX_0x0_XIX_Physical, to Klima
        pdu triggering PT_Klima_LIN3_XIX_TPCHType_LIN_Diagnose_XIX_0x20_XIX_0x0_XIX_Physical: pdu=DCM_Klima_LIN3_XIX_TPCHType_LIN_Diagnose_XIX_0x20_XIX_0x0_XIX_Physical, to Klima
        pdu triggering PT_Klima_LIN3_XIX_TPCHType_LIN_Diagnose_XIX_0x39_XIX_0x0_XIX_Physical: pdu=DCM_Klima_LIN3_XIX_TPCHType_LIN_Diagnose_XIX_0x39_XIX_0x0_XIX_Physical, to Klima
        pdu triggering PT_Klima_LIN3_XIX_TPCHType_LIN_Diagnose_XIX_0x5E_XIX_0x0_XIX_Physical: pdu=DCM_Klima_LIN3_XIX_TPCHType_LIN_Diagnose_XIX_0x5E_XIX_0x0_XIX_Physical, to Klima
        pdu triggering PT_Klima_LIN3_XIX_TPCHType_LIN_Diagnose_XIX_0x5F_XIX_0x0_XIX_Physical: pdu=DCM_Klima_LIN3_XIX_TPCHType_LIN_Diagnose_XIX_0x5F_XIX_0x0_XIX_Physical, to Klima
        pdu triggering PT_Klima_LIN3_XIX_TPCHType_LIN_Diagnose_XIX_0x61_XIX_0x0_XIX_Physical: pdu=DCM_Klima_LIN3_XIX_TPCHType_LIN_Diagnose_XIX_0x61_XIX_0x0_XIX_Physical, to Klima
        pdu triggering PT_Klima_LIN3_XIX_TPCHType_LIN_Diagnose_XIX_0x63_XIX_0x0_XIX_Physical: pdu=DCM_Klima_LIN3_XIX_TPCHType_LIN_Diagnose_XIX_0x63_XIX_0x0_XIX_Physical, to Klima
        9 x lin schedule table, all with resume-position=CONTINUE-AT-IT-POSITION:
          DiagFunktionalerRequest: run-mode=RUN-ONCE, application-entry{delay=0.01, position-in-table=0, frame-triggering=FT_ISO_Funktionaler_Req_All}
          DiagRequest: run-mode=RUN-ONCE, application-entry{delay=0.01, position-in-table=0, frame-triggering=CHNL/FT_MasterReq}
          DiagResponse: run-mode=RUN-ONCE, application-entry{delay=0.01, position-in-table=0, frame-triggering=CHNL/FT_SlaveResp}
          st_EKK_Fehler: run-mode=RUN-ONCE, application-entry{delay=0.01, position-in-table=0, frame-triggering=FT_EKK4s_02}
          st_main_1: run-mode=RUN-CONTINUOUS
            table-entrys:
              delay=0.01, position-in-table=0, frame-triggering=FT_EKKe_01
              delay=0.01, position-in-table=1, frame-triggering=FT_DTSs_01
              delay=0.01, position-in-table=2, frame-triggering=FT_PCUe_01
              delay=0.02, position-in-table=3, frame-triggering=FT_HV_He_01
              delay=0.01, position-in-table=4, frame-triggering=FT_EKK4s_01
              delay=0.02, position-in-table=5, frame-triggering=CHNL/FT_EVe_01_Control
              delay=0.01, position-in-table=6, frame-triggering=FT_HV_Hs_01
              delay=0.01, position-in-table=7, frame-triggering=FT_HV_Hs_02
              delay=0.01, position-in-table=8, frame-triggering=FT_EKKe_01
              delay=0.01, position-in-table=9, frame-triggering=FT_DTSs_01
              delay=0.01, position-in-table=10, frame-triggering=FT_PCUs_01
              delay=0.02, position-in-table=11, frame-triggering=FT_HV_He_01
              delay=0.01, position-in-table=12, frame-triggering=FT_EKK4s_01
              delay=0.02, position-in-table=13, frame-triggering=CHNL/FT_EXV1s_01
              delay=0.01, position-in-table=14, frame-triggering=FT_HV_Hs_01
              delay=0.01, position-in-table=15, frame-triggering=FT_HV_Hs_02
          st_main_2: run-mode=RUN-CONTINUOUS
            table-entrys:
              delay=0.01, position-in-table=0, frame-triggering=FT_HV_H3e_01
              delay=0.01, position-in-table=1, frame-triggering=FT_EKKe_01
              delay=0.01, position-in-table=2, frame-triggering=FT_DTSs_01
              delay=0.01, position-in-table=3, frame-triggering=FT_BLOWERe_01
              delay=0.01, position-in-table=4, frame-triggering=FT_PCUe_01
              delay=0.01, position-in-table=5, frame-triggering=FT_HV_H3s_01
              delay=0.01, position-in-table=6, frame-triggering=FT_EKK4s_01
              delay=0.02, position-in-table=7, frame-triggering=CHNL/FT_EVe_01_Control
              delay=0.01, position-in-table=8, frame-triggering=FT_HV_He_01
              delay=0.01, position-in-table=9, frame-triggering=FT_HV_H3e_01
              delay=0.01, position-in-table=10, frame-triggering=FT_EKKe_01
              delay=0.01, position-in-table=11, frame-triggering=FT_DTSs_01
              delay=0.01, position-in-table=12, frame-triggering=FT_BLOWERs_01
              delay=0.01, position-in-table=13, frame-triggering=FT_PCUs_01
              delay=0.01, position-in-table=14, frame-triggering=FT_HV_H3s_01
              delay=0.01, position-in-table=15, frame-triggering=FT_EKK4s_01
              delay=0.01, position-in-table=16, frame-triggering=CHNL/FT_EXV1s_01
              delay=0.01, position-in-table=17, frame-triggering=FT_BLOWERs_02
              delay=0.01, position-in-table=18, frame-triggering=FT_HV_H2s_01
          st_main_3: run-mode=RUN-CONTINUOUS
            table-entrys:
              delay=0.01, position-in-table=0, frame-triggering=FT_HV_H3e_01
              delay=0.01, position-in-table=1, frame-triggering=FT_EKKe_01
              delay=0.01, position-in-table=2, frame-triggering=FT_HV_He_01
              delay=0.01, position-in-table=3, frame-triggering=FT_BLOWERe_01
              delay=0.01, position-in-table=4, frame-triggering=FT_PCUe_01
              delay=0.01, position-in-table=5, frame-triggering=FT_HV_H3s_01
              delay=0.04, position-in-table=6, frame-triggering=FT_EKK4s_01
              delay=0.01, position-in-table=7, frame-triggering=FT_HV_H3e_01
              delay=0.01, position-in-table=8, frame-triggering=FT_EKKe_01
              delay=0.01, position-in-table=9, frame-triggering=FT_HV_H2s_01
              delay=0.01, position-in-table=10, frame-triggering=FT_BLOWERs_01
              delay=0.01, position-in-table=11, frame-triggering=FT_PCUs_01
              delay=0.01, position-in-table=12, frame-triggering=FT_HV_H3s_01
              delay=0.02, position-in-table=13, frame-triggering=FT_EKK4s_01
              delay=0.02, position-in-table=14, frame-triggering=FT_BLOWERs_02
          st_main_4: run-mode=RUN-CONTINUOUS
            table-entrys:
              delay=0.01, position-in-table=0, frame-triggering=FT_HV_H6e_01
              delay=0.01, position-in-table=1, frame-triggering=FT_EKKe_01
              delay=0.01, position-in-table=2, frame-triggering=FT_DTSs_01
              delay=0.01, position-in-table=3, frame-triggering=FT_BLOWERe_01
              delay=0.01, position-in-table=4, frame-triggering=FT_DTSs_02
              delay=0.01, position-in-table=5, frame-triggering=FT_HV_H6s_01
              delay=0.01, position-in-table=6, frame-triggering=FT_EKK4s_01
              delay=0.02, position-in-table=7, frame-triggering=CHNL/FT_EVe_01_Control
              delay=0.01, position-in-table=8, frame-triggering=FT_DTSs_03
              delay=0.01, position-in-table=9, frame-triggering=FT_HV_H6e_01
              delay=0.01, position-in-table=10, frame-triggering=FT_EKKe_01
              delay=0.01, position-in-table=11, frame-triggering=FT_DTSs_01
              delay=0.01, position-in-table=12, frame-triggering=FT_BLOWERs_01
              delay=0.01, position-in-table=13, frame-triggering=FT_DTSs_02
              delay=0.01, position-in-table=14, frame-triggering=FT_HV_H6s_01
              delay=0.01, position-in-table=15, frame-triggering=FT_EKK4s_01
              delay=0.01, position-in-table=16, frame-triggering=CHNL/FT_EXV1s_01
              delay=0.01, position-in-table=17, frame-triggering=FT_BLOWERs_02
              delay=0.01, position-in-table=18, frame-triggering=FT_DTSs_03
          st_main_5: run-mode=RUN-CONTINUOUS
            table-entrys:
              delay=0.01, position-in-table=0, frame-triggering=FT_HV_H6e_01
              delay=0.02, position-in-table=1, frame-triggering=FT_EKKe_01
              delay=0.02, position-in-table=2, frame-triggering=FT_BLOWERe_01
              delay=0.01, position-in-table=3, frame-triggering=FT_HV_H6s_01
              delay=0.04, position-in-table=4, frame-triggering=FT_EKK4s_01
              delay=0.01, position-in-table=5, frame-triggering=FT_HV_H6e_01
              delay=0.02, position-in-table=6, frame-triggering=FT_EKKe_01
              delay=0.02, position-in-table=7, frame-triggering=FT_BLOWERs_01
              delay=0.01, position-in-table=8, frame-triggering=FT_HV_H6s_01
              delay=0.02, position-in-table=9, frame-triggering=FT_EKK4s_01
              delay=0.02, position-in-table=10, frame-triggering=FT_BLOWERs_02
